[part 3 of 12: package /E40_Platform_System_SystemPackage/Components]
AUTOSAR XML (schema 4-2-1)
package /E40_Platform_System_SystemPackage/Components  (continued)
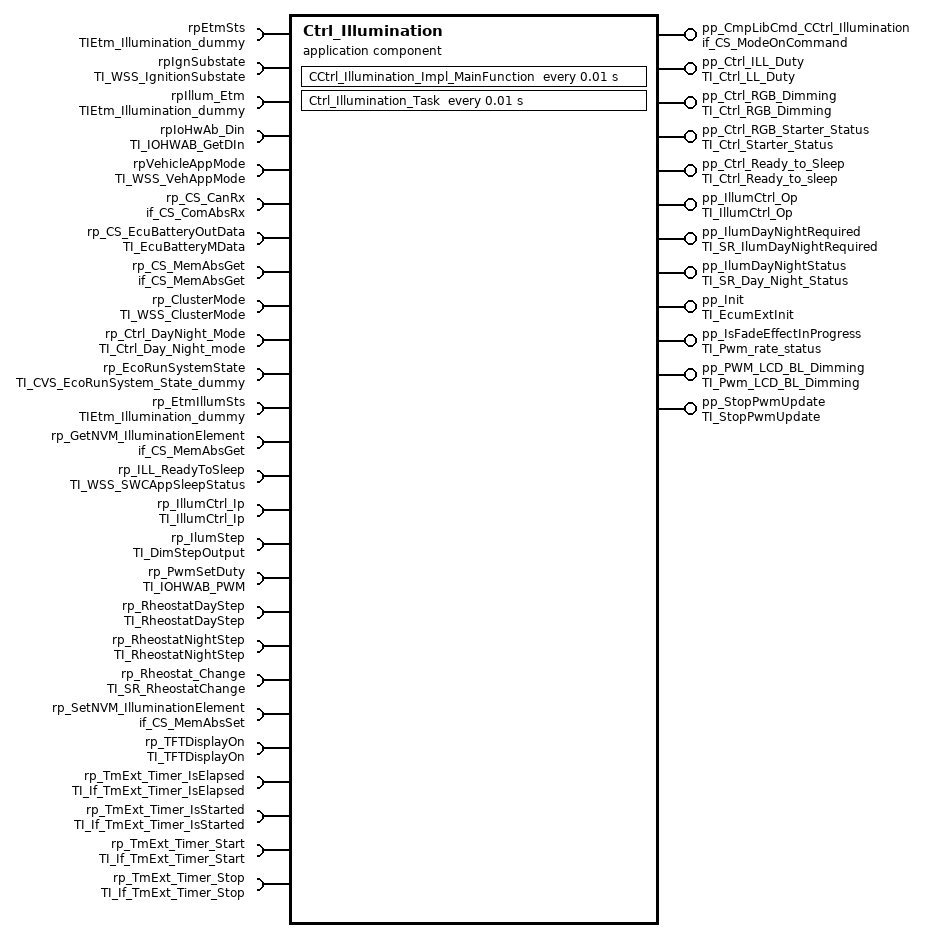
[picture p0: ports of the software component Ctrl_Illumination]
  application sw component type Ctrl_Illumination
    12 x provide port:
      pp_CmpLibCmd_CCtrl_Illumination: server-com-spec{operation=Impl_OnCommand, queue-length=1}, provided-interface=if_CS_ModeOnCommand
      pp_Ctrl_ILL_Duty: nonqueued-sender-com-spec{data-element=ILL_Duty, init-value=constant-reference=Ctrl_IlluminationILL_DutyValue0}, provided-interface=TI_Ctrl_LL_Duty
      pp_Ctrl_RGB_Dimming: nonqueued-sender-com-spec{data-element=RGB_Dimming, init-value=constant-reference=Ctrl_IlluminationRGB_DimmingValue0}, provided-interface=TI_Ctrl_RGB_Dimming
      pp_Ctrl_RGB_Starter_Status: nonqueued-sender-com-spec{data-element=Starter_Status, uses-end-to-end-protection=0, init-value=constant-reference=Ctrl_IlluminationStarter_StatusValue0}, provided-interface=TI_Ctrl_Starter_Status
      pp_Ctrl_Ready_to_Sleep: nonqueued-sender-com-spec{data-element=Ready_to_Sleep, uses-end-to-end-protection=0, init-value=constant-reference=Ctrl_IlluminationReady_to_SleepValue0}, provided-interface=TI_Ctrl_Ready_to_sleep
      pp_IllumCtrl_Op: nonqueued-sender-com-spec{data-element=IllumCtrl_Op_Data, init-value=constant-reference=Ctrl_IlluminationIllumCtrl_Op_DataValue0}, provided-interface=TI_IllumCtrl_Op
      pp_IlumDayNightRequired: nonqueued-sender-com-spec{data-element=IlumDayNightRequired, init-value=constant-reference=Ctrl_IlluminationIlumDayNightRequiredValue0}, provided-interface=TI_SR_IlumDayNightRequired
      pp_IlumDayNightStatus: nonqueued-sender-com-spec{data-element=Day_Night_Status, init-value=constant-reference=Ctrl_IlluminationDay_Night_StatusValue0}, provided-interface=TI_SR_Day_Night_Status
      pp_Init: server-com-spec{operation=TI_EcumExtInit/Init, queue-length=1}, provided-interface=TI_EcumExtInit
      pp_IsFadeEffectInProgress: server-com-spec{operation=PWM_Rate_Status, queue-length=1}, provided-interface=TI_Pwm_rate_status
      pp_PWM_LCD_BL_Dimming: nonqueued-sender-com-spec{data-element=BL_Dimming, init-value=constant-reference=Ctrl_IlluminationBL_DimmingValue0}, provided-interface=TI_Pwm_LCD_BL_Dimming
      pp_StopPwmUpdate: nonqueued-sender-com-spec{data-element=channel_id, init-value=constant-reference=Ctrl_Illuminationchannel_idValue0}, provided-interface=TI_StopPwmUpdate
    26 x require port:
      rpEtmSts: nonqueued-receiver-com-spec{data-element=IllumStatus, init-value=constant-reference=Ctrl_IlluminationIllumStatusValue0}, required-interface=TIEtm_Illumination_dummy
      rpIgnSubstate: nonqueued-receiver-com-spec{data-element=IgnitionSubstate, init-value=constant-reference=Ctrl_IlluminationIgnitionSubstateValue0}, required-interface=TI_WSS_IgnitionSubstate
      rpIllum_Etm: nonqueued-receiver-com-spec{data-element=IllumStatus, init-value=constant-reference=Ctrl_IlluminationIllumStatusValue0}, required-interface=TIEtm_Illumination_dummy
      rpIoHwAb_Din: required-interface=TI_IOHWAB_GetDIn
      rpVehicleAppMode: nonqueued-receiver-com-spec{data-element=WSSCurrentVehicleState, init-value=constant-reference=Ctrl_IlluminationWSSCurrentVehicleStateValue0}, required-interface=TI_WSS_VehAppMode
      rp_CS_CanRx: required-interface=if_CS_ComAbsRx
      rp_CS_EcuBatteryOutData: required-interface=TI_EcuBatteryMData
      rp_CS_MemAbsGet: required-interface=if_CS_MemAbsGet
      rp_ClusterMode: nonqueued-receiver-com-spec{data-element=WSSCurrentClusterMode, init-value=constant-reference=Ctrl_IlluminationWSSCurrentClusterModeValue0}, required-interface=TI_WSS_ClusterMode
      rp_Ctrl_DayNight_Mode: nonqueued-receiver-com-spec{data-element=Day_Night_mode_Ctrl, init-value=constant-reference=Ctrl_IlluminationDay_Night_mode_CtrlValue0}, required-interface=TI_Ctrl_Day_Night_mode
      rp_EcoRunSystemState: nonqueued-receiver-com-spec{data-element=EcoRunSystem_Flag, init-value=constant-reference=Ctrl_IlluminationEcoRunSystem_FlagValue0}, required-interface=TI_CVS_EcoRunSystem_State_dummy
      rp_EtmIllumSts: nonqueued-receiver-com-spec{data-element=IllumStatus, init-value=constant-reference=Ctrl_IlluminationIllumStatusValue0}, required-interface=TIEtm_Illumination_dummy
      rp_GetNVM_IlluminationElement: required-interface=if_CS_MemAbsGet
      rp_ILL_ReadyToSleep: required-interface=TI_WSS_SWCAppSleepStatus
      rp_IllumCtrl_Ip: nonqueued-receiver-com-spec{data-element=IllumCtrl_Ip_Data, init-value=constant-reference=Ctrl_IlluminationIllumCtrl_Ip_DataValue0}, required-interface=TI_IllumCtrl_Ip
      rp_IlumStep: nonqueued-receiver-com-spec{data-element=IllumStepValue, init-value=constant-reference=Ctrl_IlluminationIllumStepValueValue0}, required-interface=TI_DimStepOutput
      rp_PwmSetDuty: required-interface=TI_IOHWAB_PWM
      rp_RheostatDayStep: nonqueued-receiver-com-spec{data-element=RheostatDayStep, init-value=constant-reference=Ctrl_IlluminationRheostatDayStepValue0}, required-interface=TI_RheostatDayStep
      rp_RheostatNightStep: nonqueued-receiver-com-spec{data-element=RheostatNightStep, init-value=constant-reference=Ctrl_IlluminationRheostatNightStepValue0}, required-interface=TI_RheostatNightStep
      rp_Rheostat_Change: nonqueued-receiver-com-spec{data-element=RheoUpdateVal, init-value=constant-reference=Ctrl_IlluminationRheoUpdateValValue0}, required-interface=TI_SR_RheostatChange
      rp_SetNVM_IlluminationElement: required-interface=if_CS_MemAbsSet
      rp_TFTDisplayOn: nonqueued-receiver-com-spec{data-element=TFTDisplayOn, init-value=constant-reference=Ctrl_IlluminationTFTDisplayOnValue0}, required-interface=TI_TFTDisplayOn
      rp_TmExt_Timer_IsElapsed: required-interface=TI_If_TmExt_Timer_IsElapsed
      rp_TmExt_Timer_IsStarted: required-interface=TI_If_TmExt_Timer_IsStarted
      rp_TmExt_Timer_Start: required-interface=TI_If_TmExt_Timer_Start
      rp_TmExt_Timer_Stop: required-interface=TI_If_TmExt_Timer_Stop
    behavior IB_Ctrl_Illumination
      timing event TECCtrl_Illumination_Impl_MainFunction: start-on-event=CCtrl_Illumination_Impl_MainFunction, period=0.01
      operation invoked event OIE_pp_CmpLibCmd_CCtrl_Illumination_CCtrl_Illumination_Impl_OnCommandTrigByImpl_OnCommand: start-on-event=CCtrl_Illumination_Impl_OnCommand, operation=pp_CmpLibCmd_CCtrl_Illumination.Impl_OnCommand
      operation invoked event OIE_pp_Init_Ctrl_Illumination_InitTrigByInit: start-on-event=Ctrl_Illumination_Init, operation=pp_Init.Init
      operation invoked event OIE_pp_IsFadeEffectInProgress_Ctrl_Illumination_PWM_Rate_StatusTrigByPWM_Rate_Status: start-on-event=Ctrl_Illumination_PWM_Rate_Status, operation=pp_IsFadeEffectInProgress.PWM_Rate_Status
      timing event TECtrl_Illumination_Task: start-on-event=Ctrl_Illumination_Task, period=0.01
      port-api-options:
        enable-take-address=false, indirect-api=false, port=pp_CmpLibCmd_CCtrl_Illumination
        enable-take-address=false, indirect-api=false, port=pp_Ctrl_ILL_Duty
        enable-take-address=false, indirect-api=false, port=pp_Ctrl_RGB_Dimming
        enable-take-address=false, indirect-api=false, port=pp_Ctrl_RGB_Starter_Status
        enable-take-address=false, indirect-api=false, port=pp_Ctrl_Ready_to_Sleep
        enable-take-address=false, indirect-api=false, port=pp_IllumCtrl_Op
        enable-take-address=false, indirect-api=false, port=Ctrl_Illumination/pp_IlumDayNightRequired
        enable-take-address=false, indirect-api=false, port=Ctrl_Illumination/pp_IlumDayNightStatus
        enable-take-address=false, indirect-api=false, port=Ctrl_Illumination/pp_Init
        enable-take-address=false, indirect-api=false, port=pp_IsFadeEffectInProgress
        enable-take-address=false, indirect-api=false, port=pp_PWM_LCD_BL_Dimming
        enable-take-address=false, indirect-api=false, port=pp_StopPwmUpdate
        enable-take-address=false, indirect-api=false, port=Ctrl_Illumination/rpEtmSts
        enable-take-address=false, indirect-api=false, port=Ctrl_Illumination/rpIgnSubstate
        enable-take-address=false, indirect-api=false, port=Ctrl_Illumination/rpIllum_Etm
        enable-take-address=false, indirect-api=false, port=Ctrl_Illumination/rpIoHwAb_Din
        enable-take-address=false, indirect-api=false, port=Ctrl_Illumination/rpVehicleAppMode
        enable-take-address=false, indirect-api=false, port=Ctrl_Illumination/rp_CS_CanRx
        enable-take-address=false, indirect-api=false, port=Ctrl_Illumination/rp_CS_EcuBatteryOutData
        enable-take-address=false, indirect-api=false, port=Ctrl_Illumination/rp_CS_MemAbsGet
        enable-take-address=false, indirect-api=false, port=Ctrl_Illumination/rp_ClusterMode
        enable-take-address=false, indirect-api=false, port=rp_Ctrl_DayNight_Mode
        enable-take-address=false, indirect-api=false, port=Ctrl_Illumination/rp_EcoRunSystemState
        enable-take-address=false, indirect-api=false, port=Ctrl_Illumination/rp_EtmIllumSts
        enable-take-address=false, indirect-api=false, port=Ctrl_Illumination/rp_GetNVM_IlluminationElement
        enable-take-address=false, indirect-api=false, port=Ctrl_Illumination/rp_ILL_ReadyToSleep
        enable-take-address=false, indirect-api=false, port=rp_IllumCtrl_Ip
        enable-take-address=false, indirect-api=false, port=rp_IlumStep
        enable-take-address=false, indirect-api=false, port=Ctrl_Illumination/rp_PwmSetDuty
        enable-take-address=false, indirect-api=false, port=Ctrl_Illumination/rp_RheostatDayStep
        enable-take-address=false, indirect-api=false, port=Ctrl_Illumination/rp_RheostatNightStep
        enable-take-address=false, indirect-api=false, port=Ctrl_Illumination/rp_Rheostat_Change
        enable-take-address=false, indirect-api=false, port=Ctrl_Illumination/rp_SetNVM_IlluminationElement
        enable-take-address=false, indirect-api=false, port=Ctrl_Illumination/rp_TFTDisplayOn
        enable-take-address=false, indirect-api=false, port=Ctrl_Illumination/rp_TmExt_Timer_IsElapsed
        enable-take-address=false, indirect-api=false, port=Ctrl_Illumination/rp_TmExt_Timer_IsStarted
        enable-take-address=false, indirect-api=false, port=Ctrl_Illumination/rp_TmExt_Timer_Start
        enable-take-address=false, indirect-api=false, port=Ctrl_Illumination/rp_TmExt_Timer_Stop
      5 x runnable, all with can-be-invoked-concurrently=true:
        CCtrl_Illumination_Impl_MainFunction
          data-receive-point-by-arguments:
            14 x access:
              DRA_rpEtmSts_IllumStatus: accessed-variable=rpEtmSts.IllumStatus
              DRA_rpIgnSubstate_IgnitionSubstate: accessed-variable=rpIgnSubstate.IgnitionSubstate
              DRA_rpIllum_Etm_IllumStatus: accessed-variable=rpIllum_Etm.IllumStatus
              DRA_rpVehicleAppMode_WSSCurrentVehicleState: accessed-variable=rpVehicleAppMode.WSSCurrentVehicleState
              DRA_rp_ClusterMode_WSSCurrentClusterMode: accessed-variable=rp_ClusterMode.WSSCurrentClusterMode
              DRA_rp_Ctrl_DayNight_Mode_Day_Night_mode_Ctrl: accessed-variable=rp_Ctrl_DayNight_Mode.Day_Night_mode_Ctrl
              DRA_rp_EcoRunSystemState_EcoRunSystem_Flag: accessed-variable=rp_EcoRunSystemState.EcoRunSystem_Flag
              DRA_rp_EtmIllumSts_IllumStatus: accessed-variable=rp_EtmIllumSts.IllumStatus
              DRA_rp_IllumCtrl_Ip_IllumCtrl_Ip_Data: accessed-variable=rp_IllumCtrl_Ip.IllumCtrl_Ip_Data
              DRA_rp_IlumStep_IllumStepValue: accessed-variable=rp_IlumStep.IllumStepValue
              DRA_rp_RheostatDayStep_RheostatDayStep: accessed-variable=rp_RheostatDayStep.RheostatDayStep
              DRA_rp_RheostatNightStep_RheostatNightStep: accessed-variable=rp_RheostatNightStep.RheostatNightStep
              DRA_rp_Rheostat_Change_RheoUpdateVal: accessed-variable=rp_Rheostat_Change.RheoUpdateVal
              DRA_rp_TFTDisplayOn_TFTDisplayOn: accessed-variable=rp_TFTDisplayOn.TFTDisplayOn
          data-send-points:
            9 x access:
              DWA_pp_Ctrl_ILL_Duty_ILL_Duty: accessed-variable=pp_Ctrl_ILL_Duty.ILL_Duty
              DWA_pp_Ctrl_RGB_Dimming_RGB_Dimming: accessed-variable=pp_Ctrl_RGB_Dimming.RGB_Dimming
              DWA_pp_Ctrl_RGB_Starter_Status_Starter_Status: accessed-variable=pp_Ctrl_RGB_Starter_Status.Starter_Status
              DWA_pp_Ctrl_Ready_to_Sleep_Ready_to_Sleep: accessed-variable=pp_Ctrl_Ready_to_Sleep.Ready_to_Sleep
              DWA_pp_IllumCtrl_Op_IllumCtrl_Op_Data: accessed-variable=pp_IllumCtrl_Op.IllumCtrl_Op_Data
              DWA_pp_IlumDayNightRequired_IlumDayNightRequired: accessed-variable=pp_IlumDayNightRequired.IlumDayNightRequired
              DWA_pp_IlumDayNightStatus_Day_Night_Status: accessed-variable=pp_IlumDayNightStatus.Day_Night_Status
              DWA_pp_PWM_LCD_BL_Dimming_BL_Dimming: accessed-variable=pp_PWM_LCD_BL_Dimming.BL_Dimming
              DWA_pp_StopPwmUpdate_channel_id: accessed-variable=pp_StopPwmUpdate.channel_id
          305 x sync call, all with timeout=0.0:
            OA_rpIoHwAb_Din_GetAsyncRawInput: operation=rpIoHwAb_Din.GetAsyncRawInput
            OA_rpIoHwAb_Din_GetProcessedInput: operation=rpIoHwAb_Din.GetProcessedInput
            OA_rpIoHwAb_Din_GetSyncRawInput: operation=rpIoHwAb_Din.GetSyncRawInput
            OA_rpIoHwAb_Din_GetInputGroup: operation=rpIoHwAb_Din.GetInputGroup
            OA_rp_CS_CanRx_RxCan_GetSignalValueU8Arr: operation=rp_CS_CanRx.RxCan_GetSignalValueU8Arr
            OA_rp_CS_CanRx_RxCan_SetSignalInitValue: operation=rp_CS_CanRx.RxCan_SetSignalInitValue
            OA_rp_CS_CanRx_RxCan_SetSignalInitValueU8Arr: operation=rp_CS_CanRx.RxCan_SetSignalInitValueU8Arr
            OA_rp_CS_CanRx_RxCan_SignalInvalidProcessingControl: operation=rp_CS_CanRx.RxCan_SignalInvalidProcessingControl
            OA_rp_CS_CanRx_RxCan_SignalMissingProcessingControl: operation=rp_CS_CanRx.RxCan_SignalMissingProcessingControl
            OA_rp_CS_CanRx_RxCan_SignalNRProcessingControl: operation=rp_CS_CanRx.RxCan_SignalNRProcessingControl
            OA_rp_CS_CanRx_RxCan_SignalGetJustRcvdStatus: operation=rp_CS_CanRx.RxCan_SignalGetJustRcvdStatus
            OA_rp_CS_CanRx_RxCan_SignalClearJustRcvdStatus: operation=rp_CS_CanRx.RxCan_SignalClearJustRcvdStatus
            OA_rp_CS_CanRx_RxCan_GetSignalValue: operation=rp_CS_CanRx.RxCan_GetSignalValue
            OA_rp_CS_EcuBatteryOutData_EcuBatteryM_GetChannelStatus: operation=rp_CS_EcuBatteryOutData.EcuBatteryM_GetChannelStatus
            OA_rp_CS_EcuBatteryOutData_EcuBatteryM_GetDIOStatus: operation=rp_CS_EcuBatteryOutData.EcuBatteryM_GetDIOStatus
            OA_rp_CS_MemAbsGet_Get_BsShare_SwUpdReflash_Element: operation=rp_CS_MemAbsGet.Get_BsShare_SwUpdReflash_Element
            OA_rp_CS_MemAbsGet_Get_BsShare_SwUpdFotaMode_Element: operation=rp_CS_MemAbsGet.Get_BsShare_SwUpdFotaMode_Element
            OA_rp_CS_MemAbsGet_Get_BsShare_SwUpdFotaFinPrint_Element: operation=rp_CS_MemAbsGet.Get_BsShare_SwUpdFotaFinPrint_Element
            OA_rp_CS_MemAbsGet_Get_BsShare_SwUpdFotaStatus_Element: operation=rp_CS_MemAbsGet.Get_BsShare_SwUpdFotaStatus_Element
            OA_rp_CS_MemAbsGet_Get_BsShare_SwUpdFotadecrypt_Element: operation=rp_CS_MemAbsGet.Get_BsShare_SwUpdFotadecrypt_Element
            OA_rp_CS_MemAbsGet_Get_BsShare_EcuPartNumber_Element: operation=rp_CS_MemAbsGet.Get_BsShare_EcuPartNumber_Element
            OA_rp_CS_MemAbsGet_Get_BsShare_VisteonPartNumber: operation=rp_CS_MemAbsGet.Get_BsShare_VisteonPartNumber
            OA_rp_CS_MemAbsGet_Get_BsShare_VisteonPCBPartNumber: operation=rp_CS_MemAbsGet.Get_BsShare_VisteonPCBPartNumber
            OA_rp_CS_MemAbsGet_Get_BsShare_ProductSerialNumber: operation=rp_CS_MemAbsGet.Get_BsShare_ProductSerialNumber
            OA_rp_CS_MemAbsGet_Get_BsShare_PCBSerialNumber: operation=rp_CS_MemAbsGet.Get_BsShare_PCBSerialNumber
            OA_rp_CS_MemAbsGet_Get_BsShare_SMTManufacturingDate: operation=rp_CS_MemAbsGet.Get_BsShare_SMTManufacturingDate
            OA_rp_CS_MemAbsGet_Get_BsShare_AssemblyManufacturingDate: operation=rp_CS_MemAbsGet.Get_BsShare_AssemblyManufacturingDate
            OA_rp_CS_MemAbsGet_Get_BsShare_SMTPlantNumber: operation=rp_CS_MemAbsGet.Get_BsShare_SMTPlantNumber
            OA_rp_CS_MemAbsGet_Get_BsShare_AssemblyPlantNumber: operation=rp_CS_MemAbsGet.Get_BsShare_AssemblyPlantNumber
            OA_rp_CS_MemAbsGet_Get_BsShare_HWModification: operation=rp_CS_MemAbsGet.Get_BsShare_HWModification
            OA_rp_CS_MemAbsGet_Get_BsShare_VisMeet_Element: operation=rp_CS_MemAbsGet.Get_BsShare_VisMeet_Element
            OA_rp_CS_MemAbsGet_Get_BsShare_VisMeet_EOLEntry_Element: operation=rp_CS_MemAbsGet.Get_BsShare_VisMeet_EOLEntry_Element
            OA_rp_CS_MemAbsGet_Get_BsShare_VehicleConfig_Element: operation=rp_CS_MemAbsGet.Get_BsShare_VehicleConfig_Element
            OA_rp_CS_MemAbsGet_Get_BsConst_SpeedoGauge_Element: operation=rp_CS_MemAbsGet.Get_BsConst_SpeedoGauge_Element
            OA_rp_CS_MemAbsGet_Get_BsConst_TachoGauge_Element: operation=rp_CS_MemAbsGet.Get_BsConst_TachoGauge_Element
            OA_rp_CS_MemAbsGet_Get_BsConst_FuelGauge_Element: operation=rp_CS_MemAbsGet.Get_BsConst_FuelGauge_Element
            OA_rp_CS_MemAbsGet_Get_BsConst_TempGauge_Element: operation=rp_CS_MemAbsGet.Get_BsConst_TempGauge_Element
            OA_rp_CS_MemAbsGet_Get_BsConst_PowerGauge_Element: operation=rp_CS_MemAbsGet.Get_BsConst_PowerGauge_Element
            OA_rp_CS_MemAbsGet_Get_BsConst_OilGauge_Element: operation=rp_CS_MemAbsGet.Get_BsConst_OilGauge_Element
            OA_rp_CS_MemAbsGet_Get_BsConst_TripComputer_Element: operation=rp_CS_MemAbsGet.Get_BsConst_TripComputer_Element
            OA_rp_CS_MemAbsGet_Get_BsConst_Compensation_Line_Slope_m: operation=rp_CS_MemAbsGet.Get_BsConst_Compensation_Line_Slope_m
            OA_rp_CS_MemAbsGet_Get_BsConst_Compensation_Line_Shift_b: operation=rp_CS_MemAbsGet.Get_BsConst_Compensation_Line_Shift_b
            OA_rp_CS_MemAbsGet_Get_BsConst_Lookup_Curve_HotSpot_Coef_X: operation=rp_CS_MemAbsGet.Get_BsConst_Lookup_Curve_HotSpot_Coef_X
            OA_rp_CS_MemAbsGet_Get_BsConst_Lookup_Curve_HotSpot_Coef_Y: operation=rp_CS_MemAbsGet.Get_BsConst_Lookup_Curve_HotSpot_Coef_Y
            OA_rp_CS_MemAbsGet_Get_BsConst_Temp_Threshold_Hysteresis_Derating: operation=rp_CS_MemAbsGet.Get_BsConst_Temp_Threshold_Hysteresis_Derating
            OA_rp_CS_MemAbsGet_Get_BsConst_Derating_Backlight_Disable: operation=rp_CS_MemAbsGet.Get_BsConst_Derating_Backlight_Disable
            OA_rp_CS_MemAbsGet_Get_BsConst_Temperature_Sensor_Conv: operation=rp_CS_MemAbsGet.Get_BsConst_Temperature_Sensor_Conv
            OA_rp_CS_MemAbsGet_Get_BsConst_PCB_Temperature_Sensor_Conv: operation=rp_CS_MemAbsGet.Get_BsConst_PCB_Temperature_Sensor_Conv
            OA_rp_CS_MemAbsGet_Get_BsConst_Display_Illum_Max_Level: operation=rp_CS_MemAbsGet.Get_BsConst_Display_Illum_Max_Level
            OA_rp_CS_MemAbsGet_Get_BsConst_PWM_boost_bypass_duty: operation=rp_CS_MemAbsGet.Get_BsConst_PWM_boost_bypass_duty
            OA_rp_CS_MemAbsGet_Get_BsConst_BsConst_Illumination_ReservedByte: operation=rp_CS_MemAbsGet.Get_BsConst_BsConst_Illumination_ReservedByte
            OA_rp_CS_MemAbsGet_Get_BsConst_Compensation_Line_Slope_m_SafeCopy1: operation=rp_CS_MemAbsGet.Get_BsConst_Compensation_Line_Slope_m_SafeCopy1
            OA_rp_CS_MemAbsGet_Get_BsConst_Compensation_Line_Shift_b_SafeCopy1: operation=rp_CS_MemAbsGet.Get_BsConst_Compensation_Line_Shift_b_SafeCopy1
            OA_rp_CS_MemAbsGet_Get_BsConst_Lookup_Curve_HotSpot_Coef_X_SafeCopy1: operation=rp_CS_MemAbsGet.Get_BsConst_Lookup_Curve_HotSpot_Coef_X_SafeCopy1
            OA_rp_CS_MemAbsGet_Get_BsConst_Lookup_Curve_HotSpot_Coef_Y_SafeCopy1: operation=rp_CS_MemAbsGet.Get_BsConst_Lookup_Curve_HotSpot_Coef_Y_SafeCopy1
            OA_rp_CS_MemAbsGet_Get_BsConst_Temp_Threshold_Hysteresis_Derating_SafeCopy1: operation=rp_CS_MemAbsGet.Get_BsConst_Temp_Threshold_Hysteresis_Derating_SafeCopy1
            OA_rp_CS_MemAbsGet_Get_BsConst_Derating_Backlight_Disable_SafeCopy1: operation=rp_CS_MemAbsGet.Get_BsConst_Derating_Backlight_Disable_SafeCopy1
            OA_rp_CS_MemAbsGet_Get_BsConst_Temperature_Sensor_Conv_SafeCopy1: operation=rp_CS_MemAbsGet.Get_BsConst_Temperature_Sensor_Conv_SafeCopy1
            OA_rp_CS_MemAbsGet_Get_BsConst_PCB_Temperature_Sensor_Conv_SafeCopy1: operation=rp_CS_MemAbsGet.Get_BsConst_PCB_Temperature_Sensor_Conv_SafeCopy1
            OA_rp_CS_MemAbsGet_Get_BsConst_Display_Illum_Max_Level_SafeCopy1: operation=rp_CS_MemAbsGet.Get_BsConst_Display_Illum_Max_Level_SafeCopy1
            OA_rp_CS_MemAbsGet_Get_BsConst_PWM_boost_bypass_duty_SafeCopy1: operation=rp_CS_MemAbsGet.Get_BsConst_PWM_boost_bypass_duty_SafeCopy1
            OA_rp_CS_MemAbsGet_Get_BsConst_BsConst_Illumination_ReservedByte_SafeCopy1: operation=rp_CS_MemAbsGet.Get_BsConst_BsConst_Illumination_ReservedByte_SafeCopy1
            OA_rp_CS_MemAbsGet_Get_BsConst_Compensation_Line_Slope_m_SafeCopy2: operation=rp_CS_MemAbsGet.Get_BsConst_Compensation_Line_Slope_m_SafeCopy2
            OA_rp_CS_MemAbsGet_Get_BsConst_Compensation_Line_Shift_b_SafeCopy2: operation=rp_CS_MemAbsGet.Get_BsConst_Compensation_Line_Shift_b_SafeCopy2
            OA_rp_CS_MemAbsGet_Get_BsConst_Lookup_Curve_HotSpot_Coef_X_SafeCopy2: operation=rp_CS_MemAbsGet.Get_BsConst_Lookup_Curve_HotSpot_Coef_X_SafeCopy2
            OA_rp_CS_MemAbsGet_Get_BsConst_Lookup_Curve_HotSpot_Coef_Y_SafeCopy2: operation=rp_CS_MemAbsGet.Get_BsConst_Lookup_Curve_HotSpot_Coef_Y_SafeCopy2
            OA_rp_CS_MemAbsGet_Get_BsConst_Temp_Threshold_Hysteresis_Derating_SafeCopy2: operation=rp_CS_MemAbsGet.Get_BsConst_Temp_Threshold_Hysteresis_Derating_SafeCopy2
            OA_rp_CS_MemAbsGet_Get_BsConst_Derating_Backlight_Disable_SafeCopy2: operation=rp_CS_MemAbsGet.Get_BsConst_Derating_Backlight_Disable_SafeCopy2
            OA_rp_CS_MemAbsGet_Get_BsConst_Temperature_Sensor_Conv_SafeCopy2: operation=rp_CS_MemAbsGet.Get_BsConst_Temperature_Sensor_Conv_SafeCopy2
            OA_rp_CS_MemAbsGet_Get_BsConst_PCB_Temperature_Sensor_Conv_SafeCopy2: operation=rp_CS_MemAbsGet.Get_BsConst_PCB_Temperature_Sensor_Conv_SafeCopy2
            OA_rp_CS_MemAbsGet_Get_BsConst_Display_Illum_Max_Level_SafeCopy2: operation=rp_CS_MemAbsGet.Get_BsConst_Display_Illum_Max_Level_SafeCopy2
            OA_rp_CS_MemAbsGet_Get_BsConst_PWM_boost_bypass_duty_SafeCopy2: operation=rp_CS_MemAbsGet.Get_BsConst_PWM_boost_bypass_duty_SafeCopy2
            OA_rp_CS_MemAbsGet_Get_BsConst_BsConst_Illumination_ReservedByte_SafeCopy2: operation=rp_CS_MemAbsGet.Get_BsConst_BsConst_Illumination_ReservedByte_SafeCopy2
            OA_rp_CS_MemAbsGet_Get_BsConst_Audio_Element: operation=rp_CS_MemAbsGet.Get_BsConst_Audio_Element
            OA_rp_CS_MemAbsGet_Get_BsConst_Warning_Element: operation=rp_CS_MemAbsGet.Get_BsConst_Warning_Element
            OA_rp_CS_MemAbsGet_Get_BsConst_RealTimeClock_Element: operation=rp_CS_MemAbsGet.Get_BsConst_RealTimeClock_Element
            OA_rp_CS_MemAbsGet_Get_BsConst_Communication_Element: operation=rp_CS_MemAbsGet.Get_BsConst_Communication_Element
            OA_rp_CS_MemAbsGet_Get_BsConst_Power_Element: operation=rp_CS_MemAbsGet.Get_BsConst_Power_Element
            OA_rp_CS_MemAbsGet_Get_BsConst_ServiceReminder_Element: operation=rp_CS_MemAbsGet.Get_BsConst_ServiceReminder_Element
            OA_rp_CS_MemAbsGet_Get_BsConst_EngOffTimer_Element: operation=rp_CS_MemAbsGet.Get_BsConst_EngOffTimer_Element
            OA_rp_CS_MemAbsGet_Get_BsCys_Certicificate_Element: operation=rp_CS_MemAbsGet.Get_BsCys_Certicificate_Element
            OA_rp_CS_MemAbsGet_Get_RefCys_Certicificate_Element: operation=rp_CS_MemAbsGet.Get_RefCys_Certicificate_Element
            OA_rp_CS_MemAbsGet_Get_RefCys_Certicificate1_Element: operation=rp_CS_MemAbsGet.Get_RefCys_Certicificate1_Element
            OA_rp_CS_MemAbsGet_Get_BsRt_Odometer_Element: operation=rp_CS_MemAbsGet.Get_BsRt_Odometer_Element
            OA_rp_CS_MemAbsGet_Get_BsRt_SpeedoGauge_Element: operation=rp_CS_MemAbsGet.Get_BsRt_SpeedoGauge_Element
            OA_rp_CS_MemAbsGet_Get_BsRt_TachoGauge_Element: operation=rp_CS_MemAbsGet.Get_BsRt_TachoGauge_Element
            OA_rp_CS_MemAbsGet_Get_BsRt_FuelGauge_Element: operation=rp_CS_MemAbsGet.Get_BsRt_FuelGauge_Element
            OA_rp_CS_MemAbsGet_Get_BsRt_TempGauge_Element: operation=rp_CS_MemAbsGet.Get_BsRt_TempGauge_Element
            OA_rp_CS_MemAbsGet_Get_BsRt_PowerGauge_Element: operation=rp_CS_MemAbsGet.Get_BsRt_PowerGauge_Element
            OA_rp_CS_MemAbsGet_Get_BsRt_OilGauge_Element: operation=rp_CS_MemAbsGet.Get_BsRt_OilGauge_Element
            OA_rp_CS_MemAbsGet_Get_BsRt_TripComputer_Element: operation=rp_CS_MemAbsGet.Get_BsRt_TripComputer_Element
            OA_rp_CS_MemAbsGet_Get_BsRt_Warning_Element: operation=rp_CS_MemAbsGet.Get_BsRt_Warning_Element
            OA_rp_CS_MemAbsGet_Get_BsRt_RealTimeClock_Element: operation=rp_CS_MemAbsGet.Get_BsRt_RealTimeClock_Element
            OA_rp_CS_MemAbsGet_Get_BsRt_Personalization_Element: operation=rp_CS_MemAbsGet.Get_BsRt_Personalization_Element
            OA_rp_CS_MemAbsGet_Get_BsRt_Illumination_Element: operation=rp_CS_MemAbsGet.Get_BsRt_Illumination_Element
            OA_rp_CS_MemAbsGet_Get_BsRt_CusDlt_Element: operation=rp_CS_MemAbsGet.Get_BsRt_CusDlt_Element
            OA_rp_CS_MemAbsGet_Get_BsReten_Odometer_Element: operation=rp_CS_MemAbsGet.Get_BsReten_Odometer_Element
            OA_rp_CS_MemAbsGet_Get_BsReten_Gauges_Element: operation=rp_CS_MemAbsGet.Get_BsReten_Gauges_Element
            OA_rp_CS_MemAbsGet_Get_BsReten_Tripcomputer_Element: operation=rp_CS_MemAbsGet.Get_BsReten_Tripcomputer_Element
            OA_rp_CS_MemAbsGet_Get_BsReten_Illumination_Element: operation=rp_CS_MemAbsGet.Get_BsReten_Illumination_Element
            OA_rp_CS_MemAbsGet_Get_BsReten_Audio_Element: operation=rp_CS_MemAbsGet.Get_BsReten_Audio_Element
            OA_rp_CS_MemAbsGet_Get_BsReten_Warning_Element: operation=rp_CS_MemAbsGet.Get_BsReten_Warning_Element
            OA_rp_CS_MemAbsGet_Get_BsReten_RealTimeClock_Element: operation=rp_CS_MemAbsGet.Get_BsReten_RealTimeClock_Element
            OA_rp_CS_MemAbsGet_Get_BsReten_Communication_Element: operation=rp_CS_MemAbsGet.Get_BsReten_Communication_Element
            OA_rp_CS_MemAbsGet_Get_BsReten_Personalization_Element: operation=rp_CS_MemAbsGet.Get_BsReten_Personalization_Element
            OA_rp_CS_MemAbsGet_Get_BsReten_Power_Element: operation=rp_CS_MemAbsGet.Get_BsReten_Power_Element
            OA_rp_CS_MemAbsGet_Get_BsReten_Display_Element: operation=rp_CS_MemAbsGet.Get_BsReten_Display_Element
            OA_rp_CS_MemAbsGet_Get_BsDiag_ErrorRecord_Element: operation=rp_CS_MemAbsGet.Get_BsDiag_ErrorRecord_Element
            OA_rp_CS_MemAbsGet_Get_BsDiag_Dtc_Element: operation=rp_CS_MemAbsGet.Get_BsDiag_Dtc_Element
            OA_rp_GetNVM_IlluminationElement_Get_BsShare_SwUpdReflash_Element: operation=rp_GetNVM_IlluminationElement.Get_BsShare_SwUpdReflash_Element
            OA_rp_GetNVM_IlluminationElement_Get_BsShare_SwUpdFotaMode_Element: operation=rp_GetNVM_IlluminationElement.Get_BsShare_SwUpdFotaMode_Element
            OA_rp_GetNVM_IlluminationElement_Get_BsShare_SwUpdFotaFinPrint_Element: operation=rp_GetNVM_IlluminationElement.Get_BsShare_SwUpdFotaFinPrint_Element
            OA_rp_GetNVM_IlluminationElement_Get_BsShare_SwUpdFotaStatus_Element: operation=rp_GetNVM_IlluminationElement.Get_BsShare_SwUpdFotaStatus_Element
            OA_rp_GetNVM_IlluminationElement_Get_BsShare_SwUpdFotadecrypt_Element: operation=rp_GetNVM_IlluminationElement.Get_BsShare_SwUpdFotadecrypt_Element
            OA_rp_GetNVM_IlluminationElement_Get_BsShare_EcuPartNumber_Element: operation=rp_GetNVM_IlluminationElement.Get_BsShare_EcuPartNumber_Element
            OA_rp_GetNVM_IlluminationElement_Get_BsShare_VisteonPartNumber: operation=rp_GetNVM_IlluminationElement.Get_BsShare_VisteonPartNumber
            OA_rp_GetNVM_IlluminationElement_Get_BsShare_VisteonPCBPartNumber: operation=rp_GetNVM_IlluminationElement.Get_BsShare_VisteonPCBPartNumber
            OA_rp_GetNVM_IlluminationElement_Get_BsShare_ProductSerialNumber: operation=rp_GetNVM_IlluminationElement.Get_BsShare_ProductSerialNumber
            OA_rp_GetNVM_IlluminationElement_Get_BsShare_PCBSerialNumber: operation=rp_GetNVM_IlluminationElement.Get_BsShare_PCBSerialNumber
            OA_rp_GetNVM_IlluminationElement_Get_BsShare_SMTManufacturingDate: operation=rp_GetNVM_IlluminationElement.Get_BsShare_SMTManufacturingDate
            OA_rp_GetNVM_IlluminationElement_Get_BsShare_AssemblyManufacturingDate: operation=rp_GetNVM_IlluminationElement.Get_BsShare_AssemblyManufacturingDate
            OA_rp_GetNVM_IlluminationElement_Get_BsShare_SMTPlantNumber: operation=rp_GetNVM_IlluminationElement.Get_BsShare_SMTPlantNumber
            OA_rp_GetNVM_IlluminationElement_Get_BsShare_AssemblyPlantNumber: operation=rp_GetNVM_IlluminationElement.Get_BsShare_AssemblyPlantNumber
            OA_rp_GetNVM_IlluminationElement_Get_BsShare_HWModification: operation=rp_GetNVM_IlluminationElement.Get_BsShare_HWModification
            OA_rp_GetNVM_IlluminationElement_Get_BsShare_VisMeet_Element: operation=rp_GetNVM_IlluminationElement.Get_BsShare_VisMeet_Element
            OA_rp_GetNVM_IlluminationElement_Get_BsShare_VisMeet_EOLEntry_Element: operation=rp_GetNVM_IlluminationElement.Get_BsShare_VisMeet_EOLEntry_Element
            OA_rp_GetNVM_IlluminationElement_Get_BsShare_VehicleConfig_Element: operation=rp_GetNVM_IlluminationElement.Get_BsShare_VehicleConfig_Element
            OA_rp_GetNVM_IlluminationElement_Get_BsConst_SpeedoGauge_Element: operation=rp_GetNVM_IlluminationElement.Get_BsConst_SpeedoGauge_Element
            OA_rp_GetNVM_IlluminationElement_Get_BsConst_TachoGauge_Element: operation=rp_GetNVM_IlluminationElement.Get_BsConst_TachoGauge_Element
            OA_rp_GetNVM_IlluminationElement_Get_BsConst_FuelGauge_Element: operation=rp_GetNVM_IlluminationElement.Get_BsConst_FuelGauge_Element
            OA_rp_GetNVM_IlluminationElement_Get_BsConst_TempGauge_Element: operation=rp_GetNVM_IlluminationElement.Get_BsConst_TempGauge_Element
            OA_rp_GetNVM_IlluminationElement_Get_BsConst_PowerGauge_Element: operation=rp_GetNVM_IlluminationElement.Get_BsConst_PowerGauge_Element
            OA_rp_GetNVM_IlluminationElement_Get_BsConst_OilGauge_Element: operation=rp_GetNVM_IlluminationElement.Get_BsConst_OilGauge_Element
            OA_rp_GetNVM_IlluminationElement_Get_BsConst_TripComputer_Element: operation=rp_GetNVM_IlluminationElement.Get_BsConst_TripComputer_Element
            OA_rp_GetNVM_IlluminationElement_Get_BsConst_Compensation_Line_Slope_m: operation=rp_GetNVM_IlluminationElement.Get_BsConst_Compensation_Line_Slope_m
            OA_rp_GetNVM_IlluminationElement_Get_BsConst_Compensation_Line_Shift_b: operation=rp_GetNVM_IlluminationElement.Get_BsConst_Compensation_Line_Shift_b
            OA_rp_GetNVM_IlluminationElement_Get_BsConst_Lookup_Curve_HotSpot_Coef_X: operation=rp_GetNVM_IlluminationElement.Get_BsConst_Lookup_Curve_HotSpot_Coef_X
            OA_rp_GetNVM_IlluminationElement_Get_BsConst_Lookup_Curve_HotSpot_Coef_Y: operation=rp_GetNVM_IlluminationElement.Get_BsConst_Lookup_Curve_HotSpot_Coef_Y
            OA_rp_GetNVM_IlluminationElement_Get_BsConst_Temp_Threshold_Hysteresis_Derating: operation=rp_GetNVM_IlluminationElement.Get_BsConst_Temp_Threshold_Hysteresis_Derating
            OA_rp_GetNVM_IlluminationElement_Get_BsConst_Derating_Backlight_Disable: operation=rp_GetNVM_IlluminationElement.Get_BsConst_Derating_Backlight_Disable
            OA_rp_GetNVM_IlluminationElement_Get_BsConst_Temperature_Sensor_Conv: operation=rp_GetNVM_IlluminationElement.Get_BsConst_Temperature_Sensor_Conv
            OA_rp_GetNVM_IlluminationElement_Get_BsConst_PCB_Temperature_Sensor_Conv: operation=rp_GetNVM_IlluminationElement.Get_BsConst_PCB_Temperature_Sensor_Conv
            OA_rp_GetNVM_IlluminationElement_Get_BsConst_Display_Illum_Max_Level: operation=rp_GetNVM_IlluminationElement.Get_BsConst_Display_Illum_Max_Level
            OA_rp_GetNVM_IlluminationElement_Get_BsConst_PWM_boost_bypass_duty: operation=rp_GetNVM_IlluminationElement.Get_BsConst_PWM_boost_bypass_duty
            OA_rp_GetNVM_IlluminationElement_Get_BsConst_BsConst_Illumination_ReservedByte: operation=rp_GetNVM_IlluminationElement.Get_BsConst_BsConst_Illumination_ReservedByte
            OA_rp_GetNVM_IlluminationElement_Get_BsConst_Compensation_Line_Slope_m_SafeCopy1: operation=rp_GetNVM_IlluminationElement.Get_BsConst_Compensation_Line_Slope_m_SafeCopy1
            OA_rp_GetNVM_IlluminationElement_Get_BsConst_Compensation_Line_Shift_b_SafeCopy1: operation=rp_GetNVM_IlluminationElement.Get_BsConst_Compensation_Line_Shift_b_SafeCopy1
            OA_rp_GetNVM_IlluminationElement_Get_BsConst_Lookup_Curve_HotSpot_Coef_X_SafeCopy1: operation=rp_GetNVM_IlluminationElement.Get_BsConst_Lookup_Curve_HotSpot_Coef_X_SafeCopy1
            OA_rp_GetNVM_IlluminationElement_Get_BsConst_Lookup_Curve_HotSpot_Coef_Y_SafeCopy1: operation=rp_GetNVM_IlluminationElement.Get_BsConst_Lookup_Curve_HotSpot_Coef_Y_SafeCopy1
            OA_rp_GetNVM_IlluminationElement_Get_BsConst_Temp_Threshold_Hysteresis_Derating_SafeCopy1: operation=rp_GetNVM_IlluminationElement.Get_BsConst_Temp_Threshold_Hysteresis_Derating_SafeCopy1
            OA_rp_GetNVM_IlluminationElement_Get_BsConst_Derating_Backlight_Disable_SafeCopy1: operation=rp_GetNVM_IlluminationElement.Get_BsConst_Derating_Backlight_Disable_SafeCopy1
            OA_rp_GetNVM_IlluminationElement_Get_BsConst_Temperature_Sensor_Conv_SafeCopy1: operation=rp_GetNVM_IlluminationElement.Get_BsConst_Temperature_Sensor_Conv_SafeCopy1
            OA_rp_GetNVM_IlluminationElement_Get_BsConst_PCB_Temperature_Sensor_Conv_SafeCopy1: operation=rp_GetNVM_IlluminationElement.Get_BsConst_PCB_Temperature_Sensor_Conv_SafeCopy1
            OA_rp_GetNVM_IlluminationElement_Get_BsConst_Display_Illum_Max_Level_SafeCopy1: operation=rp_GetNVM_IlluminationElement.Get_BsConst_Display_Illum_Max_Level_SafeCopy1
            OA_rp_GetNVM_IlluminationElement_Get_BsConst_PWM_boost_bypass_duty_SafeCopy1: operation=rp_GetNVM_IlluminationElement.Get_BsConst_PWM_boost_bypass_duty_SafeCopy1
            OA_rp_GetNVM_IlluminationElement_Get_BsConst_BsConst_Illumination_ReservedByte_SafeCopy1: operation=rp_GetNVM_IlluminationElement.Get_BsConst_BsConst_Illumination_ReservedByte_SafeCopy1
            OA_rp_GetNVM_IlluminationElement_Get_BsConst_Compensation_Line_Slope_m_SafeCopy2: operation=rp_GetNVM_IlluminationElement.Get_BsConst_Compensation_Line_Slope_m_SafeCopy2
            OA_rp_GetNVM_IlluminationElement_Get_BsConst_Compensation_Line_Shift_b_SafeCopy2: operation=rp_GetNVM_IlluminationElement.Get_BsConst_Compensation_Line_Shift_b_SafeCopy2
            OA_rp_GetNVM_IlluminationElement_Get_BsConst_Lookup_Curve_HotSpot_Coef_X_SafeCopy2: operation=rp_GetNVM_IlluminationElement.Get_BsConst_Lookup_Curve_HotSpot_Coef_X_SafeCopy2
            OA_rp_GetNVM_IlluminationElement_Get_BsConst_Lookup_Curve_HotSpot_Coef_Y_SafeCopy2: operation=rp_GetNVM_IlluminationElement.Get_BsConst_Lookup_Curve_HotSpot_Coef_Y_SafeCopy2
            OA_rp_GetNVM_IlluminationElement_Get_BsConst_Temp_Threshold_Hysteresis_Derating_SafeCopy2: operation=rp_GetNVM_IlluminationElement.Get_BsConst_Temp_Threshold_Hysteresis_Derating_SafeCopy2
            OA_rp_GetNVM_IlluminationElement_Get_BsConst_Derating_Backlight_Disable_SafeCopy2: operation=rp_GetNVM_IlluminationElement.Get_BsConst_Derating_Backlight_Disable_SafeCopy2
            OA_rp_GetNVM_IlluminationElement_Get_BsConst_Temperature_Sensor_Conv_SafeCopy2: operation=rp_GetNVM_IlluminationElement.Get_BsConst_Temperature_Sensor_Conv_SafeCopy2
            OA_rp_GetNVM_IlluminationElement_Get_BsConst_PCB_Temperature_Sensor_Conv_SafeCopy2: operation=rp_GetNVM_IlluminationElement.Get_BsConst_PCB_Temperature_Sensor_Conv_SafeCopy2
            OA_rp_GetNVM_IlluminationElement_Get_BsConst_Display_Illum_Max_Level_SafeCopy2: operation=rp_GetNVM_IlluminationElement.Get_BsConst_Display_Illum_Max_Level_SafeCopy2
            OA_rp_GetNVM_IlluminationElement_Get_BsConst_PWM_boost_bypass_duty_SafeCopy2: operation=rp_GetNVM_IlluminationElement.Get_BsConst_PWM_boost_bypass_duty_SafeCopy2
            OA_rp_GetNVM_IlluminationElement_Get_BsConst_BsConst_Illumination_ReservedByte_SafeCopy2: operation=rp_GetNVM_IlluminationElement.Get_BsConst_BsConst_Illumination_ReservedByte_SafeCopy2
            OA_rp_GetNVM_IlluminationElement_Get_BsConst_Audio_Element: operation=rp_GetNVM_IlluminationElement.Get_BsConst_Audio_Element
            OA_rp_GetNVM_IlluminationElement_Get_BsConst_Warning_Element: operation=rp_GetNVM_IlluminationElement.Get_BsConst_Warning_Element
            OA_rp_GetNVM_IlluminationElement_Get_BsConst_RealTimeClock_Element: operation=rp_GetNVM_IlluminationElement.Get_BsConst_RealTimeClock_Element
            OA_rp_GetNVM_IlluminationElement_Get_BsConst_Communication_Element: operation=rp_GetNVM_IlluminationElement.Get_BsConst_Communication_Element
            OA_rp_GetNVM_IlluminationElement_Get_BsConst_Power_Element: operation=rp_GetNVM_IlluminationElement.Get_BsConst_Power_Element
            OA_rp_GetNVM_IlluminationElement_Get_BsConst_ServiceReminder_Element: operation=rp_GetNVM_IlluminationElement.Get_BsConst_ServiceReminder_Element
            OA_rp_GetNVM_IlluminationElement_Get_BsConst_EngOffTimer_Element: operation=rp_GetNVM_IlluminationElement.Get_BsConst_EngOffTimer_Element
            OA_rp_GetNVM_IlluminationElement_Get_BsCys_Certicificate_Element: operation=rp_GetNVM_IlluminationElement.Get_BsCys_Certicificate_Element
            OA_rp_GetNVM_IlluminationElement_Get_RefCys_Certicificate_Element: operation=rp_GetNVM_IlluminationElement.Get_RefCys_Certicificate_Element
            OA_rp_GetNVM_IlluminationElement_Get_RefCys_Certicificate1_Element: operation=rp_GetNVM_IlluminationElement.Get_RefCys_Certicificate1_Element
            OA_rp_GetNVM_IlluminationElement_Get_BsRt_Odometer_Element: operation=rp_GetNVM_IlluminationElement.Get_BsRt_Odometer_Element
            OA_rp_GetNVM_IlluminationElement_Get_BsRt_SpeedoGauge_Element: operation=rp_GetNVM_IlluminationElement.Get_BsRt_SpeedoGauge_Element
            OA_rp_GetNVM_IlluminationElement_Get_BsRt_TachoGauge_Element: operation=rp_GetNVM_IlluminationElement.Get_BsRt_TachoGauge_Element
            OA_rp_GetNVM_IlluminationElement_Get_BsRt_FuelGauge_Element: operation=rp_GetNVM_IlluminationElement.Get_BsRt_FuelGauge_Element
            OA_rp_GetNVM_IlluminationElement_Get_BsRt_TempGauge_Element: operation=rp_GetNVM_IlluminationElement.Get_BsRt_TempGauge_Element
            OA_rp_GetNVM_IlluminationElement_Get_BsRt_PowerGauge_Element: operation=rp_GetNVM_IlluminationElement.Get_BsRt_PowerGauge_Element
            OA_rp_GetNVM_IlluminationElement_Get_BsRt_OilGauge_Element: operation=rp_GetNVM_IlluminationElement.Get_BsRt_OilGauge_Element
            OA_rp_GetNVM_IlluminationElement_Get_BsRt_TripComputer_Element: operation=rp_GetNVM_IlluminationElement.Get_BsRt_TripComputer_Element
            OA_rp_GetNVM_IlluminationElement_Get_BsRt_Warning_Element: operation=rp_GetNVM_IlluminationElement.Get_BsRt_Warning_Element
            OA_rp_GetNVM_IlluminationElement_Get_BsRt_RealTimeClock_Element: operation=rp_GetNVM_IlluminationElement.Get_BsRt_RealTimeClock_Element
            OA_rp_GetNVM_IlluminationElement_Get_BsRt_Personalization_Element: operation=rp_GetNVM_IlluminationElement.Get_BsRt_Personalization_Element
            OA_rp_GetNVM_IlluminationElement_Get_BsRt_Illumination_Element: operation=rp_GetNVM_IlluminationElement.Get_BsRt_Illumination_Element
            OA_rp_GetNVM_IlluminationElement_Get_BsRt_CusDlt_Element: operation=rp_GetNVM_IlluminationElement.Get_BsRt_CusDlt_Element
            OA_rp_GetNVM_IlluminationElement_Get_BsReten_Odometer_Element: operation=rp_GetNVM_IlluminationElement.Get_BsReten_Odometer_Element
            OA_rp_GetNVM_IlluminationElement_Get_BsReten_Gauges_Element: operation=rp_GetNVM_IlluminationElement.Get_BsReten_Gauges_Element
            OA_rp_GetNVM_IlluminationElement_Get_BsReten_Tripcomputer_Element: operation=rp_GetNVM_IlluminationElement.Get_BsReten_Tripcomputer_Element
            OA_rp_GetNVM_IlluminationElement_Get_BsReten_Illumination_Element: operation=rp_GetNVM_IlluminationElement.Get_BsReten_Illumination_Element
            OA_rp_GetNVM_IlluminationElement_Get_BsReten_Audio_Element: operation=rp_GetNVM_IlluminationElement.Get_BsReten_Audio_Element
            OA_rp_GetNVM_IlluminationElement_Get_BsReten_Warning_Element: operation=rp_GetNVM_IlluminationElement.Get_BsReten_Warning_Element
            OA_rp_GetNVM_IlluminationElement_Get_BsReten_RealTimeClock_Element: operation=rp_GetNVM_IlluminationElement.Get_BsReten_RealTimeClock_Element
            OA_rp_GetNVM_IlluminationElement_Get_BsReten_Communication_Element: operation=rp_GetNVM_IlluminationElement.Get_BsReten_Communication_Element
            OA_rp_GetNVM_IlluminationElement_Get_BsReten_Personalization_Element: operation=rp_GetNVM_IlluminationElement.Get_BsReten_Personalization_Element
            OA_rp_GetNVM_IlluminationElement_Get_BsReten_Power_Element: operation=rp_GetNVM_IlluminationElement.Get_BsReten_Power_Element
            OA_rp_GetNVM_IlluminationElement_Get_BsReten_Display_Element: operation=rp_GetNVM_IlluminationElement.Get_BsReten_Display_Element
            OA_rp_GetNVM_IlluminationElement_Get_BsDiag_ErrorRecord_Element: operation=rp_GetNVM_IlluminationElement.Get_BsDiag_ErrorRecord_Element
            OA_rp_GetNVM_IlluminationElement_Get_BsDiag_Dtc_Element: operation=rp_GetNVM_IlluminationElement.Get_BsDiag_Dtc_Element
            OA_rp_ILL_ReadyToSleep_SWCSleepStatus: operation=rp_ILL_ReadyToSleep.SWCSleepStatus
            OA_rp_PwmSetDuty_PwmSetDuty: operation=rp_PwmSetDuty.PwmSetDuty
            OA_rp_PwmSetDuty_PwmSetDutyAndPeriod: operation=rp_PwmSetDuty.PwmSetDutyAndPeriod
            OA_rp_PwmSetDuty_PwmSetIdeal: operation=rp_PwmSetDuty.PwmSetIdeal
            OA_rp_SetNVM_IlluminationElement_Set_BsShare_SwUpdReflash_Element: operation=rp_SetNVM_IlluminationElement.Set_BsShare_SwUpdReflash_Element
            OA_rp_SetNVM_IlluminationElement_Set_BsShare_SwUpdFotaMode_Element: operation=rp_SetNVM_IlluminationElement.Set_BsShare_SwUpdFotaMode_Element
            OA_rp_SetNVM_IlluminationElement_Set_BsShare_SwUpdFotaFinPrint_Element: operation=rp_SetNVM_IlluminationElement.Set_BsShare_SwUpdFotaFinPrint_Element
            OA_rp_SetNVM_IlluminationElement_Set_BsShare_SwUpdFotaStatus_Element: operation=rp_SetNVM_IlluminationElement.Set_BsShare_SwUpdFotaStatus_Element
            OA_rp_SetNVM_IlluminationElement_Set_BsShare_SwUpdFotadecrypt_Element: operation=rp_SetNVM_IlluminationElement.Set_BsShare_SwUpdFotadecrypt_Element
            OA_rp_SetNVM_IlluminationElement_Set_BsShare_EcuPartNumber_Element: operation=rp_SetNVM_IlluminationElement.Set_BsShare_EcuPartNumber_Element
            OA_rp_SetNVM_IlluminationElement_Set_BsShare_VisteonPartNumber: operation=rp_SetNVM_IlluminationElement.Set_BsShare_VisteonPartNumber
            OA_rp_SetNVM_IlluminationElement_Set_BsShare_VisteonPCBPartNumber: operation=rp_SetNVM_IlluminationElement.Set_BsShare_VisteonPCBPartNumber
            OA_rp_SetNVM_IlluminationElement_Set_BsShare_ProductSerialNumber: operation=rp_SetNVM_IlluminationElement.Set_BsShare_ProductSerialNumber
            OA_rp_SetNVM_IlluminationElement_Set_BsShare_PCBSerialNumber: operation=rp_SetNVM_IlluminationElement.Set_BsShare_PCBSerialNumber
            OA_rp_SetNVM_IlluminationElement_Set_BsShare_SMTManufacturingDate: operation=rp_SetNVM_IlluminationElement.Set_BsShare_SMTManufacturingDate
            OA_rp_SetNVM_IlluminationElement_Set_BsShare_AssemblyManufacturingDate: operation=rp_SetNVM_IlluminationElement.Set_BsShare_AssemblyManufacturingDate
            OA_rp_SetNVM_IlluminationElement_Set_BsShare_SMTPlantNumber: operation=rp_SetNVM_IlluminationElement.Set_BsShare_SMTPlantNumber
            OA_rp_SetNVM_IlluminationElement_Set_BsShare_AssemblyPlantNumber: operation=rp_SetNVM_IlluminationElement.Set_BsShare_AssemblyPlantNumber
            OA_rp_SetNVM_IlluminationElement_Set_BsShare_HWModification: operation=rp_SetNVM_IlluminationElement.Set_BsShare_HWModification
            OA_rp_SetNVM_IlluminationElement_Set_BsShare_VisMeet_Element: operation=rp_SetNVM_IlluminationElement.Set_BsShare_VisMeet_Element
            OA_rp_SetNVM_IlluminationElement_Set_BsShare_VisMeet_EOLEntry_Element: operation=rp_SetNVM_IlluminationElement.Set_BsShare_VisMeet_EOLEntry_Element
            OA_rp_SetNVM_IlluminationElement_Set_BsShare_VehicleConfig_Element: operation=rp_SetNVM_IlluminationElement.Set_BsShare_VehicleConfig_Element
            OA_rp_SetNVM_IlluminationElement_Set_BsConst_SpeedoGauge_Element: operation=rp_SetNVM_IlluminationElement.Set_BsConst_SpeedoGauge_Element
            OA_rp_SetNVM_IlluminationElement_Set_BsConst_TachoGauge_Element: operation=rp_SetNVM_IlluminationElement.Set_BsConst_TachoGauge_Element
            OA_rp_SetNVM_IlluminationElement_Set_BsConst_FuelGauge_Element: operation=rp_SetNVM_IlluminationElement.Set_BsConst_FuelGauge_Element
            OA_rp_SetNVM_IlluminationElement_Set_BsConst_TempGauge_Element: operation=rp_SetNVM_IlluminationElement.Set_BsConst_TempGauge_Element
            OA_rp_SetNVM_IlluminationElement_Set_BsConst_PowerGauge_Element: operation=rp_SetNVM_IlluminationElement.Set_BsConst_PowerGauge_Element
            OA_rp_SetNVM_IlluminationElement_Set_BsConst_OilGauge_Element: operation=rp_SetNVM_IlluminationElement.Set_BsConst_OilGauge_Element
            OA_rp_SetNVM_IlluminationElement_Set_BsConst_TripComputer_Element: operation=rp_SetNVM_IlluminationElement.Set_BsConst_TripComputer_Element
            OA_rp_SetNVM_IlluminationElement_Set_BsConst_Compensation_Line_Slope_m: operation=rp_SetNVM_IlluminationElement.Set_BsConst_Compensation_Line_Slope_m
            OA_rp_SetNVM_IlluminationElement_Set_BsConst_Compensation_Line_Shift_b: operation=rp_SetNVM_IlluminationElement.Set_BsConst_Compensation_Line_Shift_b
            OA_rp_SetNVM_IlluminationElement_Set_BsConst_Lookup_Curve_HotSpot_Coef_X: operation=rp_SetNVM_IlluminationElement.Set_BsConst_Lookup_Curve_HotSpot_Coef_X
            OA_rp_SetNVM_IlluminationElement_Set_BsConst_Lookup_Curve_HotSpot_Coef_Y: operation=rp_SetNVM_IlluminationElement.Set_BsConst_Lookup_Curve_HotSpot_Coef_Y
            OA_rp_SetNVM_IlluminationElement_Set_BsConst_Temp_Threshold_Hysteresis_Derating: operation=rp_SetNVM_IlluminationElement.Set_BsConst_Temp_Threshold_Hysteresis_Derating
            OA_rp_SetNVM_IlluminationElement_Set_BsConst_Derating_Backlight_Disable: operation=rp_SetNVM_IlluminationElement.Set_BsConst_Derating_Backlight_Disable
            OA_rp_SetNVM_IlluminationElement_Set_BsConst_Temperature_Sensor_Conv: operation=rp_SetNVM_IlluminationElement.Set_BsConst_Temperature_Sensor_Conv
            OA_rp_SetNVM_IlluminationElement_Set_BsConst_PCB_Temperature_Sensor_Conv: operation=rp_SetNVM_IlluminationElement.Set_BsConst_PCB_Temperature_Sensor_Conv
            OA_rp_SetNVM_IlluminationElement_Set_BsConst_Display_Illum_Max_Level: operation=rp_SetNVM_IlluminationElement.Set_BsConst_Display_Illum_Max_Level
            OA_rp_SetNVM_IlluminationElement_Set_BsConst_PWM_boost_bypass_duty: operation=rp_SetNVM_IlluminationElement.Set_BsConst_PWM_boost_bypass_duty
            OA_rp_SetNVM_IlluminationElement_Set_BsConst_BsConst_Illumination_ReservedByte: operation=rp_SetNVM_IlluminationElement.Set_BsConst_BsConst_Illumination_ReservedByte
            OA_rp_SetNVM_IlluminationElement_Set_BsConst_Compensation_Line_Slope_m_SafeCopy1: operation=rp_SetNVM_IlluminationElement.Set_BsConst_Compensation_Line_Slope_m_SafeCopy1
            OA_rp_SetNVM_IlluminationElement_Set_BsConst_Compensation_Line_Shift_b_SafeCopy1: operation=rp_SetNVM_IlluminationElement.Set_BsConst_Compensation_Line_Shift_b_SafeCopy1
            OA_rp_SetNVM_IlluminationElement_Set_BsConst_Lookup_Curve_HotSpot_Coef_X_SafeCopy1: operation=rp_SetNVM_IlluminationElement.Set_BsConst_Lookup_Curve_HotSpot_Coef_X_SafeCopy1
            OA_rp_SetNVM_IlluminationElement_Set_BsConst_Lookup_Curve_HotSpot_Coef_Y_SafeCopy1: operation=rp_SetNVM_IlluminationElement.Set_BsConst_Lookup_Curve_HotSpot_Coef_Y_SafeCopy1
            OA_rp_SetNVM_IlluminationElement_Set_BsConst_Temp_Threshold_Hysteresis_Derating_SafeCopy1: operation=rp_SetNVM_IlluminationElement.Set_BsConst_Temp_Threshold_Hysteresis_Derating_SafeCopy1
            OA_rp_SetNVM_IlluminationElement_Set_BsConst_Derating_Backlight_Disable_SafeCopy1: operation=rp_SetNVM_IlluminationElement.Set_BsConst_Derating_Backlight_Disable_SafeCopy1
            OA_rp_SetNVM_IlluminationElement_Set_BsConst_Temperature_Sensor_Conv_SafeCopy1: operation=rp_SetNVM_IlluminationElement.Set_BsConst_Temperature_Sensor_Conv_SafeCopy1
            OA_rp_SetNVM_IlluminationElement_Set_BsConst_PCB_Temperature_Sensor_Conv_SafeCopy1: operation=rp_SetNVM_IlluminationElement.Set_BsConst_PCB_Temperature_Sensor_Conv_SafeCopy1
            OA_rp_SetNVM_IlluminationElement_Set_BsConst_Display_Illum_Max_Level_SafeCopy1: operation=rp_SetNVM_IlluminationElement.Set_BsConst_Display_Illum_Max_Level_SafeCopy1
            OA_rp_SetNVM_IlluminationElement_Set_BsConst_PWM_boost_bypass_duty_SafeCopy1: operation=rp_SetNVM_IlluminationElement.Set_BsConst_PWM_boost_bypass_duty_SafeCopy1
            OA_rp_SetNVM_IlluminationElement_Set_BsConst_BsConst_Illumination_ReservedByte_SafeCopy1: operation=rp_SetNVM_IlluminationElement.Set_BsConst_BsConst_Illumination_ReservedByte_SafeCopy1
            OA_rp_SetNVM_IlluminationElement_Set_BsConst_Compensation_Line_Slope_m_SafeCopy2: operation=rp_SetNVM_IlluminationElement.Set_BsConst_Compensation_Line_Slope_m_SafeCopy2
            OA_rp_SetNVM_IlluminationElement_Set_BsConst_Compensation_Line_Shift_b_SafeCopy2: operation=rp_SetNVM_IlluminationElement.Set_BsConst_Compensation_Line_Shift_b_SafeCopy2
            OA_rp_SetNVM_IlluminationElement_Set_BsConst_Lookup_Curve_HotSpot_Coef_X_SafeCopy2: operation=rp_SetNVM_IlluminationElement.Set_BsConst_Lookup_Curve_HotSpot_Coef_X_SafeCopy2
            OA_rp_SetNVM_IlluminationElement_Set_BsConst_Lookup_Curve_HotSpot_Coef_Y_SafeCopy2: operation=rp_SetNVM_IlluminationElement.Set_BsConst_Lookup_Curve_HotSpot_Coef_Y_SafeCopy2
            OA_rp_SetNVM_IlluminationElement_Set_BsConst_Temp_Threshold_Hysteresis_Derating_SafeCopy2: operation=rp_SetNVM_IlluminationElement.Set_BsConst_Temp_Threshold_Hysteresis_Derating_SafeCopy2
            OA_rp_SetNVM_IlluminationElement_Set_BsConst_Derating_Backlight_Disable_SafeCopy2: operation=rp_SetNVM_IlluminationElement.Set_BsConst_Derating_Backlight_Disable_SafeCopy2
            OA_rp_SetNVM_IlluminationElement_Set_BsConst_Temperature_Sensor_Conv_SafeCopy2: operation=rp_SetNVM_IlluminationElement.Set_BsConst_Temperature_Sensor_Conv_SafeCopy2
            OA_rp_SetNVM_IlluminationElement_Set_BsConst_PCB_Temperature_Sensor_Conv_SafeCopy2: operation=rp_SetNVM_IlluminationElement.Set_BsConst_PCB_Temperature_Sensor_Conv_SafeCopy2
            OA_rp_SetNVM_IlluminationElement_Set_BsConst_Display_Illum_Max_Level_SafeCopy2: operation=rp_SetNVM_IlluminationElement.Set_BsConst_Display_Illum_Max_Level_SafeCopy2
            OA_rp_SetNVM_IlluminationElement_Set_BsConst_PWM_boost_bypass_duty_SafeCopy2: operation=rp_SetNVM_IlluminationElement.Set_BsConst_PWM_boost_bypass_duty_SafeCopy2
            OA_rp_SetNVM_IlluminationElement_Set_BsConst_BsConst_Illumination_ReservedByte_SafeCopy2: operation=rp_SetNVM_IlluminationElement.Set_BsConst_BsConst_Illumination_ReservedByte_SafeCopy2
            OA_rp_SetNVM_IlluminationElement_Set_BsConst_Audio_Element: operation=rp_SetNVM_IlluminationElement.Set_BsConst_Audio_Element
            OA_rp_SetNVM_IlluminationElement_Set_BsConst_Warning_Element: operation=rp_SetNVM_IlluminationElement.Set_BsConst_Warning_Element
            OA_rp_SetNVM_IlluminationElement_Set_BsConst_RealTimeClock_Element: operation=rp_SetNVM_IlluminationElement.Set_BsConst_RealTimeClock_Element
            OA_rp_SetNVM_IlluminationElement_Set_BsConst_Communication_Element: operation=rp_SetNVM_IlluminationElement.Set_BsConst_Communication_Element
            OA_rp_SetNVM_IlluminationElement_Set_BsConst_Power_Element: operation=rp_SetNVM_IlluminationElement.Set_BsConst_Power_Element
            OA_rp_SetNVM_IlluminationElement_Set_BsConst_ServiceReminder_Element: operation=rp_SetNVM_IlluminationElement.Set_BsConst_ServiceReminder_Element
            OA_rp_SetNVM_IlluminationElement_Set_BsConst_EngOffTimer_Element: operation=rp_SetNVM_IlluminationElement.Set_BsConst_EngOffTimer_Element
            OA_rp_SetNVM_IlluminationElement_Set_BsCys_Certicificate_Element: operation=rp_SetNVM_IlluminationElement.Set_BsCys_Certicificate_Element
            OA_rp_SetNVM_IlluminationElement_Set_RefCys_Certicificate_Element: operation=rp_SetNVM_IlluminationElement.Set_RefCys_Certicificate_Element
            OA_rp_SetNVM_IlluminationElement_Set_RefCys_Certicificate1_Element: operation=rp_SetNVM_IlluminationElement.Set_RefCys_Certicificate1_Element
            OA_rp_SetNVM_IlluminationElement_Set_BsRt_Odometer_Element: operation=rp_SetNVM_IlluminationElement.Set_BsRt_Odometer_Element
            OA_rp_SetNVM_IlluminationElement_Set_BsRt_SpeedoGauge_Element: operation=rp_SetNVM_IlluminationElement.Set_BsRt_SpeedoGauge_Element
            OA_rp_SetNVM_IlluminationElement_Set_BsRt_TachoGauge_Element: operation=rp_SetNVM_IlluminationElement.Set_BsRt_TachoGauge_Element
            OA_rp_SetNVM_IlluminationElement_Set_BsRt_FuelGauge_Element: operation=rp_SetNVM_IlluminationElement.Set_BsRt_FuelGauge_Element
            OA_rp_SetNVM_IlluminationElement_Set_BsRt_TempGauge_Element: operation=rp_SetNVM_IlluminationElement.Set_BsRt_TempGauge_Element
            OA_rp_SetNVM_IlluminationElement_Set_BsRt_PowerGauge_Element: operation=rp_SetNVM_IlluminationElement.Set_BsRt_PowerGauge_Element
            OA_rp_SetNVM_IlluminationElement_Set_BsRt_OilGauge_Element: operation=rp_SetNVM_IlluminationElement.Set_BsRt_OilGauge_Element
            OA_rp_SetNVM_IlluminationElement_Set_BsRt_TripComputer_Element: operation=rp_SetNVM_IlluminationElement.Set_BsRt_TripComputer_Element
            OA_rp_SetNVM_IlluminationElement_Set_BsRt_Warning_Element: operation=rp_SetNVM_IlluminationElement.Set_BsRt_Warning_Element
            OA_rp_SetNVM_IlluminationElement_Set_BsRt_RealTimeClock_Element: operation=rp_SetNVM_IlluminationElement.Set_BsRt_RealTimeClock_Element
            OA_rp_SetNVM_IlluminationElement_Set_BsRt_Personalization_Element: operation=rp_SetNVM_IlluminationElement.Set_BsRt_Personalization_Element
            OA_rp_SetNVM_IlluminationElement_Set_BsRt_Illumination_Element: operation=rp_SetNVM_IlluminationElement.Set_BsRt_Illumination_Element
            OA_rp_SetNVM_IlluminationElement_Set_BsRt_CusDlt_Element: operation=rp_SetNVM_IlluminationElement.Set_BsRt_CusDlt_Element
            OA_rp_SetNVM_IlluminationElement_Set_BsReten_Odometer_Element: operation=rp_SetNVM_IlluminationElement.Set_BsReten_Odometer_Element
            OA_rp_SetNVM_IlluminationElement_Set_BsReten_Gauges_Element: operation=rp_SetNVM_IlluminationElement.Set_BsReten_Gauges_Element
            OA_rp_SetNVM_IlluminationElement_Set_BsReten_Tripcomputer_Element: operation=rp_SetNVM_IlluminationElement.Set_BsReten_Tripcomputer_Element
            OA_rp_SetNVM_IlluminationElement_Set_BsReten_Illumination_Element: operation=rp_SetNVM_IlluminationElement.Set_BsReten_Illumination_Element
            OA_rp_SetNVM_IlluminationElement_Set_BsReten_Audio_Element: operation=rp_SetNVM_IlluminationElement.Set_BsReten_Audio_Element
            OA_rp_SetNVM_IlluminationElement_Set_BsReten_Warning_Element: operation=rp_SetNVM_IlluminationElement.Set_BsReten_Warning_Element
            OA_rp_SetNVM_IlluminationElement_Set_BsReten_RealTimeClock_Element: operation=rp_SetNVM_IlluminationElement.Set_BsReten_RealTimeClock_Element
            OA_rp_SetNVM_IlluminationElement_Set_BsReten_Communication_Element: operation=rp_SetNVM_IlluminationElement.Set_BsReten_Communication_Element
            OA_rp_SetNVM_IlluminationElement_Set_BsReten_Personalization_Element: operation=rp_SetNVM_IlluminationElement.Set_BsReten_Personalization_Element
            OA_rp_SetNVM_IlluminationElement_Set_BsReten_Power_Element: operation=rp_SetNVM_IlluminationElement.Set_BsReten_Power_Element
            OA_rp_SetNVM_IlluminationElement_Set_BsReten_Display_Element: operation=rp_SetNVM_IlluminationElement.Set_BsReten_Display_Element
            OA_rp_SetNVM_IlluminationElement_Set_BsDiag_ErrorRecord_Element: operation=rp_SetNVM_IlluminationElement.Set_BsDiag_ErrorRecord_Element
            OA_rp_SetNVM_IlluminationElement_Set_BsDiag_Dtc_Element: operation=rp_SetNVM_IlluminationElement.Set_BsDiag_Dtc_Element
            OA_rp_TmExt_Timer_IsElapsed_Timer_IsElapsed: operation=rp_TmExt_Timer_IsElapsed.Timer_IsElapsed
            OA_rp_TmExt_Timer_IsStarted_Timer_IsStarted: operation=rp_TmExt_Timer_IsStarted.Timer_IsStarted
            OA_rp_TmExt_Timer_Start_Timer_Start: operation=rp_TmExt_Timer_Start.Timer_Start
            OA_rp_TmExt_Timer_Stop_Timer_Stop: operation=rp_TmExt_Timer_Stop.Timer_Stop
        CCtrl_Illumination_Impl_OnCommand
        Ctrl_Illumination_Init
        Ctrl_Illumination_PWM_Rate_Status
        Ctrl_Illumination_Task
          data-receive-point-by-arguments:
            14 x access:
              DRA_rpEtmSts_IllumStatus: accessed-variable=rpEtmSts.IllumStatus
              DRA_rpIgnSubstate_IgnitionSubstate: accessed-variable=rpIgnSubstate.IgnitionSubstate
              DRA_rpIllum_Etm_IllumStatus: accessed-variable=rpIllum_Etm.IllumStatus
              DRA_rpVehicleAppMode_WSSCurrentVehicleState: accessed-variable=rpVehicleAppMode.WSSCurrentVehicleState
              DRA_rp_ClusterMode_WSSCurrentClusterMode: accessed-variable=rp_ClusterMode.WSSCurrentClusterMode
              DRA_rp_Ctrl_DayNight_Mode_Day_Night_mode_Ctrl: accessed-variable=rp_Ctrl_DayNight_Mode.Day_Night_mode_Ctrl
              DRA_rp_EcoRunSystemState_EcoRunSystem_Flag: accessed-variable=rp_EcoRunSystemState.EcoRunSystem_Flag
              DRA_rp_EtmIllumSts_IllumStatus: accessed-variable=rp_EtmIllumSts.IllumStatus
              DRA_rp_IllumCtrl_Ip_IllumCtrl_Ip_Data: accessed-variable=rp_IllumCtrl_Ip.IllumCtrl_Ip_Data
              DRA_rp_IlumStep_IllumStepValue: accessed-variable=rp_IlumStep.IllumStepValue
              DRA_rp_RheostatDayStep_RheostatDayStep: accessed-variable=rp_RheostatDayStep.RheostatDayStep
              DRA_rp_RheostatNightStep_RheostatNightStep: accessed-variable=rp_RheostatNightStep.RheostatNightStep
              DRA_rp_Rheostat_Change_RheoUpdateVal: accessed-variable=rp_Rheostat_Change.RheoUpdateVal
              DRA_rp_TFTDisplayOn_TFTDisplayOn: accessed-variable=rp_TFTDisplayOn.TFTDisplayOn
          data-send-points:
            9 x access:
              DWA_pp_Ctrl_ILL_Duty_ILL_Duty: accessed-variable=pp_Ctrl_ILL_Duty.ILL_Duty
              DWA_pp_Ctrl_RGB_Dimming_RGB_Dimming: accessed-variable=pp_Ctrl_RGB_Dimming.RGB_Dimming
              DWA_pp_Ctrl_RGB_Starter_Status_Starter_Status: accessed-variable=pp_Ctrl_RGB_Starter_Status.Starter_Status
              DWA_pp_Ctrl_Ready_to_Sleep_Ready_to_Sleep: accessed-variable=pp_Ctrl_Ready_to_Sleep.Ready_to_Sleep
              DWA_pp_IllumCtrl_Op_IllumCtrl_Op_Data: accessed-variable=pp_IllumCtrl_Op.IllumCtrl_Op_Data
              DWA_pp_IlumDayNightRequired_IlumDayNightRequired: accessed-variable=pp_IlumDayNightRequired.IlumDayNightRequired
              DWA_pp_IlumDayNightStatus_Day_Night_Status: accessed-variable=pp_IlumDayNightStatus.Day_Night_Status
              DWA_pp_PWM_LCD_BL_Dimming_BL_Dimming: accessed-variable=pp_PWM_LCD_BL_Dimming.BL_Dimming
              DWA_pp_StopPwmUpdate_channel_id: accessed-variable=pp_StopPwmUpdate.channel_id
          305 x sync call, all with timeout=0.0:
            OA_rpIoHwAb_Din_GetAsyncRawInput: operation=rpIoHwAb_Din.GetAsyncRawInput
            OA_rpIoHwAb_Din_GetProcessedInput: operation=rpIoHwAb_Din.GetProcessedInput
            OA_rpIoHwAb_Din_GetSyncRawInput: operation=rpIoHwAb_Din.GetSyncRawInput
            OA_rpIoHwAb_Din_GetInputGroup: operation=rpIoHwAb_Din.GetInputGroup
            OA_rp_CS_CanRx_RxCan_GetSignalValueU8Arr: operation=rp_CS_CanRx.RxCan_GetSignalValueU8Arr
            OA_rp_CS_CanRx_RxCan_SetSignalInitValue: operation=rp_CS_CanRx.RxCan_SetSignalInitValue
            OA_rp_CS_CanRx_RxCan_SetSignalInitValueU8Arr: operation=rp_CS_CanRx.RxCan_SetSignalInitValueU8Arr
            OA_rp_CS_CanRx_RxCan_SignalInvalidProcessingControl: operation=rp_CS_CanRx.RxCan_SignalInvalidProcessingControl
            OA_rp_CS_CanRx_RxCan_SignalMissingProcessingControl: operation=rp_CS_CanRx.RxCan_SignalMissingProcessingControl
            OA_rp_CS_CanRx_RxCan_SignalNRProcessingControl: operation=rp_CS_CanRx.RxCan_SignalNRProcessingControl
            OA_rp_CS_CanRx_RxCan_SignalGetJustRcvdStatus: operation=rp_CS_CanRx.RxCan_SignalGetJustRcvdStatus
            OA_rp_CS_CanRx_RxCan_SignalClearJustRcvdStatus: operation=rp_CS_CanRx.RxCan_SignalClearJustRcvdStatus
            OA_rp_CS_CanRx_RxCan_GetSignalValue: operation=rp_CS_CanRx.RxCan_GetSignalValue
            OA_rp_CS_EcuBatteryOutData_EcuBatteryM_GetChannelStatus: operation=rp_CS_EcuBatteryOutData.EcuBatteryM_GetChannelStatus
            OA_rp_CS_EcuBatteryOutData_EcuBatteryM_GetDIOStatus: operation=rp_CS_EcuBatteryOutData.EcuBatteryM_GetDIOStatus
            OA_rp_CS_MemAbsGet_Get_BsShare_SwUpdReflash_Element: operation=rp_CS_MemAbsGet.Get_BsShare_SwUpdReflash_Element
            OA_rp_CS_MemAbsGet_Get_BsShare_SwUpdFotaMode_Element: operation=rp_CS_MemAbsGet.Get_BsShare_SwUpdFotaMode_Element
            OA_rp_CS_MemAbsGet_Get_BsShare_SwUpdFotaFinPrint_Element: operation=rp_CS_MemAbsGet.Get_BsShare_SwUpdFotaFinPrint_Element
            OA_rp_CS_MemAbsGet_Get_BsShare_SwUpdFotaStatus_Element: operation=rp_CS_MemAbsGet.Get_BsShare_SwUpdFotaStatus_Element
            OA_rp_CS_MemAbsGet_Get_BsShare_SwUpdFotadecrypt_Element: operation=rp_CS_MemAbsGet.Get_BsShare_SwUpdFotadecrypt_Element
            OA_rp_CS_MemAbsGet_Get_BsShare_EcuPartNumber_Element: operation=rp_CS_MemAbsGet.Get_BsShare_EcuPartNumber_Element
            OA_rp_CS_MemAbsGet_Get_BsShare_VisteonPartNumber: operation=rp_CS_MemAbsGet.Get_BsShare_VisteonPartNumber
            OA_rp_CS_MemAbsGet_Get_BsShare_VisteonPCBPartNumber: operation=rp_CS_MemAbsGet.Get_BsShare_VisteonPCBPartNumber
            OA_rp_CS_MemAbsGet_Get_BsShare_ProductSerialNumber: operation=rp_CS_MemAbsGet.Get_BsShare_ProductSerialNumber
            OA_rp_CS_MemAbsGet_Get_BsShare_PCBSerialNumber: operation=rp_CS_MemAbsGet.Get_BsShare_PCBSerialNumber
            OA_rp_CS_MemAbsGet_Get_BsShare_SMTManufacturingDate: operation=rp_CS_MemAbsGet.Get_BsShare_SMTManufacturingDate
            OA_rp_CS_MemAbsGet_Get_BsShare_AssemblyManufacturingDate: operation=rp_CS_MemAbsGet.Get_BsShare_AssemblyManufacturingDate
            OA_rp_CS_MemAbsGet_Get_BsShare_SMTPlantNumber: operation=rp_CS_MemAbsGet.Get_BsShare_SMTPlantNumber
            OA_rp_CS_MemAbsGet_Get_BsShare_AssemblyPlantNumber: operation=rp_CS_MemAbsGet.Get_BsShare_AssemblyPlantNumber
            OA_rp_CS_MemAbsGet_Get_BsShare_HWModification: operation=rp_CS_MemAbsGet.Get_BsShare_HWModification
            OA_rp_CS_MemAbsGet_Get_BsShare_VisMeet_Element: operation=rp_CS_MemAbsGet.Get_BsShare_VisMeet_Element
            OA_rp_CS_MemAbsGet_Get_BsShare_VisMeet_EOLEntry_Element: operation=rp_CS_MemAbsGet.Get_BsShare_VisMeet_EOLEntry_Element
            OA_rp_CS_MemAbsGet_Get_BsShare_VehicleConfig_Element: operation=rp_CS_MemAbsGet.Get_BsShare_VehicleConfig_Element
            OA_rp_CS_MemAbsGet_Get_BsConst_SpeedoGauge_Element: operation=rp_CS_MemAbsGet.Get_BsConst_SpeedoGauge_Element
            OA_rp_CS_MemAbsGet_Get_BsConst_TachoGauge_Element: operation=rp_CS_MemAbsGet.Get_BsConst_TachoGauge_Element
            OA_rp_CS_MemAbsGet_Get_BsConst_FuelGauge_Element: operation=rp_CS_MemAbsGet.Get_BsConst_FuelGauge_Element
            OA_rp_CS_MemAbsGet_Get_BsConst_TempGauge_Element: operation=rp_CS_MemAbsGet.Get_BsConst_TempGauge_Element
            OA_rp_CS_MemAbsGet_Get_BsConst_PowerGauge_Element: operation=rp_CS_MemAbsGet.Get_BsConst_PowerGauge_Element
            OA_rp_CS_MemAbsGet_Get_BsConst_OilGauge_Element: operation=rp_CS_MemAbsGet.Get_BsConst_OilGauge_Element
            OA_rp_CS_MemAbsGet_Get_BsConst_TripComputer_Element: operation=rp_CS_MemAbsGet.Get_BsConst_TripComputer_Element
            OA_rp_CS_MemAbsGet_Get_BsConst_Compensation_Line_Slope_m: operation=rp_CS_MemAbsGet.Get_BsConst_Compensation_Line_Slope_m
            OA_rp_CS_MemAbsGet_Get_BsConst_Compensation_Line_Shift_b: operation=rp_CS_MemAbsGet.Get_BsConst_Compensation_Line_Shift_b
            OA_rp_CS_MemAbsGet_Get_BsConst_Lookup_Curve_HotSpot_Coef_X: operation=rp_CS_MemAbsGet.Get_BsConst_Lookup_Curve_HotSpot_Coef_X
            OA_rp_CS_MemAbsGet_Get_BsConst_Lookup_Curve_HotSpot_Coef_Y: operation=rp_CS_MemAbsGet.Get_BsConst_Lookup_Curve_HotSpot_Coef_Y
            OA_rp_CS_MemAbsGet_Get_BsConst_Temp_Threshold_Hysteresis_Derating: operation=rp_CS_MemAbsGet.Get_BsConst_Temp_Threshold_Hysteresis_Derating
            OA_rp_CS_MemAbsGet_Get_BsConst_Derating_Backlight_Disable: operation=rp_CS_MemAbsGet.Get_BsConst_Derating_Backlight_Disable
            OA_rp_CS_MemAbsGet_Get_BsConst_Temperature_Sensor_Conv: operation=rp_CS_MemAbsGet.Get_BsConst_Temperature_Sensor_Conv
            OA_rp_CS_MemAbsGet_Get_BsConst_PCB_Temperature_Sensor_Conv: operation=rp_CS_MemAbsGet.Get_BsConst_PCB_Temperature_Sensor_Conv
            OA_rp_CS_MemAbsGet_Get_BsConst_Display_Illum_Max_Level: operation=rp_CS_MemAbsGet.Get_BsConst_Display_Illum_Max_Level
            OA_rp_CS_MemAbsGet_Get_BsConst_PWM_boost_bypass_duty: operation=rp_CS_MemAbsGet.Get_BsConst_PWM_boost_bypass_duty
            OA_rp_CS_MemAbsGet_Get_BsConst_BsConst_Illumination_ReservedByte: operation=rp_CS_MemAbsGet.Get_BsConst_BsConst_Illumination_ReservedByte
            OA_rp_CS_MemAbsGet_Get_BsConst_Compensation_Line_Slope_m_SafeCopy1: operation=rp_CS_MemAbsGet.Get_BsConst_Compensation_Line_Slope_m_SafeCopy1
            OA_rp_CS_MemAbsGet_Get_BsConst_Compensation_Line_Shift_b_SafeCopy1: operation=rp_CS_MemAbsGet.Get_BsConst_Compensation_Line_Shift_b_SafeCopy1
            OA_rp_CS_MemAbsGet_Get_BsConst_Lookup_Curve_HotSpot_Coef_X_SafeCopy1: operation=rp_CS_MemAbsGet.Get_BsConst_Lookup_Curve_HotSpot_Coef_X_SafeCopy1
            OA_rp_CS_MemAbsGet_Get_BsConst_Lookup_Curve_HotSpot_Coef_Y_SafeCopy1: operation=rp_CS_MemAbsGet.Get_BsConst_Lookup_Curve_HotSpot_Coef_Y_SafeCopy1
            OA_rp_CS_MemAbsGet_Get_BsConst_Temp_Threshold_Hysteresis_Derating_SafeCopy1: operation=rp_CS_MemAbsGet.Get_BsConst_Temp_Threshold_Hysteresis_Derating_SafeCopy1
            OA_rp_CS_MemAbsGet_Get_BsConst_Derating_Backlight_Disable_SafeCopy1: operation=rp_CS_MemAbsGet.Get_BsConst_Derating_Backlight_Disable_SafeCopy1
            OA_rp_CS_MemAbsGet_Get_BsConst_Temperature_Sensor_Conv_SafeCopy1: operation=rp_CS_MemAbsGet.Get_BsConst_Temperature_Sensor_Conv_SafeCopy1
            OA_rp_CS_MemAbsGet_Get_BsConst_PCB_Temperature_Sensor_Conv_SafeCopy1: operation=rp_CS_MemAbsGet.Get_BsConst_PCB_Temperature_Sensor_Conv_SafeCopy1
            OA_rp_CS_MemAbsGet_Get_BsConst_Display_Illum_Max_Level_SafeCopy1: operation=rp_CS_MemAbsGet.Get_BsConst_Display_Illum_Max_Level_SafeCopy1
            OA_rp_CS_MemAbsGet_Get_BsConst_PWM_boost_bypass_duty_SafeCopy1: operation=rp_CS_MemAbsGet.Get_BsConst_PWM_boost_bypass_duty_SafeCopy1
            OA_rp_CS_MemAbsGet_Get_BsConst_BsConst_Illumination_ReservedByte_SafeCopy1: operation=rp_CS_MemAbsGet.Get_BsConst_BsConst_Illumination_ReservedByte_SafeCopy1
            OA_rp_CS_MemAbsGet_Get_BsConst_Compensation_Line_Slope_m_SafeCopy2: operation=rp_CS_MemAbsGet.Get_BsConst_Compensation_Line_Slope_m_SafeCopy2
            OA_rp_CS_MemAbsGet_Get_BsConst_Compensation_Line_Shift_b_SafeCopy2: operation=rp_CS_MemAbsGet.Get_BsConst_Compensation_Line_Shift_b_SafeCopy2
            OA_rp_CS_MemAbsGet_Get_BsConst_Lookup_Curve_HotSpot_Coef_X_SafeCopy2: operation=rp_CS_MemAbsGet.Get_BsConst_Lookup_Curve_HotSpot_Coef_X_SafeCopy2
            OA_rp_CS_MemAbsGet_Get_BsConst_Lookup_Curve_HotSpot_Coef_Y_SafeCopy2: operation=rp_CS_MemAbsGet.Get_BsConst_Lookup_Curve_HotSpot_Coef_Y_SafeCopy2
            OA_rp_CS_MemAbsGet_Get_BsConst_Temp_Threshold_Hysteresis_Derating_SafeCopy2: operation=rp_CS_MemAbsGet.Get_BsConst_Temp_Threshold_Hysteresis_Derating_SafeCopy2
            OA_rp_CS_MemAbsGet_Get_BsConst_Derating_Backlight_Disable_SafeCopy2: operation=rp_CS_MemAbsGet.Get_BsConst_Derating_Backlight_Disable_SafeCopy2
            OA_rp_CS_MemAbsGet_Get_BsConst_Temperature_Sensor_Conv_SafeCopy2: operation=rp_CS_MemAbsGet.Get_BsConst_Temperature_Sensor_Conv_SafeCopy2
            OA_rp_CS_MemAbsGet_Get_BsConst_PCB_Temperature_Sensor_Conv_SafeCopy2: operation=rp_CS_MemAbsGet.Get_BsConst_PCB_Temperature_Sensor_Conv_SafeCopy2
            OA_rp_CS_MemAbsGet_Get_BsConst_Display_Illum_Max_Level_SafeCopy2: operation=rp_CS_MemAbsGet.Get_BsConst_Display_Illum_Max_Level_SafeCopy2
            OA_rp_CS_MemAbsGet_Get_BsConst_PWM_boost_bypass_duty_SafeCopy2: operation=rp_CS_MemAbsGet.Get_BsConst_PWM_boost_bypass_duty_SafeCopy2
            OA_rp_CS_MemAbsGet_Get_BsConst_BsConst_Illumination_ReservedByte_SafeCopy2: operation=rp_CS_MemAbsGet.Get_BsConst_BsConst_Illumination_ReservedByte_SafeCopy2
            OA_rp_CS_MemAbsGet_Get_BsConst_Audio_Element: operation=rp_CS_MemAbsGet.Get_BsConst_Audio_Element
            OA_rp_CS_MemAbsGet_Get_BsConst_Warning_Element: operation=rp_CS_MemAbsGet.Get_BsConst_Warning_Element
            OA_rp_CS_MemAbsGet_Get_BsConst_RealTimeClock_Element: operation=rp_CS_MemAbsGet.Get_BsConst_RealTimeClock_Element
            OA_rp_CS_MemAbsGet_Get_BsConst_Communication_Element: operation=rp_CS_MemAbsGet.Get_BsConst_Communication_Element
            OA_rp_CS_MemAbsGet_Get_BsConst_Power_Element: operation=rp_CS_MemAbsGet.Get_BsConst_Power_Element
            OA_rp_CS_MemAbsGet_Get_BsConst_ServiceReminder_Element: operation=rp_CS_MemAbsGet.Get_BsConst_ServiceReminder_Element
            OA_rp_CS_MemAbsGet_Get_BsConst_EngOffTimer_Element: operation=rp_CS_MemAbsGet.Get_BsConst_EngOffTimer_Element
            OA_rp_CS_MemAbsGet_Get_BsCys_Certicificate_Element: operation=rp_CS_MemAbsGet.Get_BsCys_Certicificate_Element
            OA_rp_CS_MemAbsGet_Get_RefCys_Certicificate_Element: operation=rp_CS_MemAbsGet.Get_RefCys_Certicificate_Element
            OA_rp_CS_MemAbsGet_Get_RefCys_Certicificate1_Element: operation=rp_CS_MemAbsGet.Get_RefCys_Certicificate1_Element
            OA_rp_CS_MemAbsGet_Get_BsRt_Odometer_Element: operation=rp_CS_MemAbsGet.Get_BsRt_Odometer_Element
            OA_rp_CS_MemAbsGet_Get_BsRt_SpeedoGauge_Element: operation=rp_CS_MemAbsGet.Get_BsRt_SpeedoGauge_Element
            OA_rp_CS_MemAbsGet_Get_BsRt_TachoGauge_Element: operation=rp_CS_MemAbsGet.Get_BsRt_TachoGauge_Element
            OA_rp_CS_MemAbsGet_Get_BsRt_FuelGauge_Element: operation=rp_CS_MemAbsGet.Get_BsRt_FuelGauge_Element
            OA_rp_CS_MemAbsGet_Get_BsRt_TempGauge_Element: operation=rp_CS_MemAbsGet.Get_BsRt_TempGauge_Element
            OA_rp_CS_MemAbsGet_Get_BsRt_PowerGauge_Element: operation=rp_CS_MemAbsGet.Get_BsRt_PowerGauge_Element
            OA_rp_CS_MemAbsGet_Get_BsRt_OilGauge_Element: operation=rp_CS_MemAbsGet.Get_BsRt_OilGauge_Element
            OA_rp_CS_MemAbsGet_Get_BsRt_TripComputer_Element: operation=rp_CS_MemAbsGet.Get_BsRt_TripComputer_Element
            OA_rp_CS_MemAbsGet_Get_BsRt_Warning_Element: operation=rp_CS_MemAbsGet.Get_BsRt_Warning_Element
            OA_rp_CS_MemAbsGet_Get_BsRt_RealTimeClock_Element: operation=rp_CS_MemAbsGet.Get_BsRt_RealTimeClock_Element
            OA_rp_CS_MemAbsGet_Get_BsRt_Personalization_Element: operation=rp_CS_MemAbsGet.Get_BsRt_Personalization_Element
            OA_rp_CS_MemAbsGet_Get_BsRt_Illumination_Element: operation=rp_CS_MemAbsGet.Get_BsRt_Illumination_Element
            OA_rp_CS_MemAbsGet_Get_BsRt_CusDlt_Element: operation=rp_CS_MemAbsGet.Get_BsRt_CusDlt_Element
            OA_rp_CS_MemAbsGet_Get_BsReten_Odometer_Element: operation=rp_CS_MemAbsGet.Get_BsReten_Odometer_Element
            OA_rp_CS_MemAbsGet_Get_BsReten_Gauges_Element: operation=rp_CS_MemAbsGet.Get_BsReten_Gauges_Element
            OA_rp_CS_MemAbsGet_Get_BsReten_Tripcomputer_Element: operation=rp_CS_MemAbsGet.Get_BsReten_Tripcomputer_Element
            OA_rp_CS_MemAbsGet_Get_BsReten_Illumination_Element: operation=rp_CS_MemAbsGet.Get_BsReten_Illumination_Element
            OA_rp_CS_MemAbsGet_Get_BsReten_Audio_Element: operation=rp_CS_MemAbsGet.Get_BsReten_Audio_Element
            OA_rp_CS_MemAbsGet_Get_BsReten_Warning_Element: operation=rp_CS_MemAbsGet.Get_BsReten_Warning_Element
            OA_rp_CS_MemAbsGet_Get_BsReten_RealTimeClock_Element: operation=rp_CS_MemAbsGet.Get_BsReten_RealTimeClock_Element
            OA_rp_CS_MemAbsGet_Get_BsReten_Communication_Element: operation=rp_CS_MemAbsGet.Get_BsReten_Communication_Element
            OA_rp_CS_MemAbsGet_Get_BsReten_Personalization_Element: operation=rp_CS_MemAbsGet.Get_BsReten_Personalization_Element
            OA_rp_CS_MemAbsGet_Get_BsReten_Power_Element: operation=rp_CS_MemAbsGet.Get_BsReten_Power_Element
            OA_rp_CS_MemAbsGet_Get_BsReten_Display_Element: operation=rp_CS_MemAbsGet.Get_BsReten_Display_Element
            OA_rp_CS_MemAbsGet_Get_BsDiag_ErrorRecord_Element: operation=rp_CS_MemAbsGet.Get_BsDiag_ErrorRecord_Element
            OA_rp_CS_MemAbsGet_Get_BsDiag_Dtc_Element: operation=rp_CS_MemAbsGet.Get_BsDiag_Dtc_Element
            OA_rp_GetNVM_IlluminationElement_Get_BsShare_SwUpdReflash_Element: operation=rp_GetNVM_IlluminationElement.Get_BsShare_SwUpdReflash_Element
            OA_rp_GetNVM_IlluminationElement_Get_BsShare_SwUpdFotaMode_Element: operation=rp_GetNVM_IlluminationElement.Get_BsShare_SwUpdFotaMode_Element
            OA_rp_GetNVM_IlluminationElement_Get_BsShare_SwUpdFotaFinPrint_Element: operation=rp_GetNVM_IlluminationElement.Get_BsShare_SwUpdFotaFinPrint_Element
            OA_rp_GetNVM_IlluminationElement_Get_BsShare_SwUpdFotaStatus_Element: operation=rp_GetNVM_IlluminationElement.Get_BsShare_SwUpdFotaStatus_Element
            OA_rp_GetNVM_IlluminationElement_Get_BsShare_SwUpdFotadecrypt_Element: operation=rp_GetNVM_IlluminationElement.Get_BsShare_SwUpdFotadecrypt_Element
            OA_rp_GetNVM_IlluminationElement_Get_BsShare_EcuPartNumber_Element: operation=rp_GetNVM_IlluminationElement.Get_BsShare_EcuPartNumber_Element
            OA_rp_GetNVM_IlluminationElement_Get_BsShare_VisteonPartNumber: operation=rp_GetNVM_IlluminationElement.Get_BsShare_VisteonPartNumber
            OA_rp_GetNVM_IlluminationElement_Get_BsShare_VisteonPCBPartNumber: operation=rp_GetNVM_IlluminationElement.Get_BsShare_VisteonPCBPartNumber
            OA_rp_GetNVM_IlluminationElement_Get_BsShare_ProductSerialNumber: operation=rp_GetNVM_IlluminationElement.Get_BsShare_ProductSerialNumber
            OA_rp_GetNVM_IlluminationElement_Get_BsShare_PCBSerialNumber: operation=rp_GetNVM_IlluminationElement.Get_BsShare_PCBSerialNumber
            OA_rp_GetNVM_IlluminationElement_Get_BsShare_SMTManufacturingDate: operation=rp_GetNVM_IlluminationElement.Get_BsShare_SMTManufacturingDate
            OA_rp_GetNVM_IlluminationElement_Get_BsShare_AssemblyManufacturingDate: operation=rp_GetNVM_IlluminationElement.Get_BsShare_AssemblyManufacturingDate
            OA_rp_GetNVM_IlluminationElement_Get_BsShare_SMTPlantNumber: operation=rp_GetNVM_IlluminationElement.Get_BsShare_SMTPlantNumber
            OA_rp_GetNVM_IlluminationElement_Get_BsShare_AssemblyPlantNumber: operation=rp_GetNVM_IlluminationElement.Get_BsShare_AssemblyPlantNumber
            OA_rp_GetNVM_IlluminationElement_Get_BsShare_HWModification: operation=rp_GetNVM_IlluminationElement.Get_BsShare_HWModification
            OA_rp_GetNVM_IlluminationElement_Get_BsShare_VisMeet_Element: operation=rp_GetNVM_IlluminationElement.Get_BsShare_VisMeet_Element
            OA_rp_GetNVM_IlluminationElement_Get_BsShare_VisMeet_EOLEntry_Element: operation=rp_GetNVM_IlluminationElement.Get_BsShare_VisMeet_EOLEntry_Element
            OA_rp_GetNVM_IlluminationElement_Get_BsShare_VehicleConfig_Element: operation=rp_GetNVM_IlluminationElement.Get_BsShare_VehicleConfig_Element
            OA_rp_GetNVM_IlluminationElement_Get_BsConst_SpeedoGauge_Element: operation=rp_GetNVM_IlluminationElement.Get_BsConst_SpeedoGauge_Element
            OA_rp_GetNVM_IlluminationElement_Get_BsConst_TachoGauge_Element: operation=rp_GetNVM_IlluminationElement.Get_BsConst_TachoGauge_Element
            OA_rp_GetNVM_IlluminationElement_Get_BsConst_FuelGauge_Element: operation=rp_GetNVM_IlluminationElement.Get_BsConst_FuelGauge_Element
            OA_rp_GetNVM_IlluminationElement_Get_BsConst_TempGauge_Element: operation=rp_GetNVM_IlluminationElement.Get_BsConst_TempGauge_Element
            OA_rp_GetNVM_IlluminationElement_Get_BsConst_PowerGauge_Element: operation=rp_GetNVM_IlluminationElement.Get_BsConst_PowerGauge_Element
            OA_rp_GetNVM_IlluminationElement_Get_BsConst_OilGauge_Element: operation=rp_GetNVM_IlluminationElement.Get_BsConst_OilGauge_Element
            OA_rp_GetNVM_IlluminationElement_Get_BsConst_TripComputer_Element: operation=rp_GetNVM_IlluminationElement.Get_BsConst_TripComputer_Element
            OA_rp_GetNVM_IlluminationElement_Get_BsConst_Compensation_Line_Slope_m: operation=rp_GetNVM_IlluminationElement.Get_BsConst_Compensation_Line_Slope_m
            OA_rp_GetNVM_IlluminationElement_Get_BsConst_Compensation_Line_Shift_b: operation=rp_GetNVM_IlluminationElement.Get_BsConst_Compensation_Line_Shift_b
            OA_rp_GetNVM_IlluminationElement_Get_BsConst_Lookup_Curve_HotSpot_Coef_X: operation=rp_GetNVM_IlluminationElement.Get_BsConst_Lookup_Curve_HotSpot_Coef_X
            OA_rp_GetNVM_IlluminationElement_Get_BsConst_Lookup_Curve_HotSpot_Coef_Y: operation=rp_GetNVM_IlluminationElement.Get_BsConst_Lookup_Curve_HotSpot_Coef_Y
            OA_rp_GetNVM_IlluminationElement_Get_BsConst_Temp_Threshold_Hysteresis_Derating: operation=rp_GetNVM_IlluminationElement.Get_BsConst_Temp_Threshold_Hysteresis_Derating
            OA_rp_GetNVM_IlluminationElement_Get_BsConst_Derating_Backlight_Disable: operation=rp_GetNVM_IlluminationElement.Get_BsConst_Derating_Backlight_Disable
            OA_rp_GetNVM_IlluminationElement_Get_BsConst_Temperature_Sensor_Conv: operation=rp_GetNVM_IlluminationElement.Get_BsConst_Temperature_Sensor_Conv
            OA_rp_GetNVM_IlluminationElement_Get_BsConst_PCB_Temperature_Sensor_Conv: operation=rp_GetNVM_IlluminationElement.Get_BsConst_PCB_Temperature_Sensor_Conv
            OA_rp_GetNVM_IlluminationElement_Get_BsConst_Display_Illum_Max_Level: operation=rp_GetNVM_IlluminationElement.Get_BsConst_Display_Illum_Max_Level
            OA_rp_GetNVM_IlluminationElement_Get_BsConst_PWM_boost_bypass_duty: operation=rp_GetNVM_IlluminationElement.Get_BsConst_PWM_boost_bypass_duty
            OA_rp_GetNVM_IlluminationElement_Get_BsConst_BsConst_Illumination_ReservedByte: operation=rp_GetNVM_IlluminationElement.Get_BsConst_BsConst_Illumination_ReservedByte
            OA_rp_GetNVM_IlluminationElement_Get_BsConst_Compensation_Line_Slope_m_SafeCopy1: operation=rp_GetNVM_IlluminationElement.Get_BsConst_Compensation_Line_Slope_m_SafeCopy1
            OA_rp_GetNVM_IlluminationElement_Get_BsConst_Compensation_Line_Shift_b_SafeCopy1: operation=rp_GetNVM_IlluminationElement.Get_BsConst_Compensation_Line_Shift_b_SafeCopy1
            OA_rp_GetNVM_IlluminationElement_Get_BsConst_Lookup_Curve_HotSpot_Coef_X_SafeCopy1: operation=rp_GetNVM_IlluminationElement.Get_BsConst_Lookup_Curve_HotSpot_Coef_X_SafeCopy1
            OA_rp_GetNVM_IlluminationElement_Get_BsConst_Lookup_Curve_HotSpot_Coef_Y_SafeCopy1: operation=rp_GetNVM_IlluminationElement.Get_BsConst_Lookup_Curve_HotSpot_Coef_Y_SafeCopy1
            OA_rp_GetNVM_IlluminationElement_Get_BsConst_Temp_Threshold_Hysteresis_Derating_SafeCopy1: operation=rp_GetNVM_IlluminationElement.Get_BsConst_Temp_Threshold_Hysteresis_Derating_SafeCopy1
            OA_rp_GetNVM_IlluminationElement_Get_BsConst_Derating_Backlight_Disable_SafeCopy1: operation=rp_GetNVM_IlluminationElement.Get_BsConst_Derating_Backlight_Disable_SafeCopy1
            OA_rp_GetNVM_IlluminationElement_Get_BsConst_Temperature_Sensor_Conv_SafeCopy1: operation=rp_GetNVM_IlluminationElement.Get_BsConst_Temperature_Sensor_Conv_SafeCopy1
            OA_rp_GetNVM_IlluminationElement_Get_BsConst_PCB_Temperature_Sensor_Conv_SafeCopy1: operation=rp_GetNVM_IlluminationElement.Get_BsConst_PCB_Temperature_Sensor_Conv_SafeCopy1
            OA_rp_GetNVM_IlluminationElement_Get_BsConst_Display_Illum_Max_Level_SafeCopy1: operation=rp_GetNVM_IlluminationElement.Get_BsConst_Display_Illum_Max_Level_SafeCopy1
            OA_rp_GetNVM_IlluminationElement_Get_BsConst_PWM_boost_bypass_duty_SafeCopy1: operation=rp_GetNVM_IlluminationElement.Get_BsConst_PWM_boost_bypass_duty_SafeCopy1
            OA_rp_GetNVM_IlluminationElement_Get_BsConst_BsConst_Illumination_ReservedByte_SafeCopy1: operation=rp_GetNVM_IlluminationElement.Get_BsConst_BsConst_Illumination_ReservedByte_SafeCopy1
            OA_rp_GetNVM_IlluminationElement_Get_BsConst_Compensation_Line_Slope_m_SafeCopy2: operation=rp_GetNVM_IlluminationElement.Get_BsConst_Compensation_Line_Slope_m_SafeCopy2
            OA_rp_GetNVM_IlluminationElement_Get_BsConst_Compensation_Line_Shift_b_SafeCopy2: operation=rp_GetNVM_IlluminationElement.Get_BsConst_Compensation_Line_Shift_b_SafeCopy2
            OA_rp_GetNVM_IlluminationElement_Get_BsConst_Lookup_Curve_HotSpot_Coef_X_SafeCopy2: operation=rp_GetNVM_IlluminationElement.Get_BsConst_Lookup_Curve_HotSpot_Coef_X_SafeCopy2
            OA_rp_GetNVM_IlluminationElement_Get_BsConst_Lookup_Curve_HotSpot_Coef_Y_SafeCopy2: operation=rp_GetNVM_IlluminationElement.Get_BsConst_Lookup_Curve_HotSpot_Coef_Y_SafeCopy2
            OA_rp_GetNVM_IlluminationElement_Get_BsConst_Temp_Threshold_Hysteresis_Derating_SafeCopy2: operation=rp_GetNVM_IlluminationElement.Get_BsConst_Temp_Threshold_Hysteresis_Derating_SafeCopy2
            OA_rp_GetNVM_IlluminationElement_Get_BsConst_Derating_Backlight_Disable_SafeCopy2: operation=rp_GetNVM_IlluminationElement.Get_BsConst_Derating_Backlight_Disable_SafeCopy2
            OA_rp_GetNVM_IlluminationElement_Get_BsConst_Temperature_Sensor_Conv_SafeCopy2: operation=rp_GetNVM_IlluminationElement.Get_BsConst_Temperature_Sensor_Conv_SafeCopy2
            OA_rp_GetNVM_IlluminationElement_Get_BsConst_PCB_Temperature_Sensor_Conv_SafeCopy2: operation=rp_GetNVM_IlluminationElement.Get_BsConst_PCB_Temperature_Sensor_Conv_SafeCopy2
            OA_rp_GetNVM_IlluminationElement_Get_BsConst_Display_Illum_Max_Level_SafeCopy2: operation=rp_GetNVM_IlluminationElement.Get_BsConst_Display_Illum_Max_Level_SafeCopy2
            OA_rp_GetNVM_IlluminationElement_Get_BsConst_PWM_boost_bypass_duty_SafeCopy2: operation=rp_GetNVM_IlluminationElement.Get_BsConst_PWM_boost_bypass_duty_SafeCopy2
            OA_rp_GetNVM_IlluminationElement_Get_BsConst_BsConst_Illumination_ReservedByte_SafeCopy2: operation=rp_GetNVM_IlluminationElement.Get_BsConst_BsConst_Illumination_ReservedByte_SafeCopy2
            OA_rp_GetNVM_IlluminationElement_Get_BsConst_Audio_Element: operation=rp_GetNVM_IlluminationElement.Get_BsConst_Audio_Element
            OA_rp_GetNVM_IlluminationElement_Get_BsConst_Warning_Element: operation=rp_GetNVM_IlluminationElement.Get_BsConst_Warning_Element
            OA_rp_GetNVM_IlluminationElement_Get_BsConst_RealTimeClock_Element: operation=rp_GetNVM_IlluminationElement.Get_BsConst_RealTimeClock_Element
            OA_rp_GetNVM_IlluminationElement_Get_BsConst_Communication_Element: operation=rp_GetNVM_IlluminationElement.Get_BsConst_Communication_Element
            OA_rp_GetNVM_IlluminationElement_Get_BsConst_Power_Element: operation=rp_GetNVM_IlluminationElement.Get_BsConst_Power_Element
            OA_rp_GetNVM_IlluminationElement_Get_BsConst_ServiceReminder_Element: operation=rp_GetNVM_IlluminationElement.Get_BsConst_ServiceReminder_Element
            OA_rp_GetNVM_IlluminationElement_Get_BsConst_EngOffTimer_Element: operation=rp_GetNVM_IlluminationElement.Get_BsConst_EngOffTimer_Element
            OA_rp_GetNVM_IlluminationElement_Get_BsCys_Certicificate_Element: operation=rp_GetNVM_IlluminationElement.Get_BsCys_Certicificate_Element
            OA_rp_GetNVM_IlluminationElement_Get_RefCys_Certicificate_Element: operation=rp_GetNVM_IlluminationElement.Get_RefCys_Certicificate_Element
            OA_rp_GetNVM_IlluminationElement_Get_RefCys_Certicificate1_Element: operation=rp_GetNVM_IlluminationElement.Get_RefCys_Certicificate1_Element
            OA_rp_GetNVM_IlluminationElement_Get_BsRt_Odometer_Element: operation=rp_GetNVM_IlluminationElement.Get_BsRt_Odometer_Element
            OA_rp_GetNVM_IlluminationElement_Get_BsRt_SpeedoGauge_Element: operation=rp_GetNVM_IlluminationElement.Get_BsRt_SpeedoGauge_Element
            OA_rp_GetNVM_IlluminationElement_Get_BsRt_TachoGauge_Element: operation=rp_GetNVM_IlluminationElement.Get_BsRt_TachoGauge_Element
            OA_rp_GetNVM_IlluminationElement_Get_BsRt_FuelGauge_Element: operation=rp_GetNVM_IlluminationElement.Get_BsRt_FuelGauge_Element
            OA_rp_GetNVM_IlluminationElement_Get_BsRt_TempGauge_Element: operation=rp_GetNVM_IlluminationElement.Get_BsRt_TempGauge_Element
            OA_rp_GetNVM_IlluminationElement_Get_BsRt_PowerGauge_Element: operation=rp_GetNVM_IlluminationElement.Get_BsRt_PowerGauge_Element
            OA_rp_GetNVM_IlluminationElement_Get_BsRt_OilGauge_Element: operation=rp_GetNVM_IlluminationElement.Get_BsRt_OilGauge_Element
            OA_rp_GetNVM_IlluminationElement_Get_BsRt_TripComputer_Element: operation=rp_GetNVM_IlluminationElement.Get_BsRt_TripComputer_Element
            OA_rp_GetNVM_IlluminationElement_Get_BsRt_Warning_Element: operation=rp_GetNVM_IlluminationElement.Get_BsRt_Warning_Element
            OA_rp_GetNVM_IlluminationElement_Get_BsRt_RealTimeClock_Element: operation=rp_GetNVM_IlluminationElement.Get_BsRt_RealTimeClock_Element
            OA_rp_GetNVM_IlluminationElement_Get_BsRt_Personalization_Element: operation=rp_GetNVM_IlluminationElement.Get_BsRt_Personalization_Element
            OA_rp_GetNVM_IlluminationElement_Get_BsRt_Illumination_Element: operation=rp_GetNVM_IlluminationElement.Get_BsRt_Illumination_Element
            OA_rp_GetNVM_IlluminationElement_Get_BsRt_CusDlt_Element: operation=rp_GetNVM_IlluminationElement.Get_BsRt_CusDlt_Element
            OA_rp_GetNVM_IlluminationElement_Get_BsReten_Odometer_Element: operation=rp_GetNVM_IlluminationElement.Get_BsReten_Odometer_Element
            OA_rp_GetNVM_IlluminationElement_Get_BsReten_Gauges_Element: operation=rp_GetNVM_IlluminationElement.Get_BsReten_Gauges_Element
            OA_rp_GetNVM_IlluminationElement_Get_BsReten_Tripcomputer_Element: operation=rp_GetNVM_IlluminationElement.Get_BsReten_Tripcomputer_Element
            OA_rp_GetNVM_IlluminationElement_Get_BsReten_Illumination_Element: operation=rp_GetNVM_IlluminationElement.Get_BsReten_Illumination_Element
            OA_rp_GetNVM_IlluminationElement_Get_BsReten_Audio_Element: operation=rp_GetNVM_IlluminationElement.Get_BsReten_Audio_Element
            OA_rp_GetNVM_IlluminationElement_Get_BsReten_Warning_Element: operation=rp_GetNVM_IlluminationElement.Get_BsReten_Warning_Element
            OA_rp_GetNVM_IlluminationElement_Get_BsReten_RealTimeClock_Element: operation=rp_GetNVM_IlluminationElement.Get_BsReten_RealTimeClock_Element
            OA_rp_GetNVM_IlluminationElement_Get_BsReten_Communication_Element: operation=rp_GetNVM_IlluminationElement.Get_BsReten_Communication_Element
            OA_rp_GetNVM_IlluminationElement_Get_BsReten_Personalization_Element: operation=rp_GetNVM_IlluminationElement.Get_BsReten_Personalization_Element
            OA_rp_GetNVM_IlluminationElement_Get_BsReten_Power_Element: operation=rp_GetNVM_IlluminationElement.Get_BsReten_Power_Element
            OA_rp_GetNVM_IlluminationElement_Get_BsReten_Display_Element: operation=rp_GetNVM_IlluminationElement.Get_BsReten_Display_Element
            OA_rp_GetNVM_IlluminationElement_Get_BsDiag_ErrorRecord_Element: operation=rp_GetNVM_IlluminationElement.Get_BsDiag_ErrorRecord_Element
            OA_rp_GetNVM_IlluminationElement_Get_BsDiag_Dtc_Element: operation=rp_GetNVM_IlluminationElement.Get_BsDiag_Dtc_Element
            OA_rp_ILL_ReadyToSleep_SWCSleepStatus: operation=rp_ILL_ReadyToSleep.SWCSleepStatus
            OA_rp_PwmSetDuty_PwmSetDuty: operation=rp_PwmSetDuty.PwmSetDuty
            OA_rp_PwmSetDuty_PwmSetDutyAndPeriod: operation=rp_PwmSetDuty.PwmSetDutyAndPeriod
            OA_rp_PwmSetDuty_PwmSetIdeal: operation=rp_PwmSetDuty.PwmSetIdeal
            OA_rp_SetNVM_IlluminationElement_Set_BsShare_SwUpdReflash_Element: operation=rp_SetNVM_IlluminationElement.Set_BsShare_SwUpdReflash_Element
            OA_rp_SetNVM_IlluminationElement_Set_BsShare_SwUpdFotaMode_Element: operation=rp_SetNVM_IlluminationElement.Set_BsShare_SwUpdFotaMode_Element
            OA_rp_SetNVM_IlluminationElement_Set_BsShare_SwUpdFotaFinPrint_Element: operation=rp_SetNVM_IlluminationElement.Set_BsShare_SwUpdFotaFinPrint_Element
            OA_rp_SetNVM_IlluminationElement_Set_BsShare_SwUpdFotaStatus_Element: operation=rp_SetNVM_IlluminationElement.Set_BsShare_SwUpdFotaStatus_Element
            OA_rp_SetNVM_IlluminationElement_Set_BsShare_SwUpdFotadecrypt_Element: operation=rp_SetNVM_IlluminationElement.Set_BsShare_SwUpdFotadecrypt_Element
            OA_rp_SetNVM_IlluminationElement_Set_BsShare_EcuPartNumber_Element: operation=rp_SetNVM_IlluminationElement.Set_BsShare_EcuPartNumber_Element
            OA_rp_SetNVM_IlluminationElement_Set_BsShare_VisteonPartNumber: operation=rp_SetNVM_IlluminationElement.Set_BsShare_VisteonPartNumber
            OA_rp_SetNVM_IlluminationElement_Set_BsShare_VisteonPCBPartNumber: operation=rp_SetNVM_IlluminationElement.Set_BsShare_VisteonPCBPartNumber
            OA_rp_SetNVM_IlluminationElement_Set_BsShare_ProductSerialNumber: operation=rp_SetNVM_IlluminationElement.Set_BsShare_ProductSerialNumber
            OA_rp_SetNVM_IlluminationElement_Set_BsShare_PCBSerialNumber: operation=rp_SetNVM_IlluminationElement.Set_BsShare_PCBSerialNumber
            OA_rp_SetNVM_IlluminationElement_Set_BsShare_SMTManufacturingDate: operation=rp_SetNVM_IlluminationElement.Set_BsShare_SMTManufacturingDate
            OA_rp_SetNVM_IlluminationElement_Set_BsShare_AssemblyManufacturingDate: operation=rp_SetNVM_IlluminationElement.Set_BsShare_AssemblyManufacturingDate
            OA_rp_SetNVM_IlluminationElement_Set_BsShare_SMTPlantNumber: operation=rp_SetNVM_IlluminationElement.Set_BsShare_SMTPlantNumber
            OA_rp_SetNVM_IlluminationElement_Set_BsShare_AssemblyPlantNumber: operation=rp_SetNVM_IlluminationElement.Set_BsShare_AssemblyPlantNumber
            OA_rp_SetNVM_IlluminationElement_Set_BsShare_HWModification: operation=rp_SetNVM_IlluminationElement.Set_BsShare_HWModification
            OA_rp_SetNVM_IlluminationElement_Set_BsShare_VisMeet_Element: operation=rp_SetNVM_IlluminationElement.Set_BsShare_VisMeet_Element
            OA_rp_SetNVM_IlluminationElement_Set_BsShare_VisMeet_EOLEntry_Element: operation=rp_SetNVM_IlluminationElement.Set_BsShare_VisMeet_EOLEntry_Element
            OA_rp_SetNVM_IlluminationElement_Set_BsShare_VehicleConfig_Element: operation=rp_SetNVM_IlluminationElement.Set_BsShare_VehicleConfig_Element
            OA_rp_SetNVM_IlluminationElement_Set_BsConst_SpeedoGauge_Element: operation=rp_SetNVM_IlluminationElement.Set_BsConst_SpeedoGauge_Element
            OA_rp_SetNVM_IlluminationElement_Set_BsConst_TachoGauge_Element: operation=rp_SetNVM_IlluminationElement.Set_BsConst_TachoGauge_Element
            OA_rp_SetNVM_IlluminationElement_Set_BsConst_FuelGauge_Element: operation=rp_SetNVM_IlluminationElement.Set_BsConst_FuelGauge_Element
            OA_rp_SetNVM_IlluminationElement_Set_BsConst_TempGauge_Element: operation=rp_SetNVM_IlluminationElement.Set_BsConst_TempGauge_Element
            OA_rp_SetNVM_IlluminationElement_Set_BsConst_PowerGauge_Element: operation=rp_SetNVM_IlluminationElement.Set_BsConst_PowerGauge_Element
            OA_rp_SetNVM_IlluminationElement_Set_BsConst_OilGauge_Element: operation=rp_SetNVM_IlluminationElement.Set_BsConst_OilGauge_Element
            OA_rp_SetNVM_IlluminationElement_Set_BsConst_TripComputer_Element: operation=rp_SetNVM_IlluminationElement.Set_BsConst_TripComputer_Element
            OA_rp_SetNVM_IlluminationElement_Set_BsConst_Compensation_Line_Slope_m: operation=rp_SetNVM_IlluminationElement.Set_BsConst_Compensation_Line_Slope_m
            OA_rp_SetNVM_IlluminationElement_Set_BsConst_Compensation_Line_Shift_b: operation=rp_SetNVM_IlluminationElement.Set_BsConst_Compensation_Line_Shift_b
            OA_rp_SetNVM_IlluminationElement_Set_BsConst_Lookup_Curve_HotSpot_Coef_X: operation=rp_SetNVM_IlluminationElement.Set_BsConst_Lookup_Curve_HotSpot_Coef_X
            OA_rp_SetNVM_IlluminationElement_Set_BsConst_Lookup_Curve_HotSpot_Coef_Y: operation=rp_SetNVM_IlluminationElement.Set_BsConst_Lookup_Curve_HotSpot_Coef_Y
            OA_rp_SetNVM_IlluminationElement_Set_BsConst_Temp_Threshold_Hysteresis_Derating: operation=rp_SetNVM_IlluminationElement.Set_BsConst_Temp_Threshold_Hysteresis_Derating
            OA_rp_SetNVM_IlluminationElement_Set_BsConst_Derating_Backlight_Disable: operation=rp_SetNVM_IlluminationElement.Set_BsConst_Derating_Backlight_Disable
            OA_rp_SetNVM_IlluminationElement_Set_BsConst_Temperature_Sensor_Conv: operation=rp_SetNVM_IlluminationElement.Set_BsConst_Temperature_Sensor_Conv
            OA_rp_SetNVM_IlluminationElement_Set_BsConst_PCB_Temperature_Sensor_Conv: operation=rp_SetNVM_IlluminationElement.Set_BsConst_PCB_Temperature_Sensor_Conv
            OA_rp_SetNVM_IlluminationElement_Set_BsConst_Display_Illum_Max_Level: operation=rp_SetNVM_IlluminationElement.Set_BsConst_Display_Illum_Max_Level
            OA_rp_SetNVM_IlluminationElement_Set_BsConst_PWM_boost_bypass_duty: operation=rp_SetNVM_IlluminationElement.Set_BsConst_PWM_boost_bypass_duty
            OA_rp_SetNVM_IlluminationElement_Set_BsConst_BsConst_Illumination_ReservedByte: operation=rp_SetNVM_IlluminationElement.Set_BsConst_BsConst_Illumination_ReservedByte
            OA_rp_SetNVM_IlluminationElement_Set_BsConst_Compensation_Line_Slope_m_SafeCopy1: operation=rp_SetNVM_IlluminationElement.Set_BsConst_Compensation_Line_Slope_m_SafeCopy1
            OA_rp_SetNVM_IlluminationElement_Set_BsConst_Compensation_Line_Shift_b_SafeCopy1: operation=rp_SetNVM_IlluminationElement.Set_BsConst_Compensation_Line_Shift_b_SafeCopy1
            OA_rp_SetNVM_IlluminationElement_Set_BsConst_Lookup_Curve_HotSpot_Coef_X_SafeCopy1: operation=rp_SetNVM_IlluminationElement.Set_BsConst_Lookup_Curve_HotSpot_Coef_X_SafeCopy1
            OA_rp_SetNVM_IlluminationElement_Set_BsConst_Lookup_Curve_HotSpot_Coef_Y_SafeCopy1: operation=rp_SetNVM_IlluminationElement.Set_BsConst_Lookup_Curve_HotSpot_Coef_Y_SafeCopy1
            OA_rp_SetNVM_IlluminationElement_Set_BsConst_Temp_Threshold_Hysteresis_Derating_SafeCopy1: operation=rp_SetNVM_IlluminationElement.Set_BsConst_Temp_Threshold_Hysteresis_Derating_SafeCopy1
            OA_rp_SetNVM_IlluminationElement_Set_BsConst_Derating_Backlight_Disable_SafeCopy1: operation=rp_SetNVM_IlluminationElement.Set_BsConst_Derating_Backlight_Disable_SafeCopy1
            OA_rp_SetNVM_IlluminationElement_Set_BsConst_Temperature_Sensor_Conv_SafeCopy1: operation=rp_SetNVM_IlluminationElement.Set_BsConst_Temperature_Sensor_Conv_SafeCopy1
            OA_rp_SetNVM_IlluminationElement_Set_BsConst_PCB_Temperature_Sensor_Conv_SafeCopy1: operation=rp_SetNVM_IlluminationElement.Set_BsConst_PCB_Temperature_Sensor_Conv_SafeCopy1
            OA_rp_SetNVM_IlluminationElement_Set_BsConst_Display_Illum_Max_Level_SafeCopy1: operation=rp_SetNVM_IlluminationElement.Set_BsConst_Display_Illum_Max_Level_SafeCopy1
            OA_rp_SetNVM_IlluminationElement_Set_BsConst_PWM_boost_bypass_duty_SafeCopy1: operation=rp_SetNVM_IlluminationElement.Set_BsConst_PWM_boost_bypass_duty_SafeCopy1
            OA_rp_SetNVM_IlluminationElement_Set_BsConst_BsConst_Illumination_ReservedByte_SafeCopy1: operation=rp_SetNVM_IlluminationElement.Set_BsConst_BsConst_Illumination_ReservedByte_SafeCopy1
            OA_rp_SetNVM_IlluminationElement_Set_BsConst_Compensation_Line_Slope_m_SafeCopy2: operation=rp_SetNVM_IlluminationElement.Set_BsConst_Compensation_Line_Slope_m_SafeCopy2
            OA_rp_SetNVM_IlluminationElement_Set_BsConst_Compensation_Line_Shift_b_SafeCopy2: operation=rp_SetNVM_IlluminationElement.Set_BsConst_Compensation_Line_Shift_b_SafeCopy2
            OA_rp_SetNVM_IlluminationElement_Set_BsConst_Lookup_Curve_HotSpot_Coef_X_SafeCopy2: operation=rp_SetNVM_IlluminationElement.Set_BsConst_Lookup_Curve_HotSpot_Coef_X_SafeCopy2
            OA_rp_SetNVM_IlluminationElement_Set_BsConst_Lookup_Curve_HotSpot_Coef_Y_SafeCopy2: operation=rp_SetNVM_IlluminationElement.Set_BsConst_Lookup_Curve_HotSpot_Coef_Y_SafeCopy2
            OA_rp_SetNVM_IlluminationElement_Set_BsConst_Temp_Threshold_Hysteresis_Derating_SafeCopy2: operation=rp_SetNVM_IlluminationElement.Set_BsConst_Temp_Threshold_Hysteresis_Derating_SafeCopy2
            OA_rp_SetNVM_IlluminationElement_Set_BsConst_Derating_Backlight_Disable_SafeCopy2: operation=rp_SetNVM_IlluminationElement.Set_BsConst_Derating_Backlight_Disable_SafeCopy2
            OA_rp_SetNVM_IlluminationElement_Set_BsConst_Temperature_Sensor_Conv_SafeCopy2: operation=rp_SetNVM_IlluminationElement.Set_BsConst_Temperature_Sensor_Conv_SafeCopy2
            OA_rp_SetNVM_IlluminationElement_Set_BsConst_PCB_Temperature_Sensor_Conv_SafeCopy2: operation=rp_SetNVM_IlluminationElement.Set_BsConst_PCB_Temperature_Sensor_Conv_SafeCopy2
            OA_rp_SetNVM_IlluminationElement_Set_BsConst_Display_Illum_Max_Level_SafeCopy2: operation=rp_SetNVM_IlluminationElement.Set_BsConst_Display_Illum_Max_Level_SafeCopy2
            OA_rp_SetNVM_IlluminationElement_Set_BsConst_PWM_boost_bypass_duty_SafeCopy2: operation=rp_SetNVM_IlluminationElement.Set_BsConst_PWM_boost_bypass_duty_SafeCopy2
            OA_rp_SetNVM_IlluminationElement_Set_BsConst_BsConst_Illumination_ReservedByte_SafeCopy2: operation=rp_SetNVM_IlluminationElement.Set_BsConst_BsConst_Illumination_ReservedByte_SafeCopy2
            OA_rp_SetNVM_IlluminationElement_Set_BsConst_Audio_Element: operation=rp_SetNVM_IlluminationElement.Set_BsConst_Audio_Element
            OA_rp_SetNVM_IlluminationElement_Set_BsConst_Warning_Element: operation=rp_SetNVM_IlluminationElement.Set_BsConst_Warning_Element
            OA_rp_SetNVM_IlluminationElement_Set_BsConst_RealTimeClock_Element: operation=rp_SetNVM_IlluminationElement.Set_BsConst_RealTimeClock_Element
            OA_rp_SetNVM_IlluminationElement_Set_BsConst_Communication_Element: operation=rp_SetNVM_IlluminationElement.Set_BsConst_Communication_Element
            OA_rp_SetNVM_IlluminationElement_Set_BsConst_Power_Element: operation=rp_SetNVM_IlluminationElement.Set_BsConst_Power_Element
            OA_rp_SetNVM_IlluminationElement_Set_BsConst_ServiceReminder_Element: operation=rp_SetNVM_IlluminationElement.Set_BsConst_ServiceReminder_Element
            OA_rp_SetNVM_IlluminationElement_Set_BsConst_EngOffTimer_Element: operation=rp_SetNVM_IlluminationElement.Set_BsConst_EngOffTimer_Element
            OA_rp_SetNVM_IlluminationElement_Set_BsCys_Certicificate_Element: operation=rp_SetNVM_IlluminationElement.Set_BsCys_Certicificate_Element
            OA_rp_SetNVM_IlluminationElement_Set_RefCys_Certicificate_Element: operation=rp_SetNVM_IlluminationElement.Set_RefCys_Certicificate_Element
            OA_rp_SetNVM_IlluminationElement_Set_RefCys_Certicificate1_Element: operation=rp_SetNVM_IlluminationElement.Set_RefCys_Certicificate1_Element
            OA_rp_SetNVM_IlluminationElement_Set_BsRt_Odometer_Element: operation=rp_SetNVM_IlluminationElement.Set_BsRt_Odometer_Element
            OA_rp_SetNVM_IlluminationElement_Set_BsRt_SpeedoGauge_Element: operation=rp_SetNVM_IlluminationElement.Set_BsRt_SpeedoGauge_Element
            OA_rp_SetNVM_IlluminationElement_Set_BsRt_TachoGauge_Element: operation=rp_SetNVM_IlluminationElement.Set_BsRt_TachoGauge_Element
            OA_rp_SetNVM_IlluminationElement_Set_BsRt_FuelGauge_Element: operation=rp_SetNVM_IlluminationElement.Set_BsRt_FuelGauge_Element
            OA_rp_SetNVM_IlluminationElement_Set_BsRt_TempGauge_Element: operation=rp_SetNVM_IlluminationElement.Set_BsRt_TempGauge_Element
            OA_rp_SetNVM_IlluminationElement_Set_BsRt_PowerGauge_Element: operation=rp_SetNVM_IlluminationElement.Set_BsRt_PowerGauge_Element
            OA_rp_SetNVM_IlluminationElement_Set_BsRt_OilGauge_Element: operation=rp_SetNVM_IlluminationElement.Set_BsRt_OilGauge_Element
            OA_rp_SetNVM_IlluminationElement_Set_BsRt_TripComputer_Element: operation=rp_SetNVM_IlluminationElement.Set_BsRt_TripComputer_Element
            OA_rp_SetNVM_IlluminationElement_Set_BsRt_Warning_Element: operation=rp_SetNVM_IlluminationElement.Set_BsRt_Warning_Element
            OA_rp_SetNVM_IlluminationElement_Set_BsRt_RealTimeClock_Element: operation=rp_SetNVM_IlluminationElement.Set_BsRt_RealTimeClock_Element
            OA_rp_SetNVM_IlluminationElement_Set_BsRt_Personalization_Element: operation=rp_SetNVM_IlluminationElement.Set_BsRt_Personalization_Element
            OA_rp_SetNVM_IlluminationElement_Set_BsRt_Illumination_Element: operation=rp_SetNVM_IlluminationElement.Set_BsRt_Illumination_Element
            OA_rp_SetNVM_IlluminationElement_Set_BsRt_CusDlt_Element: operation=rp_SetNVM_IlluminationElement.Set_BsRt_CusDlt_Element
            OA_rp_SetNVM_IlluminationElement_Set_BsReten_Odometer_Element: operation=rp_SetNVM_IlluminationElement.Set_BsReten_Odometer_Element
            OA_rp_SetNVM_IlluminationElement_Set_BsReten_Gauges_Element: operation=rp_SetNVM_IlluminationElement.Set_BsReten_Gauges_Element
            OA_rp_SetNVM_IlluminationElement_Set_BsReten_Tripcomputer_Element: operation=rp_SetNVM_IlluminationElement.Set_BsReten_Tripcomputer_Element
            OA_rp_SetNVM_IlluminationElement_Set_BsReten_Illumination_Element: operation=rp_SetNVM_IlluminationElement.Set_BsReten_Illumination_Element
            OA_rp_SetNVM_IlluminationElement_Set_BsReten_Audio_Element: operation=rp_SetNVM_IlluminationElement.Set_BsReten_Audio_Element
            OA_rp_SetNVM_IlluminationElement_Set_BsReten_Warning_Element: operation=rp_SetNVM_IlluminationElement.Set_BsReten_Warning_Element
            OA_rp_SetNVM_IlluminationElement_Set_BsReten_RealTimeClock_Element: operation=rp_SetNVM_IlluminationElement.Set_BsReten_RealTimeClock_Element
            OA_rp_SetNVM_IlluminationElement_Set_BsReten_Communication_Element: operation=rp_SetNVM_IlluminationElement.Set_BsReten_Communication_Element
            OA_rp_SetNVM_IlluminationElement_Set_BsReten_Personalization_Element: operation=rp_SetNVM_IlluminationElement.Set_BsReten_Personalization_Element
            OA_rp_SetNVM_IlluminationElement_Set_BsReten_Power_Element: operation=rp_SetNVM_IlluminationElement.Set_BsReten_Power_Element
            OA_rp_SetNVM_IlluminationElement_Set_BsReten_Display_Element: operation=rp_SetNVM_IlluminationElement.Set_BsReten_Display_Element
            OA_rp_SetNVM_IlluminationElement_Set_BsDiag_ErrorRecord_Element: operation=rp_SetNVM_IlluminationElement.Set_BsDiag_ErrorRecord_Element
            OA_rp_SetNVM_IlluminationElement_Set_BsDiag_Dtc_Element: operation=rp_SetNVM_IlluminationElement.Set_BsDiag_Dtc_Element
            OA_rp_TmExt_Timer_IsElapsed_Timer_IsElapsed: operation=rp_TmExt_Timer_IsElapsed.Timer_IsElapsed
            OA_rp_TmExt_Timer_IsStarted_Timer_IsStarted: operation=rp_TmExt_Timer_IsStarted.Timer_IsStarted
            OA_rp_TmExt_Timer_Start_Timer_Start: operation=rp_TmExt_Timer_Start.Timer_Start
            OA_rp_TmExt_Timer_Stop_Timer_Stop: operation=rp_TmExt_Timer_Stop.Timer_Stop
  21 x constant specification:
    Ctrl_IlluminationILL_DutyValue0: value-spec=Ctrl_IlluminationILL_DutyValue0:0
    Ctrl_IlluminationRGB_DimmingValue0: value-spec=Ctrl_IlluminationRGB_DimmingValue0:0
    Ctrl_IlluminationStarter_StatusValue0: value-spec=Ctrl_IlluminationStarter_StatusValue0:false
    Ctrl_IlluminationReady_to_SleepValue0: value-spec=Ctrl_IlluminationReady_to_SleepValue0:false
    Ctrl_IlluminationIllumCtrl_Op_DataValue0: value-spec={short-label=Ctrl_IlluminationIllumCtrl_Op_DataValue0, fields=[Ctrl_IlluminationIllumCtrl_Op_DataValue_0:0, Ctrl_IlluminationIllumCtrl_Op_DataValue_1:0, Ctrl_IlluminationIllumCtrl_Op_DataValue_2:0, Ctrl_IlluminationIllumCtrl_Op_DataValue_3:0, Ctrl_IlluminationIllumCtrl_Op_DataValue_4:0, Ctrl_IlluminationIllumCtrl_Op_DataValue_5:0, Ctrl_IlluminationIllumCtrl_Op_DataValue_6:0, Ctrl_IlluminationIllumCtrl_Op_DataValue_7:0]}
    Ctrl_IlluminationIlumDayNightRequiredValue0: value-spec=Ctrl_IlluminationIlumDayNightRequiredValue0:0
    Ctrl_IlluminationDay_Night_StatusValue0: value-spec=Ctrl_IlluminationDay_Night_StatusValue0:0
    Ctrl_IlluminationBL_DimmingValue0: value-spec=Ctrl_IlluminationBL_DimmingValue0:0
    Ctrl_Illuminationchannel_idValue0: value-spec=Ctrl_Illuminationchannel_idValue0:0
    Ctrl_IlluminationIllumStatusValue0: value-spec=Ctrl_IlluminationIllumStatusValue0:0
    Ctrl_IlluminationIgnitionSubstateValue0: value-spec=Ctrl_IlluminationIgnitionSubstateValue0:0
    Ctrl_IlluminationWSSCurrentVehicleStateValue0: value-spec=Ctrl_IlluminationWSSCurrentVehicleStateValue0:0
    Ctrl_IlluminationWSSCurrentClusterModeValue0: value-spec=Ctrl_IlluminationWSSCurrentClusterModeValue0:0
    Ctrl_IlluminationDay_Night_mode_CtrlValue0: value-spec=Ctrl_IlluminationDay_Night_mode_CtrlValue0:0
    Ctrl_IlluminationEcoRunSystem_FlagValue0: value-spec=Ctrl_IlluminationEcoRunSystem_FlagValue0:0
    Ctrl_IlluminationIllumCtrl_Ip_DataValue0: value-spec={short-label=Ctrl_IlluminationIllumCtrl_Ip_DataValue0, fields=[Ctrl_IlluminationIllumCtrl_Ip_DataValue_0:0, Ctrl_IlluminationIllumCtrl_Ip_DataValue_1:0, Ctrl_IlluminationIllumCtrl_Ip_DataValue_2:0, Ctrl_IlluminationIllumCtrl_Ip_DataValue_3:0, Ctrl_IlluminationIllumCtrl_Ip_DataValue_4:0, Ctrl_IlluminationIllumCtrl_Ip_DataValue_5:0, Ctrl_IlluminationIllumCtrl_Ip_DataValue_6:0, Ctrl_IlluminationIllumCtrl_Ip_DataValue_7:0]}
    Ctrl_IlluminationIllumStepValueValue0: value-spec=Ctrl_IlluminationIllumStepValueValue0:0
    Ctrl_IlluminationRheostatDayStepValue0: value-spec=Ctrl_IlluminationRheostatDayStepValue0:0
    Ctrl_IlluminationRheostatNightStepValue0: value-spec=Ctrl_IlluminationRheostatNightStepValue0:0
    Ctrl_IlluminationRheoUpdateValValue0: value-spec=Ctrl_IlluminationRheoUpdateValValue0:0
    Ctrl_IlluminationTFTDisplayOnValue0: value-spec=Ctrl_IlluminationTFTDisplayOnValue0:0
  swc implementation IMPL_Ctrl_Illumination: programming-language=C, behavior=IB_Ctrl_Illumination
    code-descriptors:
      code CodeDescriptor
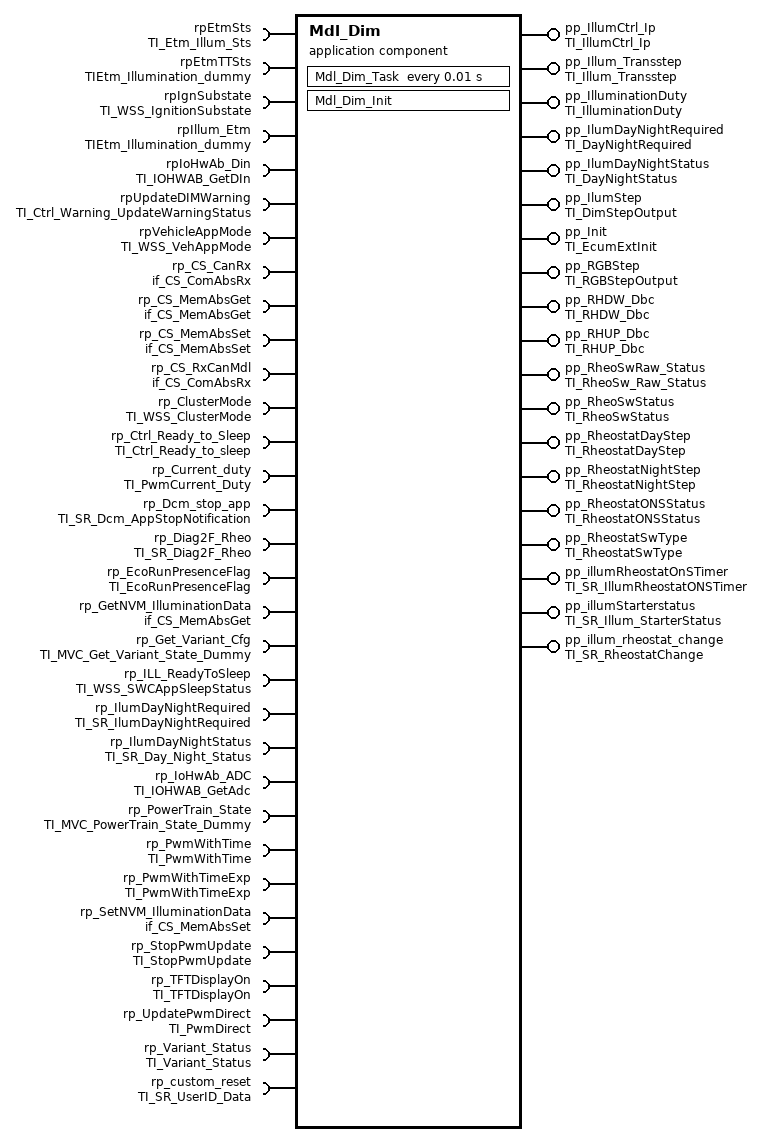
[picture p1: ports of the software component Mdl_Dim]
  application sw component type Mdl_Dim
    19 x provide port:
      pp_IllumCtrl_Ip: nonqueued-sender-com-spec{data-element=IllumCtrl_Ip_Data, init-value=constant-reference=Mdl_DimIllumCtrl_Ip_DataValue0}, provided-interface=TI_IllumCtrl_Ip
      pp_Illum_Transstep: nonqueued-sender-com-spec{data-element=Trans_Stepvlaue, init-value=constant-reference=Mdl_DimTrans_StepvlaueValue0}, provided-interface=TI_Illum_Transstep
      pp_IlluminationDuty: nonqueued-sender-com-spec{data-element=DutyValue, init-value=constant-reference=Mdl_DimDutyValueValue0}, provided-interface=TI_IlluminationDuty
      pp_IlumDayNightRequired: nonqueued-sender-com-spec{data-element=ilumDNRequired, init-value=constant-reference=Mdl_DimilumDNRequiredValue0}, provided-interface=TI_DayNightRequired
      pp_IlumDayNightStatus: nonqueued-sender-com-spec{data-element=illumDNStatus, init-value=constant-reference=Mdl_DimillumDNStatusValue0}, provided-interface=TI_DayNightStatus
      pp_IlumStep: nonqueued-sender-com-spec{data-element=IllumStepValue, init-value=constant-reference=Mdl_DimIllumStepValueValue0}, provided-interface=TI_DimStepOutput
      pp_Init: server-com-spec{operation=TI_EcumExtInit/Init, queue-length=1}, provided-interface=TI_EcumExtInit
      pp_RGBStep: nonqueued-sender-com-spec{data-element=RGBStepValue, init-value=constant-reference=Mdl_DimRGBStepValueValue0}, provided-interface=TI_RGBStepOutput
      pp_RHDW_Dbc: nonqueued-sender-com-spec{data-element=RHDW_Dbc, init-value=constant-reference=Mdl_DimRHDW_DbcValue0}, provided-interface=TI_RHDW_Dbc
      pp_RHUP_Dbc: nonqueued-sender-com-spec{data-element=RHUP_Dbc, init-value=constant-reference=Mdl_DimRHUP_DbcValue0}, provided-interface=TI_RHUP_Dbc
      pp_RheoSwRaw_Status: nonqueued-sender-com-spec{data-element=RawdataStatus, init-value=constant-reference=Mdl_DimRawdataStatusValue0}, provided-interface=TI_RheoSw_Raw_Status
      pp_RheoSwStatus: nonqueued-sender-com-spec{data-element=SwitchStatus, init-value=constant-reference=Mdl_DimSwitchStatusValue0}, provided-interface=TI_RheoSwStatus
      pp_RheostatDayStep: nonqueued-sender-com-spec{data-element=RheostatDayStep, init-value=constant-reference=Mdl_DimRheostatDayStepValue0}, provided-interface=TI_RheostatDayStep
      pp_RheostatNightStep: nonqueued-sender-com-spec{data-element=RheostatNightStep, init-value=constant-reference=Mdl_DimRheostatNightStepValue0}, provided-interface=TI_RheostatNightStep
      pp_RheostatONSStatus: nonqueued-sender-com-spec{data-element=RheostatONSStatus, init-value=constant-reference=Mdl_DimRheostatONSStatusValue0}, provided-interface=TI_RheostatONSStatus
      pp_RheostatSwType: nonqueued-sender-com-spec{data-element=RheostatSwType, init-value=constant-reference=Mdl_DimRheostatSwTypeValue0}, provided-interface=TI_RheostatSwType
      pp_illumRheostatOnSTimer: nonqueued-sender-com-spec{data-element=Rheostat_OnSTime, init-value=constant-reference=Mdl_DimRheostat_OnSTimeValue0}, provided-interface=TI_SR_IllumRheostatONSTimer
      pp_illumStarterstatus: nonqueued-sender-com-spec{data-element=StarterStatus_Out, init-value=constant-reference=Mdl_DimStarterStatus_OutValue0}, provided-interface=TI_SR_Illum_StarterStatus
      pp_illum_rheostat_change: nonqueued-sender-com-spec{data-element=RheoUpdateVal, init-value=constant-reference=Mdl_DimRheoUpdateValValue0}, provided-interface=TI_SR_RheostatChange
    32 x require port:
      rpEtmSts: nonqueued-receiver-com-spec{data-element=Illum_Status, init-value=constant-reference=Mdl_DimIllum_StatusValue0}, required-interface=TI_Etm_Illum_Sts
      rpEtmTTSts: nonqueued-receiver-com-spec{data-element=IllumStatus, init-value=constant-reference=Mdl_DimIllumStatusValue0}, required-interface=TIEtm_Illumination_dummy
      rpIgnSubstate: nonqueued-receiver-com-spec{data-element=IgnitionSubstate, init-value=constant-reference=Mdl_DimIgnitionSubstateValue0}, required-interface=TI_WSS_IgnitionSubstate
      rpIllum_Etm: nonqueued-receiver-com-spec{data-element=IllumStatus, init-value=constant-reference=Mdl_DimIllumStatusValue0}, required-interface=TIEtm_Illumination_dummy
      rpIoHwAb_Din: required-interface=TI_IOHWAB_GetDIn
      rpUpdateDIMWarning: required-interface=TI_Ctrl_Warning_UpdateWarningStatus
      rpVehicleAppMode: nonqueued-receiver-com-spec{data-element=WSSCurrentVehicleState, init-value=constant-reference=Mdl_DimWSSCurrentVehicleStateValue0}, required-interface=TI_WSS_VehAppMode
      rp_CS_CanRx: required-interface=if_CS_ComAbsRx
      rp_CS_MemAbsGet: required-interface=if_CS_MemAbsGet
      rp_CS_MemAbsSet: required-interface=if_CS_MemAbsSet
      rp_CS_RxCanMdl: required-interface=if_CS_ComAbsRx
      rp_ClusterMode: nonqueued-receiver-com-spec{data-element=WSSCurrentClusterMode, init-value=constant-reference=Mdl_DimWSSCurrentClusterModeValue0}, required-interface=TI_WSS_ClusterMode
      rp_Ctrl_Ready_to_Sleep: nonqueued-receiver-com-spec{data-element=Ready_to_Sleep, init-value=constant-reference=Mdl_DimReady_to_SleepValue0}, required-interface=TI_Ctrl_Ready_to_sleep
      rp_Current_duty: required-interface=TI_PwmCurrent_Duty
      rp_Dcm_stop_app: nonqueued-receiver-com-spec{data-element=AppId, init-value=constant-reference=Mdl_DimAppIdValue0}, required-interface=TI_SR_Dcm_AppStopNotification
      rp_Diag2F_Rheo: nonqueued-receiver-com-spec{data-element=Diag_RheoStat, init-value=constant-reference=Mdl_DimDiag_RheoStatValue0}, required-interface=TI_SR_Diag2F_Rheo
      rp_EcoRunPresenceFlag: nonqueued-receiver-com-spec{data-element=EcoRunPresenceFlag, init-value=constant-reference=Mdl_DimEcoRunPresenceFlagValue0}, required-interface=TI_EcoRunPresenceFlag
      rp_GetNVM_IlluminationData: required-interface=if_CS_MemAbsGet
      rp_Get_Variant_Cfg: required-interface=TI_MVC_Get_Variant_State_Dummy
      rp_ILL_ReadyToSleep: required-interface=TI_WSS_SWCAppSleepStatus
      rp_IlumDayNightRequired: nonqueued-receiver-com-spec{data-element=IlumDayNightRequired, init-value=constant-reference=Mdl_DimIlumDayNightRequiredValue0}, required-interface=TI_SR_IlumDayNightRequired
      rp_IlumDayNightStatus: nonqueued-receiver-com-spec{data-element=Day_Night_Status, init-value=constant-reference=Mdl_DimDay_Night_StatusValue0}, required-interface=TI_SR_Day_Night_Status
      rp_IoHwAb_ADC: required-interface=TI_IOHWAB_GetAdc
      rp_PowerTrain_State: nonqueued-receiver-com-spec{data-element=PowerTrain_Flag, init-value=constant-reference=Mdl_DimPowerTrain_FlagValue0}, required-interface=TI_MVC_PowerTrain_State_Dummy
      rp_PwmWithTime: required-interface=TI_PwmWithTime
      rp_PwmWithTimeExp: required-interface=TI_PwmWithTimeExp
      rp_SetNVM_IlluminationData: required-interface=if_CS_MemAbsSet
      rp_StopPwmUpdate: nonqueued-receiver-com-spec{data-element=channel_id, init-value=constant-reference=Mdl_Dimchannel_idValue0}, required-interface=TI_StopPwmUpdate
      rp_TFTDisplayOn: nonqueued-receiver-com-spec{data-element=TFTDisplayOn, init-value=constant-reference=Mdl_DimTFTDisplayOnValue0}, required-interface=TI_TFTDisplayOn
      rp_UpdatePwmDirect: required-interface=TI_PwmDirect
      rp_Variant_Status: required-interface=TI_Variant_Status
      rp_custom_reset: required-interface=TI_SR_UserID_Data
        required-com-specs:
          data-element=CurrentUserID, init-value=constant-reference=Mdl_DimCurrentUserIDValue0
          data-element=CustomizeReset, init-value=constant-reference=Mdl_DimCustomizeResetValue0
          data-element=SettingResetResult, init-value=constant-reference=Mdl_DimSettingResetResultValue0
    behavior IB_Mdl_Dim
      operation invoked event OIE_pp_Init_Mdl_Dim_InitTrigByInit: start-on-event=Mdl_Dim_Init, operation=pp_Init.Init
      timing event TEMdl_Dim_Task: start-on-event=Mdl_Dim_Task, period=0.01
      port-api-options:
        enable-take-address=false, indirect-api=false, port=pp_IllumCtrl_Ip
        enable-take-address=false, indirect-api=false, port=pp_Illum_Transstep
        enable-take-address=false, indirect-api=false, port=pp_IlluminationDuty
        enable-take-address=false, indirect-api=false, port=Mdl_Dim/pp_IlumDayNightRequired
        enable-take-address=false, indirect-api=false, port=Mdl_Dim/pp_IlumDayNightStatus
        enable-take-address=false, indirect-api=false, port=pp_IlumStep
        enable-take-address=false, indirect-api=false, port=Mdl_Dim/pp_Init
        enable-take-address=false, indirect-api=false, port=pp_RGBStep
        enable-take-address=false, indirect-api=false, port=pp_RHDW_Dbc
        enable-take-address=false, indirect-api=false, port=pp_RHUP_Dbc
        enable-take-address=false, indirect-api=false, port=pp_RheoSwRaw_Status
        enable-take-address=false, indirect-api=false, port=pp_RheoSwStatus
        enable-take-address=false, indirect-api=false, port=pp_RheostatDayStep
        enable-take-address=false, indirect-api=false, port=pp_RheostatNightStep
        enable-take-address=false, indirect-api=false, port=pp_RheostatONSStatus
        enable-take-address=false, indirect-api=false, port=pp_RheostatSwType
        enable-take-address=false, indirect-api=false, port=pp_illumRheostatOnSTimer
        enable-take-address=false, indirect-api=false, port=pp_illumStarterstatus
        enable-take-address=false, indirect-api=false, port=pp_illum_rheostat_change
        enable-take-address=false, indirect-api=false, port=Mdl_Dim/rpEtmSts
        enable-take-address=false, indirect-api=false, port=rpEtmTTSts
        enable-take-address=false, indirect-api=false, port=Mdl_Dim/rpIgnSubstate
        enable-take-address=false, indirect-api=false, port=Mdl_Dim/rpIllum_Etm
        enable-take-address=false, indirect-api=false, port=Mdl_Dim/rpIoHwAb_Din
        enable-take-address=false, indirect-api=false, port=rpUpdateDIMWarning
        enable-take-address=false, indirect-api=false, port=Mdl_Dim/rpVehicleAppMode
        enable-take-address=false, indirect-api=false, port=Mdl_Dim/rp_CS_CanRx
        enable-take-address=false, indirect-api=false, port=Mdl_Dim/rp_CS_MemAbsGet
        enable-take-address=false, indirect-api=false, port=Mdl_Dim/rp_CS_MemAbsSet
        enable-take-address=false, indirect-api=false, port=Mdl_Dim/rp_CS_RxCanMdl
        enable-take-address=false, indirect-api=false, port=Mdl_Dim/rp_ClusterMode
        enable-take-address=false, indirect-api=false, port=rp_Ctrl_Ready_to_Sleep
        enable-take-address=false, indirect-api=false, port=rp_Current_duty
        enable-take-address=false, indirect-api=false, port=rp_Dcm_stop_app
        enable-take-address=false, indirect-api=false, port=rp_Diag2F_Rheo
        enable-take-address=false, indirect-api=false, port=rp_EcoRunPresenceFlag
        enable-take-address=false, indirect-api=false, port=rp_GetNVM_IlluminationData
        enable-take-address=false, indirect-api=false, port=Mdl_Dim/rp_Get_Variant_Cfg
        enable-take-address=false, indirect-api=false, port=Mdl_Dim/rp_ILL_ReadyToSleep
        enable-take-address=false, indirect-api=false, port=rp_IlumDayNightRequired
        enable-take-address=false, indirect-api=false, port=Mdl_Dim/rp_IlumDayNightStatus
        enable-take-address=false, indirect-api=false, port=Mdl_Dim/rp_IoHwAb_ADC
        enable-take-address=false, indirect-api=false, port=Mdl_Dim/rp_PowerTrain_State
        enable-take-address=false, indirect-api=false, port=rp_PwmWithTime
        enable-take-address=false, indirect-api=false, port=rp_PwmWithTimeExp
        enable-take-address=false, indirect-api=false, port=rp_SetNVM_IlluminationData
        enable-take-address=false, indirect-api=false, port=rp_StopPwmUpdate
        enable-take-address=false, indirect-api=false, port=Mdl_Dim/rp_TFTDisplayOn
        enable-take-address=false, indirect-api=false, port=rp_UpdatePwmDirect
        enable-take-address=false, indirect-api=false, port=Mdl_Dim/rp_Variant_Status
        enable-take-address=false, indirect-api=false, port=rp_custom_reset
      runnable Mdl_Dim_Init: can-be-invoked-concurrently=true
      runnable Mdl_Dim_Task: can-be-invoked-concurrently=true
        data-receive-point-by-arguments:
          18 x access:
            DRA_rpEtmSts_Illum_Status: accessed-variable=rpEtmSts.Illum_Status
            DRA_rpEtmTTSts_IllumStatus: accessed-variable=rpEtmTTSts.IllumStatus
            DRA_rpIgnSubstate_IgnitionSubstate: accessed-variable=rpIgnSubstate.IgnitionSubstate
            DRA_rpIllum_Etm_IllumStatus: accessed-variable=rpIllum_Etm.IllumStatus
            DRA_rpVehicleAppMode_WSSCurrentVehicleState: accessed-variable=rpVehicleAppMode.WSSCurrentVehicleState
            DRA_rp_ClusterMode_WSSCurrentClusterMode: accessed-variable=rp_ClusterMode.WSSCurrentClusterMode
            DRA_rp_Ctrl_Ready_to_Sleep_Ready_to_Sleep: accessed-variable=rp_Ctrl_Ready_to_Sleep.Ready_to_Sleep
            DRA_rp_Dcm_stop_app_AppId: accessed-variable=rp_Dcm_stop_app.AppId
            DRA_rp_Diag2F_Rheo_Diag_RheoStat: accessed-variable=rp_Diag2F_Rheo.Diag_RheoStat
            DRA_rp_EcoRunPresenceFlag_EcoRunPresenceFlag: accessed-variable=rp_EcoRunPresenceFlag.EcoRunPresenceFlag
            DRA_rp_IlumDayNightRequired_IlumDayNightRequired: accessed-variable=rp_IlumDayNightRequired.IlumDayNightRequired
            DRA_rp_IlumDayNightStatus_Day_Night_Status: accessed-variable=rp_IlumDayNightStatus.Day_Night_Status
            DRA_rp_PowerTrain_State_PowerTrain_Flag: accessed-variable=rp_PowerTrain_State.PowerTrain_Flag
            DRA_rp_StopPwmUpdate_channel_id: accessed-variable=rp_StopPwmUpdate.channel_id
            DRA_rp_TFTDisplayOn_TFTDisplayOn: accessed-variable=rp_TFTDisplayOn.TFTDisplayOn
            DRA_rp_custom_reset_CurrentUserID: accessed-variable=rp_custom_reset.CurrentUserID
            DRA_rp_custom_reset_CustomizeReset: accessed-variable=rp_custom_reset.CustomizeReset
            DRA_rp_custom_reset_SettingResetResult: accessed-variable=rp_custom_reset.SettingResetResult
        data-send-points:
          18 x access:
            DWA_pp_IllumCtrl_Ip_IllumCtrl_Ip_Data: accessed-variable=pp_IllumCtrl_Ip.IllumCtrl_Ip_Data
            DWA_pp_Illum_Transstep_Trans_Stepvlaue: accessed-variable=pp_Illum_Transstep.Trans_Stepvlaue
            DWA_pp_IlluminationDuty_DutyValue: accessed-variable=pp_IlluminationDuty.DutyValue
            DWA_pp_IlumDayNightRequired_ilumDNRequired: accessed-variable=pp_IlumDayNightRequired.ilumDNRequired
            DWA_pp_IlumDayNightStatus_illumDNStatus: accessed-variable=pp_IlumDayNightStatus.illumDNStatus
            DWA_pp_IlumStep_IllumStepValue: accessed-variable=pp_IlumStep.IllumStepValue
            DWA_pp_RGBStep_RGBStepValue: accessed-variable=pp_RGBStep.RGBStepValue
            DWA_pp_RHDW_Dbc_RHDW_Dbc: accessed-variable=pp_RHDW_Dbc.RHDW_Dbc
            DWA_pp_RHUP_Dbc_RHUP_Dbc: accessed-variable=pp_RHUP_Dbc.RHUP_Dbc
            DWA_pp_RheoSwRaw_Status_RawdataStatus: accessed-variable=pp_RheoSwRaw_Status.RawdataStatus
            DWA_pp_RheoSwStatus_SwitchStatus: accessed-variable=pp_RheoSwStatus.SwitchStatus
            DWA_pp_RheostatDayStep_RheostatDayStep: accessed-variable=pp_RheostatDayStep.RheostatDayStep
            DWA_pp_RheostatNightStep_RheostatNightStep: accessed-variable=pp_RheostatNightStep.RheostatNightStep
            DWA_pp_RheostatONSStatus_RheostatONSStatus: accessed-variable=pp_RheostatONSStatus.RheostatONSStatus
            DWA_pp_RheostatSwType_RheostatSwType: accessed-variable=pp_RheostatSwType.RheostatSwType
            DWA_pp_illumRheostatOnSTimer_Rheostat_OnSTime: accessed-variable=pp_illumRheostatOnSTimer.Rheostat_OnSTime
            DWA_pp_illumStarterstatus_StarterStatus_Out: accessed-variable=pp_illumStarterstatus.StarterStatus_Out
            DWA_pp_illum_rheostat_change_RheoUpdateVal: accessed-variable=pp_illum_rheostat_change.RheoUpdateVal
        409 x sync call, all with timeout=0.0:
          OA_rpIoHwAb_Din_GetAsyncRawInput: operation=rpIoHwAb_Din.GetAsyncRawInput
          OA_rpIoHwAb_Din_GetProcessedInput: operation=rpIoHwAb_Din.GetProcessedInput
          OA_rpIoHwAb_Din_GetSyncRawInput: operation=rpIoHwAb_Din.GetSyncRawInput
          OA_rpIoHwAb_Din_GetInputGroup: operation=rpIoHwAb_Din.GetInputGroup
          OA_rpUpdateDIMWarning_UpdateWarningStatus: operation=rpUpdateDIMWarning.UpdateWarningStatus
          OA_rp_CS_CanRx_RxCan_GetSignalValueU8Arr: operation=rp_CS_CanRx.RxCan_GetSignalValueU8Arr
          OA_rp_CS_CanRx_RxCan_SetSignalInitValue: operation=rp_CS_CanRx.RxCan_SetSignalInitValue
          OA_rp_CS_CanRx_RxCan_SetSignalInitValueU8Arr: operation=rp_CS_CanRx.RxCan_SetSignalInitValueU8Arr
          OA_rp_CS_CanRx_RxCan_SignalInvalidProcessingControl: operation=rp_CS_CanRx.RxCan_SignalInvalidProcessingControl
          OA_rp_CS_CanRx_RxCan_SignalMissingProcessingControl: operation=rp_CS_CanRx.RxCan_SignalMissingProcessingControl
          OA_rp_CS_CanRx_RxCan_SignalNRProcessingControl: operation=rp_CS_CanRx.RxCan_SignalNRProcessingControl
          OA_rp_CS_CanRx_RxCan_SignalGetJustRcvdStatus: operation=rp_CS_CanRx.RxCan_SignalGetJustRcvdStatus
          OA_rp_CS_CanRx_RxCan_SignalClearJustRcvdStatus: operation=rp_CS_CanRx.RxCan_SignalClearJustRcvdStatus
          OA_rp_CS_CanRx_RxCan_GetSignalValue: operation=rp_CS_CanRx.RxCan_GetSignalValue
          OA_rp_CS_MemAbsGet_Get_BsShare_SwUpdReflash_Element: operation=rp_CS_MemAbsGet.Get_BsShare_SwUpdReflash_Element
          OA_rp_CS_MemAbsGet_Get_BsShare_SwUpdFotaMode_Element: operation=rp_CS_MemAbsGet.Get_BsShare_SwUpdFotaMode_Element
          OA_rp_CS_MemAbsGet_Get_BsShare_SwUpdFotaFinPrint_Element: operation=rp_CS_MemAbsGet.Get_BsShare_SwUpdFotaFinPrint_Element
          OA_rp_CS_MemAbsGet_Get_BsShare_SwUpdFotaStatus_Element: operation=rp_CS_MemAbsGet.Get_BsShare_SwUpdFotaStatus_Element
          OA_rp_CS_MemAbsGet_Get_BsShare_SwUpdFotadecrypt_Element: operation=rp_CS_MemAbsGet.Get_BsShare_SwUpdFotadecrypt_Element
          OA_rp_CS_MemAbsGet_Get_BsShare_EcuPartNumber_Element: operation=rp_CS_MemAbsGet.Get_BsShare_EcuPartNumber_Element
          OA_rp_CS_MemAbsGet_Get_BsShare_VisteonPartNumber: operation=rp_CS_MemAbsGet.Get_BsShare_VisteonPartNumber
          OA_rp_CS_MemAbsGet_Get_BsShare_VisteonPCBPartNumber: operation=rp_CS_MemAbsGet.Get_BsShare_VisteonPCBPartNumber
          OA_rp_CS_MemAbsGet_Get_BsShare_ProductSerialNumber: operation=rp_CS_MemAbsGet.Get_BsShare_ProductSerialNumber
          OA_rp_CS_MemAbsGet_Get_BsShare_PCBSerialNumber: operation=rp_CS_MemAbsGet.Get_BsShare_PCBSerialNumber
          OA_rp_CS_MemAbsGet_Get_BsShare_SMTManufacturingDate: operation=rp_CS_MemAbsGet.Get_BsShare_SMTManufacturingDate
          OA_rp_CS_MemAbsGet_Get_BsShare_AssemblyManufacturingDate: operation=rp_CS_MemAbsGet.Get_BsShare_AssemblyManufacturingDate
          OA_rp_CS_MemAbsGet_Get_BsShare_SMTPlantNumber: operation=rp_CS_MemAbsGet.Get_BsShare_SMTPlantNumber
          OA_rp_CS_MemAbsGet_Get_BsShare_AssemblyPlantNumber: operation=rp_CS_MemAbsGet.Get_BsShare_AssemblyPlantNumber
          OA_rp_CS_MemAbsGet_Get_BsShare_HWModification: operation=rp_CS_MemAbsGet.Get_BsShare_HWModification
          OA_rp_CS_MemAbsGet_Get_BsShare_VisMeet_Element: operation=rp_CS_MemAbsGet.Get_BsShare_VisMeet_Element
          OA_rp_CS_MemAbsGet_Get_BsShare_VisMeet_EOLEntry_Element: operation=rp_CS_MemAbsGet.Get_BsShare_VisMeet_EOLEntry_Element
          OA_rp_CS_MemAbsGet_Get_BsShare_VehicleConfig_Element: operation=rp_CS_MemAbsGet.Get_BsShare_VehicleConfig_Element
          OA_rp_CS_MemAbsGet_Get_BsConst_SpeedoGauge_Element: operation=rp_CS_MemAbsGet.Get_BsConst_SpeedoGauge_Element
          OA_rp_CS_MemAbsGet_Get_BsConst_TachoGauge_Element: operation=rp_CS_MemAbsGet.Get_BsConst_TachoGauge_Element
          OA_rp_CS_MemAbsGet_Get_BsConst_FuelGauge_Element: operation=rp_CS_MemAbsGet.Get_BsConst_FuelGauge_Element
          OA_rp_CS_MemAbsGet_Get_BsConst_TempGauge_Element: operation=rp_CS_MemAbsGet.Get_BsConst_TempGauge_Element
          OA_rp_CS_MemAbsGet_Get_BsConst_PowerGauge_Element: operation=rp_CS_MemAbsGet.Get_BsConst_PowerGauge_Element
          OA_rp_CS_MemAbsGet_Get_BsConst_OilGauge_Element: operation=rp_CS_MemAbsGet.Get_BsConst_OilGauge_Element
          OA_rp_CS_MemAbsGet_Get_BsConst_TripComputer_Element: operation=rp_CS_MemAbsGet.Get_BsConst_TripComputer_Element
          OA_rp_CS_MemAbsGet_Get_BsConst_Compensation_Line_Slope_m: operation=rp_CS_MemAbsGet.Get_BsConst_Compensation_Line_Slope_m
          OA_rp_CS_MemAbsGet_Get_BsConst_Compensation_Line_Shift_b: operation=rp_CS_MemAbsGet.Get_BsConst_Compensation_Line_Shift_b
          OA_rp_CS_MemAbsGet_Get_BsConst_Lookup_Curve_HotSpot_Coef_X: operation=rp_CS_MemAbsGet.Get_BsConst_Lookup_Curve_HotSpot_Coef_X
          OA_rp_CS_MemAbsGet_Get_BsConst_Lookup_Curve_HotSpot_Coef_Y: operation=rp_CS_MemAbsGet.Get_BsConst_Lookup_Curve_HotSpot_Coef_Y
          OA_rp_CS_MemAbsGet_Get_BsConst_Temp_Threshold_Hysteresis_Derating: operation=rp_CS_MemAbsGet.Get_BsConst_Temp_Threshold_Hysteresis_Derating
          OA_rp_CS_MemAbsGet_Get_BsConst_Derating_Backlight_Disable: operation=rp_CS_MemAbsGet.Get_BsConst_Derating_Backlight_Disable
          OA_rp_CS_MemAbsGet_Get_BsConst_Temperature_Sensor_Conv: operation=rp_CS_MemAbsGet.Get_BsConst_Temperature_Sensor_Conv
          OA_rp_CS_MemAbsGet_Get_BsConst_PCB_Temperature_Sensor_Conv: operation=rp_CS_MemAbsGet.Get_BsConst_PCB_Temperature_Sensor_Conv
          OA_rp_CS_MemAbsGet_Get_BsConst_Display_Illum_Max_Level: operation=rp_CS_MemAbsGet.Get_BsConst_Display_Illum_Max_Level
          OA_rp_CS_MemAbsGet_Get_BsConst_PWM_boost_bypass_duty: operation=rp_CS_MemAbsGet.Get_BsConst_PWM_boost_bypass_duty
          OA_rp_CS_MemAbsGet_Get_BsConst_BsConst_Illumination_ReservedByte: operation=rp_CS_MemAbsGet.Get_BsConst_BsConst_Illumination_ReservedByte
          OA_rp_CS_MemAbsGet_Get_BsConst_Compensation_Line_Slope_m_SafeCopy1: operation=rp_CS_MemAbsGet.Get_BsConst_Compensation_Line_Slope_m_SafeCopy1
          OA_rp_CS_MemAbsGet_Get_BsConst_Compensation_Line_Shift_b_SafeCopy1: operation=rp_CS_MemAbsGet.Get_BsConst_Compensation_Line_Shift_b_SafeCopy1
          OA_rp_CS_MemAbsGet_Get_BsConst_Lookup_Curve_HotSpot_Coef_X_SafeCopy1: operation=rp_CS_MemAbsGet.Get_BsConst_Lookup_Curve_HotSpot_Coef_X_SafeCopy1
          OA_rp_CS_MemAbsGet_Get_BsConst_Lookup_Curve_HotSpot_Coef_Y_SafeCopy1: operation=rp_CS_MemAbsGet.Get_BsConst_Lookup_Curve_HotSpot_Coef_Y_SafeCopy1
          OA_rp_CS_MemAbsGet_Get_BsConst_Temp_Threshold_Hysteresis_Derating_SafeCopy1: operation=rp_CS_MemAbsGet.Get_BsConst_Temp_Threshold_Hysteresis_Derating_SafeCopy1
          OA_rp_CS_MemAbsGet_Get_BsConst_Derating_Backlight_Disable_SafeCopy1: operation=rp_CS_MemAbsGet.Get_BsConst_Derating_Backlight_Disable_SafeCopy1
          OA_rp_CS_MemAbsGet_Get_BsConst_Temperature_Sensor_Conv_SafeCopy1: operation=rp_CS_MemAbsGet.Get_BsConst_Temperature_Sensor_Conv_SafeCopy1
          OA_rp_CS_MemAbsGet_Get_BsConst_PCB_Temperature_Sensor_Conv_SafeCopy1: operation=rp_CS_MemAbsGet.Get_BsConst_PCB_Temperature_Sensor_Conv_SafeCopy1
          OA_rp_CS_MemAbsGet_Get_BsConst_Display_Illum_Max_Level_SafeCopy1: operation=rp_CS_MemAbsGet.Get_BsConst_Display_Illum_Max_Level_SafeCopy1
          OA_rp_CS_MemAbsGet_Get_BsConst_PWM_boost_bypass_duty_SafeCopy1: operation=rp_CS_MemAbsGet.Get_BsConst_PWM_boost_bypass_duty_SafeCopy1
          OA_rp_CS_MemAbsGet_Get_BsConst_BsConst_Illumination_ReservedByte_SafeCopy1: operation=rp_CS_MemAbsGet.Get_BsConst_BsConst_Illumination_ReservedByte_SafeCopy1
          OA_rp_CS_MemAbsGet_Get_BsConst_Compensation_Line_Slope_m_SafeCopy2: operation=rp_CS_MemAbsGet.Get_BsConst_Compensation_Line_Slope_m_SafeCopy2
          OA_rp_CS_MemAbsGet_Get_BsConst_Compensation_Line_Shift_b_SafeCopy2: operation=rp_CS_MemAbsGet.Get_BsConst_Compensation_Line_Shift_b_SafeCopy2
          OA_rp_CS_MemAbsGet_Get_BsConst_Lookup_Curve_HotSpot_Coef_X_SafeCopy2: operation=rp_CS_MemAbsGet.Get_BsConst_Lookup_Curve_HotSpot_Coef_X_SafeCopy2
          OA_rp_CS_MemAbsGet_Get_BsConst_Lookup_Curve_HotSpot_Coef_Y_SafeCopy2: operation=rp_CS_MemAbsGet.Get_BsConst_Lookup_Curve_HotSpot_Coef_Y_SafeCopy2
          OA_rp_CS_MemAbsGet_Get_BsConst_Temp_Threshold_Hysteresis_Derating_SafeCopy2: operation=rp_CS_MemAbsGet.Get_BsConst_Temp_Threshold_Hysteresis_Derating_SafeCopy2
          OA_rp_CS_MemAbsGet_Get_BsConst_Derating_Backlight_Disable_SafeCopy2: operation=rp_CS_MemAbsGet.Get_BsConst_Derating_Backlight_Disable_SafeCopy2
          OA_rp_CS_MemAbsGet_Get_BsConst_Temperature_Sensor_Conv_SafeCopy2: operation=rp_CS_MemAbsGet.Get_BsConst_Temperature_Sensor_Conv_SafeCopy2
          OA_rp_CS_MemAbsGet_Get_BsConst_PCB_Temperature_Sensor_Conv_SafeCopy2: operation=rp_CS_MemAbsGet.Get_BsConst_PCB_Temperature_Sensor_Conv_SafeCopy2
          OA_rp_CS_MemAbsGet_Get_BsConst_Display_Illum_Max_Level_SafeCopy2: operation=rp_CS_MemAbsGet.Get_BsConst_Display_Illum_Max_Level_SafeCopy2
          OA_rp_CS_MemAbsGet_Get_BsConst_PWM_boost_bypass_duty_SafeCopy2: operation=rp_CS_MemAbsGet.Get_BsConst_PWM_boost_bypass_duty_SafeCopy2
          OA_rp_CS_MemAbsGet_Get_BsConst_BsConst_Illumination_ReservedByte_SafeCopy2: operation=rp_CS_MemAbsGet.Get_BsConst_BsConst_Illumination_ReservedByte_SafeCopy2
          OA_rp_CS_MemAbsGet_Get_BsConst_Audio_Element: operation=rp_CS_MemAbsGet.Get_BsConst_Audio_Element
          OA_rp_CS_MemAbsGet_Get_BsConst_Warning_Element: operation=rp_CS_MemAbsGet.Get_BsConst_Warning_Element
          OA_rp_CS_MemAbsGet_Get_BsConst_RealTimeClock_Element: operation=rp_CS_MemAbsGet.Get_BsConst_RealTimeClock_Element
          OA_rp_CS_MemAbsGet_Get_BsConst_Communication_Element: operation=rp_CS_MemAbsGet.Get_BsConst_Communication_Element
          OA_rp_CS_MemAbsGet_Get_BsConst_Power_Element: operation=rp_CS_MemAbsGet.Get_BsConst_Power_Element
          OA_rp_CS_MemAbsGet_Get_BsConst_ServiceReminder_Element: operation=rp_CS_MemAbsGet.Get_BsConst_ServiceReminder_Element
          OA_rp_CS_MemAbsGet_Get_BsConst_EngOffTimer_Element: operation=rp_CS_MemAbsGet.Get_BsConst_EngOffTimer_Element
          OA_rp_CS_MemAbsGet_Get_BsCys_Certicificate_Element: operation=rp_CS_MemAbsGet.Get_BsCys_Certicificate_Element
          OA_rp_CS_MemAbsGet_Get_RefCys_Certicificate_Element: operation=rp_CS_MemAbsGet.Get_RefCys_Certicificate_Element
          OA_rp_CS_MemAbsGet_Get_RefCys_Certicificate1_Element: operation=rp_CS_MemAbsGet.Get_RefCys_Certicificate1_Element
          OA_rp_CS_MemAbsGet_Get_BsRt_Odometer_Element: operation=rp_CS_MemAbsGet.Get_BsRt_Odometer_Element
          OA_rp_CS_MemAbsGet_Get_BsRt_SpeedoGauge_Element: operation=rp_CS_MemAbsGet.Get_BsRt_SpeedoGauge_Element
          OA_rp_CS_MemAbsGet_Get_BsRt_TachoGauge_Element: operation=rp_CS_MemAbsGet.Get_BsRt_TachoGauge_Element
          OA_rp_CS_MemAbsGet_Get_BsRt_FuelGauge_Element: operation=rp_CS_MemAbsGet.Get_BsRt_FuelGauge_Element
          OA_rp_CS_MemAbsGet_Get_BsRt_TempGauge_Element: operation=rp_CS_MemAbsGet.Get_BsRt_TempGauge_Element
          OA_rp_CS_MemAbsGet_Get_BsRt_PowerGauge_Element: operation=rp_CS_MemAbsGet.Get_BsRt_PowerGauge_Element
          OA_rp_CS_MemAbsGet_Get_BsRt_OilGauge_Element: operation=rp_CS_MemAbsGet.Get_BsRt_OilGauge_Element
          OA_rp_CS_MemAbsGet_Get_BsRt_TripComputer_Element: operation=rp_CS_MemAbsGet.Get_BsRt_TripComputer_Element
          OA_rp_CS_MemAbsGet_Get_BsRt_Warning_Element: operation=rp_CS_MemAbsGet.Get_BsRt_Warning_Element
          OA_rp_CS_MemAbsGet_Get_BsRt_RealTimeClock_Element: operation=rp_CS_MemAbsGet.Get_BsRt_RealTimeClock_Element
          OA_rp_CS_MemAbsGet_Get_BsRt_Personalization_Element: operation=rp_CS_MemAbsGet.Get_BsRt_Personalization_Element
          OA_rp_CS_MemAbsGet_Get_BsRt_Illumination_Element: operation=rp_CS_MemAbsGet.Get_BsRt_Illumination_Element
          OA_rp_CS_MemAbsGet_Get_BsRt_CusDlt_Element: operation=rp_CS_MemAbsGet.Get_BsRt_CusDlt_Element
          OA_rp_CS_MemAbsGet_Get_BsReten_Odometer_Element: operation=rp_CS_MemAbsGet.Get_BsReten_Odometer_Element
          OA_rp_CS_MemAbsGet_Get_BsReten_Gauges_Element: operation=rp_CS_MemAbsGet.Get_BsReten_Gauges_Element
          OA_rp_CS_MemAbsGet_Get_BsReten_Tripcomputer_Element: operation=rp_CS_MemAbsGet.Get_BsReten_Tripcomputer_Element
          OA_rp_CS_MemAbsGet_Get_BsReten_Illumination_Element: operation=rp_CS_MemAbsGet.Get_BsReten_Illumination_Element
          OA_rp_CS_MemAbsGet_Get_BsReten_Audio_Element: operation=rp_CS_MemAbsGet.Get_BsReten_Audio_Element
          OA_rp_CS_MemAbsGet_Get_BsReten_Warning_Element: operation=rp_CS_MemAbsGet.Get_BsReten_Warning_Element
          OA_rp_CS_MemAbsGet_Get_BsReten_RealTimeClock_Element: operation=rp_CS_MemAbsGet.Get_BsReten_RealTimeClock_Element
          OA_rp_CS_MemAbsGet_Get_BsReten_Communication_Element: operation=rp_CS_MemAbsGet.Get_BsReten_Communication_Element
          OA_rp_CS_MemAbsGet_Get_BsReten_Personalization_Element: operation=rp_CS_MemAbsGet.Get_BsReten_Personalization_Element
          OA_rp_CS_MemAbsGet_Get_BsReten_Power_Element: operation=rp_CS_MemAbsGet.Get_BsReten_Power_Element
          OA_rp_CS_MemAbsGet_Get_BsReten_Display_Element: operation=rp_CS_MemAbsGet.Get_BsReten_Display_Element
          OA_rp_CS_MemAbsGet_Get_BsDiag_ErrorRecord_Element: operation=rp_CS_MemAbsGet.Get_BsDiag_ErrorRecord_Element
          OA_rp_CS_MemAbsGet_Get_BsDiag_Dtc_Element: operation=rp_CS_MemAbsGet.Get_BsDiag_Dtc_Element
          OA_rp_CS_MemAbsSet_Set_BsShare_SwUpdReflash_Element: operation=rp_CS_MemAbsSet.Set_BsShare_SwUpdReflash_Element
          OA_rp_CS_MemAbsSet_Set_BsShare_SwUpdFotaMode_Element: operation=rp_CS_MemAbsSet.Set_BsShare_SwUpdFotaMode_Element
          OA_rp_CS_MemAbsSet_Set_BsShare_SwUpdFotaFinPrint_Element: operation=rp_CS_MemAbsSet.Set_BsShare_SwUpdFotaFinPrint_Element
          OA_rp_CS_MemAbsSet_Set_BsShare_SwUpdFotaStatus_Element: operation=rp_CS_MemAbsSet.Set_BsShare_SwUpdFotaStatus_Element
          OA_rp_CS_MemAbsSet_Set_BsShare_SwUpdFotadecrypt_Element: operation=rp_CS_MemAbsSet.Set_BsShare_SwUpdFotadecrypt_Element
          OA_rp_CS_MemAbsSet_Set_BsShare_EcuPartNumber_Element: operation=rp_CS_MemAbsSet.Set_BsShare_EcuPartNumber_Element
          OA_rp_CS_MemAbsSet_Set_BsShare_VisteonPartNumber: operation=rp_CS_MemAbsSet.Set_BsShare_VisteonPartNumber
          OA_rp_CS_MemAbsSet_Set_BsShare_VisteonPCBPartNumber: operation=rp_CS_MemAbsSet.Set_BsShare_VisteonPCBPartNumber
          OA_rp_CS_MemAbsSet_Set_BsShare_ProductSerialNumber: operation=rp_CS_MemAbsSet.Set_BsShare_ProductSerialNumber
          OA_rp_CS_MemAbsSet_Set_BsShare_PCBSerialNumber: operation=rp_CS_MemAbsSet.Set_BsShare_PCBSerialNumber
          OA_rp_CS_MemAbsSet_Set_BsShare_SMTManufacturingDate: operation=rp_CS_MemAbsSet.Set_BsShare_SMTManufacturingDate
          OA_rp_CS_MemAbsSet_Set_BsShare_AssemblyManufacturingDate: operation=rp_CS_MemAbsSet.Set_BsShare_AssemblyManufacturingDate
          OA_rp_CS_MemAbsSet_Set_BsShare_SMTPlantNumber: operation=rp_CS_MemAbsSet.Set_BsShare_SMTPlantNumber
          OA_rp_CS_MemAbsSet_Set_BsShare_AssemblyPlantNumber: operation=rp_CS_MemAbsSet.Set_BsShare_AssemblyPlantNumber
          OA_rp_CS_MemAbsSet_Set_BsShare_HWModification: operation=rp_CS_MemAbsSet.Set_BsShare_HWModification
          OA_rp_CS_MemAbsSet_Set_BsShare_VisMeet_Element: operation=rp_CS_MemAbsSet.Set_BsShare_VisMeet_Element
          OA_rp_CS_MemAbsSet_Set_BsShare_VisMeet_EOLEntry_Element: operation=rp_CS_MemAbsSet.Set_BsShare_VisMeet_EOLEntry_Element
          OA_rp_CS_MemAbsSet_Set_BsShare_VehicleConfig_Element: operation=rp_CS_MemAbsSet.Set_BsShare_VehicleConfig_Element
          OA_rp_CS_MemAbsSet_Set_BsConst_SpeedoGauge_Element: operation=rp_CS_MemAbsSet.Set_BsConst_SpeedoGauge_Element
          OA_rp_CS_MemAbsSet_Set_BsConst_TachoGauge_Element: operation=rp_CS_MemAbsSet.Set_BsConst_TachoGauge_Element
          OA_rp_CS_MemAbsSet_Set_BsConst_FuelGauge_Element: operation=rp_CS_MemAbsSet.Set_BsConst_FuelGauge_Element
          OA_rp_CS_MemAbsSet_Set_BsConst_TempGauge_Element: operation=rp_CS_MemAbsSet.Set_BsConst_TempGauge_Element
          OA_rp_CS_MemAbsSet_Set_BsConst_PowerGauge_Element: operation=rp_CS_MemAbsSet.Set_BsConst_PowerGauge_Element
          OA_rp_CS_MemAbsSet_Set_BsConst_OilGauge_Element: operation=rp_CS_MemAbsSet.Set_BsConst_OilGauge_Element
          OA_rp_CS_MemAbsSet_Set_BsConst_TripComputer_Element: operation=rp_CS_MemAbsSet.Set_BsConst_TripComputer_Element
          OA_rp_CS_MemAbsSet_Set_BsConst_Compensation_Line_Slope_m: operation=rp_CS_MemAbsSet.Set_BsConst_Compensation_Line_Slope_m
          OA_rp_CS_MemAbsSet_Set_BsConst_Compensation_Line_Shift_b: operation=rp_CS_MemAbsSet.Set_BsConst_Compensation_Line_Shift_b
          OA_rp_CS_MemAbsSet_Set_BsConst_Lookup_Curve_HotSpot_Coef_X: operation=rp_CS_MemAbsSet.Set_BsConst_Lookup_Curve_HotSpot_Coef_X
          OA_rp_CS_MemAbsSet_Set_BsConst_Lookup_Curve_HotSpot_Coef_Y: operation=rp_CS_MemAbsSet.Set_BsConst_Lookup_Curve_HotSpot_Coef_Y
          OA_rp_CS_MemAbsSet_Set_BsConst_Temp_Threshold_Hysteresis_Derating: operation=rp_CS_MemAbsSet.Set_BsConst_Temp_Threshold_Hysteresis_Derating
          OA_rp_CS_MemAbsSet_Set_BsConst_Derating_Backlight_Disable: operation=rp_CS_MemAbsSet.Set_BsConst_Derating_Backlight_Disable
          OA_rp_CS_MemAbsSet_Set_BsConst_Temperature_Sensor_Conv: operation=rp_CS_MemAbsSet.Set_BsConst_Temperature_Sensor_Conv
          OA_rp_CS_MemAbsSet_Set_BsConst_PCB_Temperature_Sensor_Conv: operation=rp_CS_MemAbsSet.Set_BsConst_PCB_Temperature_Sensor_Conv
          OA_rp_CS_MemAbsSet_Set_BsConst_Display_Illum_Max_Level: operation=rp_CS_MemAbsSet.Set_BsConst_Display_Illum_Max_Level
          OA_rp_CS_MemAbsSet_Set_BsConst_PWM_boost_bypass_duty: operation=rp_CS_MemAbsSet.Set_BsConst_PWM_boost_bypass_duty
          OA_rp_CS_MemAbsSet_Set_BsConst_BsConst_Illumination_ReservedByte: operation=rp_CS_MemAbsSet.Set_BsConst_BsConst_Illumination_ReservedByte
          OA_rp_CS_MemAbsSet_Set_BsConst_Compensation_Line_Slope_m_SafeCopy1: operation=rp_CS_MemAbsSet.Set_BsConst_Compensation_Line_Slope_m_SafeCopy1
          OA_rp_CS_MemAbsSet_Set_BsConst_Compensation_Line_Shift_b_SafeCopy1: operation=rp_CS_MemAbsSet.Set_BsConst_Compensation_Line_Shift_b_SafeCopy1
          OA_rp_CS_MemAbsSet_Set_BsConst_Lookup_Curve_HotSpot_Coef_X_SafeCopy1: operation=rp_CS_MemAbsSet.Set_BsConst_Lookup_Curve_HotSpot_Coef_X_SafeCopy1
          OA_rp_CS_MemAbsSet_Set_BsConst_Lookup_Curve_HotSpot_Coef_Y_SafeCopy1: operation=rp_CS_MemAbsSet.Set_BsConst_Lookup_Curve_HotSpot_Coef_Y_SafeCopy1
          OA_rp_CS_MemAbsSet_Set_BsConst_Temp_Threshold_Hysteresis_Derating_SafeCopy1: operation=rp_CS_MemAbsSet.Set_BsConst_Temp_Threshold_Hysteresis_Derating_SafeCopy1
          OA_rp_CS_MemAbsSet_Set_BsConst_Derating_Backlight_Disable_SafeCopy1: operation=rp_CS_MemAbsSet.Set_BsConst_Derating_Backlight_Disable_SafeCopy1
          OA_rp_CS_MemAbsSet_Set_BsConst_Temperature_Sensor_Conv_SafeCopy1: operation=rp_CS_MemAbsSet.Set_BsConst_Temperature_Sensor_Conv_SafeCopy1
          OA_rp_CS_MemAbsSet_Set_BsConst_PCB_Temperature_Sensor_Conv_SafeCopy1: operation=rp_CS_MemAbsSet.Set_BsConst_PCB_Temperature_Sensor_Conv_SafeCopy1
          OA_rp_CS_MemAbsSet_Set_BsConst_Display_Illum_Max_Level_SafeCopy1: operation=rp_CS_MemAbsSet.Set_BsConst_Display_Illum_Max_Level_SafeCopy1
          OA_rp_CS_MemAbsSet_Set_BsConst_PWM_boost_bypass_duty_SafeCopy1: operation=rp_CS_MemAbsSet.Set_BsConst_PWM_boost_bypass_duty_SafeCopy1
          OA_rp_CS_MemAbsSet_Set_BsConst_BsConst_Illumination_ReservedByte_SafeCopy1: operation=rp_CS_MemAbsSet.Set_BsConst_BsConst_Illumination_ReservedByte_SafeCopy1
          OA_rp_CS_MemAbsSet_Set_BsConst_Compensation_Line_Slope_m_SafeCopy2: operation=rp_CS_MemAbsSet.Set_BsConst_Compensation_Line_Slope_m_SafeCopy2
          OA_rp_CS_MemAbsSet_Set_BsConst_Compensation_Line_Shift_b_SafeCopy2: operation=rp_CS_MemAbsSet.Set_BsConst_Compensation_Line_Shift_b_SafeCopy2
          OA_rp_CS_MemAbsSet_Set_BsConst_Lookup_Curve_HotSpot_Coef_X_SafeCopy2: operation=rp_CS_MemAbsSet.Set_BsConst_Lookup_Curve_HotSpot_Coef_X_SafeCopy2
          OA_rp_CS_MemAbsSet_Set_BsConst_Lookup_Curve_HotSpot_Coef_Y_SafeCopy2: operation=rp_CS_MemAbsSet.Set_BsConst_Lookup_Curve_HotSpot_Coef_Y_SafeCopy2
          OA_rp_CS_MemAbsSet_Set_BsConst_Temp_Threshold_Hysteresis_Derating_SafeCopy2: operation=rp_CS_MemAbsSet.Set_BsConst_Temp_Threshold_Hysteresis_Derating_SafeCopy2
          OA_rp_CS_MemAbsSet_Set_BsConst_Derating_Backlight_Disable_SafeCopy2: operation=rp_CS_MemAbsSet.Set_BsConst_Derating_Backlight_Disable_SafeCopy2
          OA_rp_CS_MemAbsSet_Set_BsConst_Temperature_Sensor_Conv_SafeCopy2: operation=rp_CS_MemAbsSet.Set_BsConst_Temperature_Sensor_Conv_SafeCopy2
          OA_rp_CS_MemAbsSet_Set_BsConst_PCB_Temperature_Sensor_Conv_SafeCopy2: operation=rp_CS_MemAbsSet.Set_BsConst_PCB_Temperature_Sensor_Conv_SafeCopy2
          OA_rp_CS_MemAbsSet_Set_BsConst_Display_Illum_Max_Level_SafeCopy2: operation=rp_CS_MemAbsSet.Set_BsConst_Display_Illum_Max_Level_SafeCopy2
          OA_rp_CS_MemAbsSet_Set_BsConst_PWM_boost_bypass_duty_SafeCopy2: operation=rp_CS_MemAbsSet.Set_BsConst_PWM_boost_bypass_duty_SafeCopy2
          OA_rp_CS_MemAbsSet_Set_BsConst_BsConst_Illumination_ReservedByte_SafeCopy2: operation=rp_CS_MemAbsSet.Set_BsConst_BsConst_Illumination_ReservedByte_SafeCopy2
          OA_rp_CS_MemAbsSet_Set_BsConst_Audio_Element: operation=rp_CS_MemAbsSet.Set_BsConst_Audio_Element
          OA_rp_CS_MemAbsSet_Set_BsConst_Warning_Element: operation=rp_CS_MemAbsSet.Set_BsConst_Warning_Element
          OA_rp_CS_MemAbsSet_Set_BsConst_RealTimeClock_Element: operation=rp_CS_MemAbsSet.Set_BsConst_RealTimeClock_Element
          OA_rp_CS_MemAbsSet_Set_BsConst_Communication_Element: operation=rp_CS_MemAbsSet.Set_BsConst_Communication_Element
          OA_rp_CS_MemAbsSet_Set_BsConst_Power_Element: operation=rp_CS_MemAbsSet.Set_BsConst_Power_Element
          OA_rp_CS_MemAbsSet_Set_BsConst_ServiceReminder_Element: operation=rp_CS_MemAbsSet.Set_BsConst_ServiceReminder_Element
          OA_rp_CS_MemAbsSet_Set_BsConst_EngOffTimer_Element: operation=rp_CS_MemAbsSet.Set_BsConst_EngOffTimer_Element
          OA_rp_CS_MemAbsSet_Set_BsCys_Certicificate_Element: operation=rp_CS_MemAbsSet.Set_BsCys_Certicificate_Element
          OA_rp_CS_MemAbsSet_Set_RefCys_Certicificate_Element: operation=rp_CS_MemAbsSet.Set_RefCys_Certicificate_Element
          OA_rp_CS_MemAbsSet_Set_RefCys_Certicificate1_Element: operation=rp_CS_MemAbsSet.Set_RefCys_Certicificate1_Element
          OA_rp_CS_MemAbsSet_Set_BsRt_Odometer_Element: operation=rp_CS_MemAbsSet.Set_BsRt_Odometer_Element
          OA_rp_CS_MemAbsSet_Set_BsRt_SpeedoGauge_Element: operation=rp_CS_MemAbsSet.Set_BsRt_SpeedoGauge_Element
          OA_rp_CS_MemAbsSet_Set_BsRt_TachoGauge_Element: operation=rp_CS_MemAbsSet.Set_BsRt_TachoGauge_Element
          OA_rp_CS_MemAbsSet_Set_BsRt_FuelGauge_Element: operation=rp_CS_MemAbsSet.Set_BsRt_FuelGauge_Element
          OA_rp_CS_MemAbsSet_Set_BsRt_TempGauge_Element: operation=rp_CS_MemAbsSet.Set_BsRt_TempGauge_Element
          OA_rp_CS_MemAbsSet_Set_BsRt_PowerGauge_Element: operation=rp_CS_MemAbsSet.Set_BsRt_PowerGauge_Element
          OA_rp_CS_MemAbsSet_Set_BsRt_OilGauge_Element: operation=rp_CS_MemAbsSet.Set_BsRt_OilGauge_Element
          OA_rp_CS_MemAbsSet_Set_BsRt_TripComputer_Element: operation=rp_CS_MemAbsSet.Set_BsRt_TripComputer_Element
          OA_rp_CS_MemAbsSet_Set_BsRt_Warning_Element: operation=rp_CS_MemAbsSet.Set_BsRt_Warning_Element
          OA_rp_CS_MemAbsSet_Set_BsRt_RealTimeClock_Element: operation=rp_CS_MemAbsSet.Set_BsRt_RealTimeClock_Element
          OA_rp_CS_MemAbsSet_Set_BsRt_Personalization_Element: operation=rp_CS_MemAbsSet.Set_BsRt_Personalization_Element
          OA_rp_CS_MemAbsSet_Set_BsRt_Illumination_Element: operation=rp_CS_MemAbsSet.Set_BsRt_Illumination_Element
          OA_rp_CS_MemAbsSet_Set_BsRt_CusDlt_Element: operation=rp_CS_MemAbsSet.Set_BsRt_CusDlt_Element
          OA_rp_CS_MemAbsSet_Set_BsReten_Odometer_Element: operation=rp_CS_MemAbsSet.Set_BsReten_Odometer_Element
          OA_rp_CS_MemAbsSet_Set_BsReten_Gauges_Element: operation=rp_CS_MemAbsSet.Set_BsReten_Gauges_Element
          OA_rp_CS_MemAbsSet_Set_BsReten_Tripcomputer_Element: operation=rp_CS_MemAbsSet.Set_BsReten_Tripcomputer_Element
          OA_rp_CS_MemAbsSet_Set_BsReten_Illumination_Element: operation=rp_CS_MemAbsSet.Set_BsReten_Illumination_Element
          OA_rp_CS_MemAbsSet_Set_BsReten_Audio_Element: operation=rp_CS_MemAbsSet.Set_BsReten_Audio_Element
          OA_rp_CS_MemAbsSet_Set_BsReten_Warning_Element: operation=rp_CS_MemAbsSet.Set_BsReten_Warning_Element
          OA_rp_CS_MemAbsSet_Set_BsReten_RealTimeClock_Element: operation=rp_CS_MemAbsSet.Set_BsReten_RealTimeClock_Element
          OA_rp_CS_MemAbsSet_Set_BsReten_Communication_Element: operation=rp_CS_MemAbsSet.Set_BsReten_Communication_Element
          OA_rp_CS_MemAbsSet_Set_BsReten_Personalization_Element: operation=rp_CS_MemAbsSet.Set_BsReten_Personalization_Element
          OA_rp_CS_MemAbsSet_Set_BsReten_Power_Element: operation=rp_CS_MemAbsSet.Set_BsReten_Power_Element
          OA_rp_CS_MemAbsSet_Set_BsReten_Display_Element: operation=rp_CS_MemAbsSet.Set_BsReten_Display_Element
          OA_rp_CS_MemAbsSet_Set_BsDiag_ErrorRecord_Element: operation=rp_CS_MemAbsSet.Set_BsDiag_ErrorRecord_Element
          OA_rp_CS_MemAbsSet_Set_BsDiag_Dtc_Element: operation=rp_CS_MemAbsSet.Set_BsDiag_Dtc_Element
          OA_rp_CS_RxCanMdl_RxCan_GetSignalValueU8Arr: operation=rp_CS_RxCanMdl.RxCan_GetSignalValueU8Arr
          OA_rp_CS_RxCanMdl_RxCan_SetSignalInitValue: operation=rp_CS_RxCanMdl.RxCan_SetSignalInitValue
          OA_rp_CS_RxCanMdl_RxCan_SetSignalInitValueU8Arr: operation=rp_CS_RxCanMdl.RxCan_SetSignalInitValueU8Arr
          OA_rp_CS_RxCanMdl_RxCan_SignalInvalidProcessingControl: operation=rp_CS_RxCanMdl.RxCan_SignalInvalidProcessingControl
          OA_rp_CS_RxCanMdl_RxCan_SignalMissingProcessingControl: operation=rp_CS_RxCanMdl.RxCan_SignalMissingProcessingControl
          OA_rp_CS_RxCanMdl_RxCan_SignalNRProcessingControl: operation=rp_CS_RxCanMdl.RxCan_SignalNRProcessingControl
          OA_rp_CS_RxCanMdl_RxCan_SignalGetJustRcvdStatus: operation=rp_CS_RxCanMdl.RxCan_SignalGetJustRcvdStatus
          OA_rp_CS_RxCanMdl_RxCan_SignalClearJustRcvdStatus: operation=rp_CS_RxCanMdl.RxCan_SignalClearJustRcvdStatus
          OA_rp_CS_RxCanMdl_RxCan_GetSignalValue: operation=rp_CS_RxCanMdl.RxCan_GetSignalValue
          OA_rp_Current_duty_GetPwmCurrentDuty: operation=rp_Current_duty.GetPwmCurrentDuty
          OA_rp_GetNVM_IlluminationData_Get_BsShare_SwUpdReflash_Element: operation=rp_GetNVM_IlluminationData.Get_BsShare_SwUpdReflash_Element
          OA_rp_GetNVM_IlluminationData_Get_BsShare_SwUpdFotaMode_Element: operation=rp_GetNVM_IlluminationData.Get_BsShare_SwUpdFotaMode_Element
          OA_rp_GetNVM_IlluminationData_Get_BsShare_SwUpdFotaFinPrint_Element: operation=rp_GetNVM_IlluminationData.Get_BsShare_SwUpdFotaFinPrint_Element
          OA_rp_GetNVM_IlluminationData_Get_BsShare_SwUpdFotaStatus_Element: operation=rp_GetNVM_IlluminationData.Get_BsShare_SwUpdFotaStatus_Element
          OA_rp_GetNVM_IlluminationData_Get_BsShare_SwUpdFotadecrypt_Element: operation=rp_GetNVM_IlluminationData.Get_BsShare_SwUpdFotadecrypt_Element
          OA_rp_GetNVM_IlluminationData_Get_BsShare_EcuPartNumber_Element: operation=rp_GetNVM_IlluminationData.Get_BsShare_EcuPartNumber_Element
          OA_rp_GetNVM_IlluminationData_Get_BsShare_VisteonPartNumber: operation=rp_GetNVM_IlluminationData.Get_BsShare_VisteonPartNumber
          OA_rp_GetNVM_IlluminationData_Get_BsShare_VisteonPCBPartNumber: operation=rp_GetNVM_IlluminationData.Get_BsShare_VisteonPCBPartNumber
          OA_rp_GetNVM_IlluminationData_Get_BsShare_ProductSerialNumber: operation=rp_GetNVM_IlluminationData.Get_BsShare_ProductSerialNumber
          OA_rp_GetNVM_IlluminationData_Get_BsShare_PCBSerialNumber: operation=rp_GetNVM_IlluminationData.Get_BsShare_PCBSerialNumber
          OA_rp_GetNVM_IlluminationData_Get_BsShare_SMTManufacturingDate: operation=rp_GetNVM_IlluminationData.Get_BsShare_SMTManufacturingDate
          OA_rp_GetNVM_IlluminationData_Get_BsShare_AssemblyManufacturingDate: operation=rp_GetNVM_IlluminationData.Get_BsShare_AssemblyManufacturingDate
          OA_rp_GetNVM_IlluminationData_Get_BsShare_SMTPlantNumber: operation=rp_GetNVM_IlluminationData.Get_BsShare_SMTPlantNumber
          OA_rp_GetNVM_IlluminationData_Get_BsShare_AssemblyPlantNumber: operation=rp_GetNVM_IlluminationData.Get_BsShare_AssemblyPlantNumber
          OA_rp_GetNVM_IlluminationData_Get_BsShare_HWModification: operation=rp_GetNVM_IlluminationData.Get_BsShare_HWModification
          OA_rp_GetNVM_IlluminationData_Get_BsShare_VisMeet_Element: operation=rp_GetNVM_IlluminationData.Get_BsShare_VisMeet_Element
          OA_rp_GetNVM_IlluminationData_Get_BsShare_VisMeet_EOLEntry_Element: operation=rp_GetNVM_IlluminationData.Get_BsShare_VisMeet_EOLEntry_Element
          OA_rp_GetNVM_IlluminationData_Get_BsShare_VehicleConfig_Element: operation=rp_GetNVM_IlluminationData.Get_BsShare_VehicleConfig_Element
          OA_rp_GetNVM_IlluminationData_Get_BsConst_SpeedoGauge_Element: operation=rp_GetNVM_IlluminationData.Get_BsConst_SpeedoGauge_Element
          OA_rp_GetNVM_IlluminationData_Get_BsConst_TachoGauge_Element: operation=rp_GetNVM_IlluminationData.Get_BsConst_TachoGauge_Element
          OA_rp_GetNVM_IlluminationData_Get_BsConst_FuelGauge_Element: operation=rp_GetNVM_IlluminationData.Get_BsConst_FuelGauge_Element
          OA_rp_GetNVM_IlluminationData_Get_BsConst_TempGauge_Element: operation=rp_GetNVM_IlluminationData.Get_BsConst_TempGauge_Element
          OA_rp_GetNVM_IlluminationData_Get_BsConst_PowerGauge_Element: operation=rp_GetNVM_IlluminationData.Get_BsConst_PowerGauge_Element
          OA_rp_GetNVM_IlluminationData_Get_BsConst_OilGauge_Element: operation=rp_GetNVM_IlluminationData.Get_BsConst_OilGauge_Element
          OA_rp_GetNVM_IlluminationData_Get_BsConst_TripComputer_Element: operation=rp_GetNVM_IlluminationData.Get_BsConst_TripComputer_Element
          OA_rp_GetNVM_IlluminationData_Get_BsConst_Compensation_Line_Slope_m: operation=rp_GetNVM_IlluminationData.Get_BsConst_Compensation_Line_Slope_m
          OA_rp_GetNVM_IlluminationData_Get_BsConst_Compensation_Line_Shift_b: operation=rp_GetNVM_IlluminationData.Get_BsConst_Compensation_Line_Shift_b
          OA_rp_GetNVM_IlluminationData_Get_BsConst_Lookup_Curve_HotSpot_Coef_X: operation=rp_GetNVM_IlluminationData.Get_BsConst_Lookup_Curve_HotSpot_Coef_X
          OA_rp_GetNVM_IlluminationData_Get_BsConst_Lookup_Curve_HotSpot_Coef_Y: operation=rp_GetNVM_IlluminationData.Get_BsConst_Lookup_Curve_HotSpot_Coef_Y
          OA_rp_GetNVM_IlluminationData_Get_BsConst_Temp_Threshold_Hysteresis_Derating: operation=rp_GetNVM_IlluminationData.Get_BsConst_Temp_Threshold_Hysteresis_Derating
          OA_rp_GetNVM_IlluminationData_Get_BsConst_Derating_Backlight_Disable: operation=rp_GetNVM_IlluminationData.Get_BsConst_Derating_Backlight_Disable
          OA_rp_GetNVM_IlluminationData_Get_BsConst_Temperature_Sensor_Conv: operation=rp_GetNVM_IlluminationData.Get_BsConst_Temperature_Sensor_Conv
          OA_rp_GetNVM_IlluminationData_Get_BsConst_PCB_Temperature_Sensor_Conv: operation=rp_GetNVM_IlluminationData.Get_BsConst_PCB_Temperature_Sensor_Conv
          OA_rp_GetNVM_IlluminationData_Get_BsConst_Display_Illum_Max_Level: operation=rp_GetNVM_IlluminationData.Get_BsConst_Display_Illum_Max_Level
          OA_rp_GetNVM_IlluminationData_Get_BsConst_PWM_boost_bypass_duty: operation=rp_GetNVM_IlluminationData.Get_BsConst_PWM_boost_bypass_duty
          OA_rp_GetNVM_IlluminationData_Get_BsConst_BsConst_Illumination_ReservedByte: operation=rp_GetNVM_IlluminationData.Get_BsConst_BsConst_Illumination_ReservedByte
          OA_rp_GetNVM_IlluminationData_Get_BsConst_Compensation_Line_Slope_m_SafeCopy1: operation=rp_GetNVM_IlluminationData.Get_BsConst_Compensation_Line_Slope_m_SafeCopy1
          OA_rp_GetNVM_IlluminationData_Get_BsConst_Compensation_Line_Shift_b_SafeCopy1: operation=rp_GetNVM_IlluminationData.Get_BsConst_Compensation_Line_Shift_b_SafeCopy1
          OA_rp_GetNVM_IlluminationData_Get_BsConst_Lookup_Curve_HotSpot_Coef_X_SafeCopy1: operation=rp_GetNVM_IlluminationData.Get_BsConst_Lookup_Curve_HotSpot_Coef_X_SafeCopy1
          OA_rp_GetNVM_IlluminationData_Get_BsConst_Lookup_Curve_HotSpot_Coef_Y_SafeCopy1: operation=rp_GetNVM_IlluminationData.Get_BsConst_Lookup_Curve_HotSpot_Coef_Y_SafeCopy1
          OA_rp_GetNVM_IlluminationData_Get_BsConst_Temp_Threshold_Hysteresis_Derating_SafeCopy1: operation=rp_GetNVM_IlluminationData.Get_BsConst_Temp_Threshold_Hysteresis_Derating_SafeCopy1
          OA_rp_GetNVM_IlluminationData_Get_BsConst_Derating_Backlight_Disable_SafeCopy1: operation=rp_GetNVM_IlluminationData.Get_BsConst_Derating_Backlight_Disable_SafeCopy1
          OA_rp_GetNVM_IlluminationData_Get_BsConst_Temperature_Sensor_Conv_SafeCopy1: operation=rp_GetNVM_IlluminationData.Get_BsConst_Temperature_Sensor_Conv_SafeCopy1
          OA_rp_GetNVM_IlluminationData_Get_BsConst_PCB_Temperature_Sensor_Conv_SafeCopy1: operation=rp_GetNVM_IlluminationData.Get_BsConst_PCB_Temperature_Sensor_Conv_SafeCopy1
          OA_rp_GetNVM_IlluminationData_Get_BsConst_Display_Illum_Max_Level_SafeCopy1: operation=rp_GetNVM_IlluminationData.Get_BsConst_Display_Illum_Max_Level_SafeCopy1
          OA_rp_GetNVM_IlluminationData_Get_BsConst_PWM_boost_bypass_duty_SafeCopy1: operation=rp_GetNVM_IlluminationData.Get_BsConst_PWM_boost_bypass_duty_SafeCopy1
          OA_rp_GetNVM_IlluminationData_Get_BsConst_BsConst_Illumination_ReservedByte_SafeCopy1: operation=rp_GetNVM_IlluminationData.Get_BsConst_BsConst_Illumination_ReservedByte_SafeCopy1
          OA_rp_GetNVM_IlluminationData_Get_BsConst_Compensation_Line_Slope_m_SafeCopy2: operation=rp_GetNVM_IlluminationData.Get_BsConst_Compensation_Line_Slope_m_SafeCopy2
          OA_rp_GetNVM_IlluminationData_Get_BsConst_Compensation_Line_Shift_b_SafeCopy2: operation=rp_GetNVM_IlluminationData.Get_BsConst_Compensation_Line_Shift_b_SafeCopy2
          OA_rp_GetNVM_IlluminationData_Get_BsConst_Lookup_Curve_HotSpot_Coef_X_SafeCopy2: operation=rp_GetNVM_IlluminationData.Get_BsConst_Lookup_Curve_HotSpot_Coef_X_SafeCopy2
          OA_rp_GetNVM_IlluminationData_Get_BsConst_Lookup_Curve_HotSpot_Coef_Y_SafeCopy2: operation=rp_GetNVM_IlluminationData.Get_BsConst_Lookup_Curve_HotSpot_Coef_Y_SafeCopy2
          OA_rp_GetNVM_IlluminationData_Get_BsConst_Temp_Threshold_Hysteresis_Derating_SafeCopy2: operation=rp_GetNVM_IlluminationData.Get_BsConst_Temp_Threshold_Hysteresis_Derating_SafeCopy2
          OA_rp_GetNVM_IlluminationData_Get_BsConst_Derating_Backlight_Disable_SafeCopy2: operation=rp_GetNVM_IlluminationData.Get_BsConst_Derating_Backlight_Disable_SafeCopy2
          OA_rp_GetNVM_IlluminationData_Get_BsConst_Temperature_Sensor_Conv_SafeCopy2: operation=rp_GetNVM_IlluminationData.Get_BsConst_Temperature_Sensor_Conv_SafeCopy2
          OA_rp_GetNVM_IlluminationData_Get_BsConst_PCB_Temperature_Sensor_Conv_SafeCopy2: operation=rp_GetNVM_IlluminationData.Get_BsConst_PCB_Temperature_Sensor_Conv_SafeCopy2
          OA_rp_GetNVM_IlluminationData_Get_BsConst_Display_Illum_Max_Level_SafeCopy2: operation=rp_GetNVM_IlluminationData.Get_BsConst_Display_Illum_Max_Level_SafeCopy2
          OA_rp_GetNVM_IlluminationData_Get_BsConst_PWM_boost_bypass_duty_SafeCopy2: operation=rp_GetNVM_IlluminationData.Get_BsConst_PWM_boost_bypass_duty_SafeCopy2
          OA_rp_GetNVM_IlluminationData_Get_BsConst_BsConst_Illumination_ReservedByte_SafeCopy2: operation=rp_GetNVM_IlluminationData.Get_BsConst_BsConst_Illumination_ReservedByte_SafeCopy2
          OA_rp_GetNVM_IlluminationData_Get_BsConst_Audio_Element: operation=rp_GetNVM_IlluminationData.Get_BsConst_Audio_Element
          OA_rp_GetNVM_IlluminationData_Get_BsConst_Warning_Element: operation=rp_GetNVM_IlluminationData.Get_BsConst_Warning_Element
          OA_rp_GetNVM_IlluminationData_Get_BsConst_RealTimeClock_Element: operation=rp_GetNVM_IlluminationData.Get_BsConst_RealTimeClock_Element
          OA_rp_GetNVM_IlluminationData_Get_BsConst_Communication_Element: operation=rp_GetNVM_IlluminationData.Get_BsConst_Communication_Element
          OA_rp_GetNVM_IlluminationData_Get_BsConst_Power_Element: operation=rp_GetNVM_IlluminationData.Get_BsConst_Power_Element
          OA_rp_GetNVM_IlluminationData_Get_BsConst_ServiceReminder_Element: operation=rp_GetNVM_IlluminationData.Get_BsConst_ServiceReminder_Element
          OA_rp_GetNVM_IlluminationData_Get_BsConst_EngOffTimer_Element: operation=rp_GetNVM_IlluminationData.Get_BsConst_EngOffTimer_Element
          OA_rp_GetNVM_IlluminationData_Get_BsCys_Certicificate_Element: operation=rp_GetNVM_IlluminationData.Get_BsCys_Certicificate_Element
          OA_rp_GetNVM_IlluminationData_Get_RefCys_Certicificate_Element: operation=rp_GetNVM_IlluminationData.Get_RefCys_Certicificate_Element
          OA_rp_GetNVM_IlluminationData_Get_RefCys_Certicificate1_Element: operation=rp_GetNVM_IlluminationData.Get_RefCys_Certicificate1_Element
          OA_rp_GetNVM_IlluminationData_Get_BsRt_Odometer_Element: operation=rp_GetNVM_IlluminationData.Get_BsRt_Odometer_Element
          OA_rp_GetNVM_IlluminationData_Get_BsRt_SpeedoGauge_Element: operation=rp_GetNVM_IlluminationData.Get_BsRt_SpeedoGauge_Element
          OA_rp_GetNVM_IlluminationData_Get_BsRt_TachoGauge_Element: operation=rp_GetNVM_IlluminationData.Get_BsRt_TachoGauge_Element
          OA_rp_GetNVM_IlluminationData_Get_BsRt_FuelGauge_Element: operation=rp_GetNVM_IlluminationData.Get_BsRt_FuelGauge_Element
          OA_rp_GetNVM_IlluminationData_Get_BsRt_TempGauge_Element: operation=rp_GetNVM_IlluminationData.Get_BsRt_TempGauge_Element
          OA_rp_GetNVM_IlluminationData_Get_BsRt_PowerGauge_Element: operation=rp_GetNVM_IlluminationData.Get_BsRt_PowerGauge_Element
          OA_rp_GetNVM_IlluminationData_Get_BsRt_OilGauge_Element: operation=rp_GetNVM_IlluminationData.Get_BsRt_OilGauge_Element
          OA_rp_GetNVM_IlluminationData_Get_BsRt_TripComputer_Element: operation=rp_GetNVM_IlluminationData.Get_BsRt_TripComputer_Element
          OA_rp_GetNVM_IlluminationData_Get_BsRt_Warning_Element: operation=rp_GetNVM_IlluminationData.Get_BsRt_Warning_Element
          OA_rp_GetNVM_IlluminationData_Get_BsRt_RealTimeClock_Element: operation=rp_GetNVM_IlluminationData.Get_BsRt_RealTimeClock_Element
          OA_rp_GetNVM_IlluminationData_Get_BsRt_Personalization_Element: operation=rp_GetNVM_IlluminationData.Get_BsRt_Personalization_Element
          OA_rp_GetNVM_IlluminationData_Get_BsRt_Illumination_Element: operation=rp_GetNVM_IlluminationData.Get_BsRt_Illumination_Element
          OA_rp_GetNVM_IlluminationData_Get_BsRt_CusDlt_Element: operation=rp_GetNVM_IlluminationData.Get_BsRt_CusDlt_Element
          OA_rp_GetNVM_IlluminationData_Get_BsReten_Odometer_Element: operation=rp_GetNVM_IlluminationData.Get_BsReten_Odometer_Element
          OA_rp_GetNVM_IlluminationData_Get_BsReten_Gauges_Element: operation=rp_GetNVM_IlluminationData.Get_BsReten_Gauges_Element
          OA_rp_GetNVM_IlluminationData_Get_BsReten_Tripcomputer_Element: operation=rp_GetNVM_IlluminationData.Get_BsReten_Tripcomputer_Element
          OA_rp_GetNVM_IlluminationData_Get_BsReten_Illumination_Element: operation=rp_GetNVM_IlluminationData.Get_BsReten_Illumination_Element
          OA_rp_GetNVM_IlluminationData_Get_BsReten_Audio_Element: operation=rp_GetNVM_IlluminationData.Get_BsReten_Audio_Element
          OA_rp_GetNVM_IlluminationData_Get_BsReten_Warning_Element: operation=rp_GetNVM_IlluminationData.Get_BsReten_Warning_Element
          OA_rp_GetNVM_IlluminationData_Get_BsReten_RealTimeClock_Element: operation=rp_GetNVM_IlluminationData.Get_BsReten_RealTimeClock_Element
          OA_rp_GetNVM_IlluminationData_Get_BsReten_Communication_Element: operation=rp_GetNVM_IlluminationData.Get_BsReten_Communication_Element
          OA_rp_GetNVM_IlluminationData_Get_BsReten_Personalization_Element: operation=rp_GetNVM_IlluminationData.Get_BsReten_Personalization_Element
          OA_rp_GetNVM_IlluminationData_Get_BsReten_Power_Element: operation=rp_GetNVM_IlluminationData.Get_BsReten_Power_Element
          OA_rp_GetNVM_IlluminationData_Get_BsReten_Display_Element: operation=rp_GetNVM_IlluminationData.Get_BsReten_Display_Element
          OA_rp_GetNVM_IlluminationData_Get_BsDiag_ErrorRecord_Element: operation=rp_GetNVM_IlluminationData.Get_BsDiag_ErrorRecord_Element
          OA_rp_GetNVM_IlluminationData_Get_BsDiag_Dtc_Element: operation=rp_GetNVM_IlluminationData.Get_BsDiag_Dtc_Element
          OA_rp_Get_Variant_Cfg_Get_Variant_Config_State: operation=rp_Get_Variant_Cfg.Get_Variant_Config_State
          OA_rp_ILL_ReadyToSleep_SWCSleepStatus: operation=rp_ILL_ReadyToSleep.SWCSleepStatus
          OA_rp_IoHwAb_ADC_GetAsyncRawAdc: operation=rp_IoHwAb_ADC.GetAsyncRawAdc
          OA_rp_IoHwAb_ADC_GetSyncRawAdc: operation=rp_IoHwAb_ADC.GetSyncRawAdc
          OA_rp_IoHwAb_ADC_GetProcessedAdc: operation=rp_IoHwAb_ADC.GetProcessedAdc
          OA_rp_PwmWithTime_GetPwmWithTime: operation=rp_PwmWithTime.GetPwmWithTime
          OA_rp_PwmWithTimeExp_GetPwmWithTimeExp: operation=rp_PwmWithTimeExp.GetPwmWithTimeExp
          OA_rp_SetNVM_IlluminationData_Set_BsShare_SwUpdReflash_Element: operation=rp_SetNVM_IlluminationData.Set_BsShare_SwUpdReflash_Element
          OA_rp_SetNVM_IlluminationData_Set_BsShare_SwUpdFotaMode_Element: operation=rp_SetNVM_IlluminationData.Set_BsShare_SwUpdFotaMode_Element
          OA_rp_SetNVM_IlluminationData_Set_BsShare_SwUpdFotaFinPrint_Element: operation=rp_SetNVM_IlluminationData.Set_BsShare_SwUpdFotaFinPrint_Element
          OA_rp_SetNVM_IlluminationData_Set_BsShare_SwUpdFotaStatus_Element: operation=rp_SetNVM_IlluminationData.Set_BsShare_SwUpdFotaStatus_Element
          OA_rp_SetNVM_IlluminationData_Set_BsShare_SwUpdFotadecrypt_Element: operation=rp_SetNVM_IlluminationData.Set_BsShare_SwUpdFotadecrypt_Element
          OA_rp_SetNVM_IlluminationData_Set_BsShare_EcuPartNumber_Element: operation=rp_SetNVM_IlluminationData.Set_BsShare_EcuPartNumber_Element
          OA_rp_SetNVM_IlluminationData_Set_BsShare_VisteonPartNumber: operation=rp_SetNVM_IlluminationData.Set_BsShare_VisteonPartNumber
          OA_rp_SetNVM_IlluminationData_Set_BsShare_VisteonPCBPartNumber: operation=rp_SetNVM_IlluminationData.Set_BsShare_VisteonPCBPartNumber
          OA_rp_SetNVM_IlluminationData_Set_BsShare_ProductSerialNumber: operation=rp_SetNVM_IlluminationData.Set_BsShare_ProductSerialNumber
          OA_rp_SetNVM_IlluminationData_Set_BsShare_PCBSerialNumber: operation=rp_SetNVM_IlluminationData.Set_BsShare_PCBSerialNumber
          OA_rp_SetNVM_IlluminationData_Set_BsShare_SMTManufacturingDate: operation=rp_SetNVM_IlluminationData.Set_BsShare_SMTManufacturingDate
          OA_rp_SetNVM_IlluminationData_Set_BsShare_AssemblyManufacturingDate: operation=rp_SetNVM_IlluminationData.Set_BsShare_AssemblyManufacturingDate
          OA_rp_SetNVM_IlluminationData_Set_BsShare_SMTPlantNumber: operation=rp_SetNVM_IlluminationData.Set_BsShare_SMTPlantNumber
          OA_rp_SetNVM_IlluminationData_Set_BsShare_AssemblyPlantNumber: operation=rp_SetNVM_IlluminationData.Set_BsShare_AssemblyPlantNumber
          OA_rp_SetNVM_IlluminationData_Set_BsShare_HWModification: operation=rp_SetNVM_IlluminationData.Set_BsShare_HWModification
          OA_rp_SetNVM_IlluminationData_Set_BsShare_VisMeet_Element: operation=rp_SetNVM_IlluminationData.Set_BsShare_VisMeet_Element
          OA_rp_SetNVM_IlluminationData_Set_BsShare_VisMeet_EOLEntry_Element: operation=rp_SetNVM_IlluminationData.Set_BsShare_VisMeet_EOLEntry_Element
          OA_rp_SetNVM_IlluminationData_Set_BsShare_VehicleConfig_Element: operation=rp_SetNVM_IlluminationData.Set_BsShare_VehicleConfig_Element
          OA_rp_SetNVM_IlluminationData_Set_BsConst_SpeedoGauge_Element: operation=rp_SetNVM_IlluminationData.Set_BsConst_SpeedoGauge_Element
          OA_rp_SetNVM_IlluminationData_Set_BsConst_TachoGauge_Element: operation=rp_SetNVM_IlluminationData.Set_BsConst_TachoGauge_Element
          OA_rp_SetNVM_IlluminationData_Set_BsConst_FuelGauge_Element: operation=rp_SetNVM_IlluminationData.Set_BsConst_FuelGauge_Element
          OA_rp_SetNVM_IlluminationData_Set_BsConst_TempGauge_Element: operation=rp_SetNVM_IlluminationData.Set_BsConst_TempGauge_Element
          OA_rp_SetNVM_IlluminationData_Set_BsConst_PowerGauge_Element: operation=rp_SetNVM_IlluminationData.Set_BsConst_PowerGauge_Element
          OA_rp_SetNVM_IlluminationData_Set_BsConst_OilGauge_Element: operation=rp_SetNVM_IlluminationData.Set_BsConst_OilGauge_Element
          OA_rp_SetNVM_IlluminationData_Set_BsConst_TripComputer_Element: operation=rp_SetNVM_IlluminationData.Set_BsConst_TripComputer_Element
          OA_rp_SetNVM_IlluminationData_Set_BsConst_Compensation_Line_Slope_m: operation=rp_SetNVM_IlluminationData.Set_BsConst_Compensation_Line_Slope_m
          OA_rp_SetNVM_IlluminationData_Set_BsConst_Compensation_Line_Shift_b: operation=rp_SetNVM_IlluminationData.Set_BsConst_Compensation_Line_Shift_b
          OA_rp_SetNVM_IlluminationData_Set_BsConst_Lookup_Curve_HotSpot_Coef_X: operation=rp_SetNVM_IlluminationData.Set_BsConst_Lookup_Curve_HotSpot_Coef_X
          OA_rp_SetNVM_IlluminationData_Set_BsConst_Lookup_Curve_HotSpot_Coef_Y: operation=rp_SetNVM_IlluminationData.Set_BsConst_Lookup_Curve_HotSpot_Coef_Y
          OA_rp_SetNVM_IlluminationData_Set_BsConst_Temp_Threshold_Hysteresis_Derating: operation=rp_SetNVM_IlluminationData.Set_BsConst_Temp_Threshold_Hysteresis_Derating
          OA_rp_SetNVM_IlluminationData_Set_BsConst_Derating_Backlight_Disable: operation=rp_SetNVM_IlluminationData.Set_BsConst_Derating_Backlight_Disable
          OA_rp_SetNVM_IlluminationData_Set_BsConst_Temperature_Sensor_Conv: operation=rp_SetNVM_IlluminationData.Set_BsConst_Temperature_Sensor_Conv
          OA_rp_SetNVM_IlluminationData_Set_BsConst_PCB_Temperature_Sensor_Conv: operation=rp_SetNVM_IlluminationData.Set_BsConst_PCB_Temperature_Sensor_Conv
          OA_rp_SetNVM_IlluminationData_Set_BsConst_Display_Illum_Max_Level: operation=rp_SetNVM_IlluminationData.Set_BsConst_Display_Illum_Max_Level
          OA_rp_SetNVM_IlluminationData_Set_BsConst_PWM_boost_bypass_duty: operation=rp_SetNVM_IlluminationData.Set_BsConst_PWM_boost_bypass_duty
          OA_rp_SetNVM_IlluminationData_Set_BsConst_BsConst_Illumination_ReservedByte: operation=rp_SetNVM_IlluminationData.Set_BsConst_BsConst_Illumination_ReservedByte
          OA_rp_SetNVM_IlluminationData_Set_BsConst_Compensation_Line_Slope_m_SafeCopy1: operation=rp_SetNVM_IlluminationData.Set_BsConst_Compensation_Line_Slope_m_SafeCopy1
          OA_rp_SetNVM_IlluminationData_Set_BsConst_Compensation_Line_Shift_b_SafeCopy1: operation=rp_SetNVM_IlluminationData.Set_BsConst_Compensation_Line_Shift_b_SafeCopy1
          OA_rp_SetNVM_IlluminationData_Set_BsConst_Lookup_Curve_HotSpot_Coef_X_SafeCopy1: operation=rp_SetNVM_IlluminationData.Set_BsConst_Lookup_Curve_HotSpot_Coef_X_SafeCopy1
          OA_rp_SetNVM_IlluminationData_Set_BsConst_Lookup_Curve_HotSpot_Coef_Y_SafeCopy1: operation=rp_SetNVM_IlluminationData.Set_BsConst_Lookup_Curve_HotSpot_Coef_Y_SafeCopy1
          OA_rp_SetNVM_IlluminationData_Set_BsConst_Temp_Threshold_Hysteresis_Derating_SafeCopy1: operation=rp_SetNVM_IlluminationData.Set_BsConst_Temp_Threshold_Hysteresis_Derating_SafeCopy1
          OA_rp_SetNVM_IlluminationData_Set_BsConst_Derating_Backlight_Disable_SafeCopy1: operation=rp_SetNVM_IlluminationData.Set_BsConst_Derating_Backlight_Disable_SafeCopy1
          OA_rp_SetNVM_IlluminationData_Set_BsConst_Temperature_Sensor_Conv_SafeCopy1: operation=rp_SetNVM_IlluminationData.Set_BsConst_Temperature_Sensor_Conv_SafeCopy1
          OA_rp_SetNVM_IlluminationData_Set_BsConst_PCB_Temperature_Sensor_Conv_SafeCopy1: operation=rp_SetNVM_IlluminationData.Set_BsConst_PCB_Temperature_Sensor_Conv_SafeCopy1
          OA_rp_SetNVM_IlluminationData_Set_BsConst_Display_Illum_Max_Level_SafeCopy1: operation=rp_SetNVM_IlluminationData.Set_BsConst_Display_Illum_Max_Level_SafeCopy1
          OA_rp_SetNVM_IlluminationData_Set_BsConst_PWM_boost_bypass_duty_SafeCopy1: operation=rp_SetNVM_IlluminationData.Set_BsConst_PWM_boost_bypass_duty_SafeCopy1
          OA_rp_SetNVM_IlluminationData_Set_BsConst_BsConst_Illumination_ReservedByte_SafeCopy1: operation=rp_SetNVM_IlluminationData.Set_BsConst_BsConst_Illumination_ReservedByte_SafeCopy1
          OA_rp_SetNVM_IlluminationData_Set_BsConst_Compensation_Line_Slope_m_SafeCopy2: operation=rp_SetNVM_IlluminationData.Set_BsConst_Compensation_Line_Slope_m_SafeCopy2
          OA_rp_SetNVM_IlluminationData_Set_BsConst_Compensation_Line_Shift_b_SafeCopy2: operation=rp_SetNVM_IlluminationData.Set_BsConst_Compensation_Line_Shift_b_SafeCopy2
          OA_rp_SetNVM_IlluminationData_Set_BsConst_Lookup_Curve_HotSpot_Coef_X_SafeCopy2: operation=rp_SetNVM_IlluminationData.Set_BsConst_Lookup_Curve_HotSpot_Coef_X_SafeCopy2
          OA_rp_SetNVM_IlluminationData_Set_BsConst_Lookup_Curve_HotSpot_Coef_Y_SafeCopy2: operation=rp_SetNVM_IlluminationData.Set_BsConst_Lookup_Curve_HotSpot_Coef_Y_SafeCopy2
          OA_rp_SetNVM_IlluminationData_Set_BsConst_Temp_Threshold_Hysteresis_Derating_SafeCopy2: operation=rp_SetNVM_IlluminationData.Set_BsConst_Temp_Threshold_Hysteresis_Derating_SafeCopy2
          OA_rp_SetNVM_IlluminationData_Set_BsConst_Derating_Backlight_Disable_SafeCopy2: operation=rp_SetNVM_IlluminationData.Set_BsConst_Derating_Backlight_Disable_SafeCopy2
          OA_rp_SetNVM_IlluminationData_Set_BsConst_Temperature_Sensor_Conv_SafeCopy2: operation=rp_SetNVM_IlluminationData.Set_BsConst_Temperature_Sensor_Conv_SafeCopy2
          OA_rp_SetNVM_IlluminationData_Set_BsConst_PCB_Temperature_Sensor_Conv_SafeCopy2: operation=rp_SetNVM_IlluminationData.Set_BsConst_PCB_Temperature_Sensor_Conv_SafeCopy2
          OA_rp_SetNVM_IlluminationData_Set_BsConst_Display_Illum_Max_Level_SafeCopy2: operation=rp_SetNVM_IlluminationData.Set_BsConst_Display_Illum_Max_Level_SafeCopy2
          OA_rp_SetNVM_IlluminationData_Set_BsConst_PWM_boost_bypass_duty_SafeCopy2: operation=rp_SetNVM_IlluminationData.Set_BsConst_PWM_boost_bypass_duty_SafeCopy2
          OA_rp_SetNVM_IlluminationData_Set_BsConst_BsConst_Illumination_ReservedByte_SafeCopy2: operation=rp_SetNVM_IlluminationData.Set_BsConst_BsConst_Illumination_ReservedByte_SafeCopy2
          OA_rp_SetNVM_IlluminationData_Set_BsConst_Audio_Element: operation=rp_SetNVM_IlluminationData.Set_BsConst_Audio_Element
          OA_rp_SetNVM_IlluminationData_Set_BsConst_Warning_Element: operation=rp_SetNVM_IlluminationData.Set_BsConst_Warning_Element
          OA_rp_SetNVM_IlluminationData_Set_BsConst_RealTimeClock_Element: operation=rp_SetNVM_IlluminationData.Set_BsConst_RealTimeClock_Element
          OA_rp_SetNVM_IlluminationData_Set_BsConst_Communication_Element: operation=rp_SetNVM_IlluminationData.Set_BsConst_Communication_Element
          OA_rp_SetNVM_IlluminationData_Set_BsConst_Power_Element: operation=rp_SetNVM_IlluminationData.Set_BsConst_Power_Element
          OA_rp_SetNVM_IlluminationData_Set_BsConst_ServiceReminder_Element: operation=rp_SetNVM_IlluminationData.Set_BsConst_ServiceReminder_Element
          OA_rp_SetNVM_IlluminationData_Set_BsConst_EngOffTimer_Element: operation=rp_SetNVM_IlluminationData.Set_BsConst_EngOffTimer_Element
          OA_rp_SetNVM_IlluminationData_Set_BsCys_Certicificate_Element: operation=rp_SetNVM_IlluminationData.Set_BsCys_Certicificate_Element
          OA_rp_SetNVM_IlluminationData_Set_RefCys_Certicificate_Element: operation=rp_SetNVM_IlluminationData.Set_RefCys_Certicificate_Element
          OA_rp_SetNVM_IlluminationData_Set_RefCys_Certicificate1_Element: operation=rp_SetNVM_IlluminationData.Set_RefCys_Certicificate1_Element
          OA_rp_SetNVM_IlluminationData_Set_BsRt_Odometer_Element: operation=rp_SetNVM_IlluminationData.Set_BsRt_Odometer_Element
          OA_rp_SetNVM_IlluminationData_Set_BsRt_SpeedoGauge_Element: operation=rp_SetNVM_IlluminationData.Set_BsRt_SpeedoGauge_Element
          OA_rp_SetNVM_IlluminationData_Set_BsRt_TachoGauge_Element: operation=rp_SetNVM_IlluminationData.Set_BsRt_TachoGauge_Element
          OA_rp_SetNVM_IlluminationData_Set_BsRt_FuelGauge_Element: operation=rp_SetNVM_IlluminationData.Set_BsRt_FuelGauge_Element
          OA_rp_SetNVM_IlluminationData_Set_BsRt_TempGauge_Element: operation=rp_SetNVM_IlluminationData.Set_BsRt_TempGauge_Element
          OA_rp_SetNVM_IlluminationData_Set_BsRt_PowerGauge_Element: operation=rp_SetNVM_IlluminationData.Set_BsRt_PowerGauge_Element
          OA_rp_SetNVM_IlluminationData_Set_BsRt_OilGauge_Element: operation=rp_SetNVM_IlluminationData.Set_BsRt_OilGauge_Element
          OA_rp_SetNVM_IlluminationData_Set_BsRt_TripComputer_Element: operation=rp_SetNVM_IlluminationData.Set_BsRt_TripComputer_Element
          OA_rp_SetNVM_IlluminationData_Set_BsRt_Warning_Element: operation=rp_SetNVM_IlluminationData.Set_BsRt_Warning_Element
          OA_rp_SetNVM_IlluminationData_Set_BsRt_RealTimeClock_Element: operation=rp_SetNVM_IlluminationData.Set_BsRt_RealTimeClock_Element
          OA_rp_SetNVM_IlluminationData_Set_BsRt_Personalization_Element: operation=rp_SetNVM_IlluminationData.Set_BsRt_Personalization_Element
          OA_rp_SetNVM_IlluminationData_Set_BsRt_Illumination_Element: operation=rp_SetNVM_IlluminationData.Set_BsRt_Illumination_Element
          OA_rp_SetNVM_IlluminationData_Set_BsRt_CusDlt_Element: operation=rp_SetNVM_IlluminationData.Set_BsRt_CusDlt_Element
          OA_rp_SetNVM_IlluminationData_Set_BsReten_Odometer_Element: operation=rp_SetNVM_IlluminationData.Set_BsReten_Odometer_Element
          OA_rp_SetNVM_IlluminationData_Set_BsReten_Gauges_Element: operation=rp_SetNVM_IlluminationData.Set_BsReten_Gauges_Element
          OA_rp_SetNVM_IlluminationData_Set_BsReten_Tripcomputer_Element: operation=rp_SetNVM_IlluminationData.Set_BsReten_Tripcomputer_Element
          OA_rp_SetNVM_IlluminationData_Set_BsReten_Illumination_Element: operation=rp_SetNVM_IlluminationData.Set_BsReten_Illumination_Element
          OA_rp_SetNVM_IlluminationData_Set_BsReten_Audio_Element: operation=rp_SetNVM_IlluminationData.Set_BsReten_Audio_Element
          OA_rp_SetNVM_IlluminationData_Set_BsReten_Warning_Element: operation=rp_SetNVM_IlluminationData.Set_BsReten_Warning_Element
          OA_rp_SetNVM_IlluminationData_Set_BsReten_RealTimeClock_Element: operation=rp_SetNVM_IlluminationData.Set_BsReten_RealTimeClock_Element
          OA_rp_SetNVM_IlluminationData_Set_BsReten_Communication_Element: operation=rp_SetNVM_IlluminationData.Set_BsReten_Communication_Element
          OA_rp_SetNVM_IlluminationData_Set_BsReten_Personalization_Element: operation=rp_SetNVM_IlluminationData.Set_BsReten_Personalization_Element
          OA_rp_SetNVM_IlluminationData_Set_BsReten_Power_Element: operation=rp_SetNVM_IlluminationData.Set_BsReten_Power_Element
          OA_rp_SetNVM_IlluminationData_Set_BsReten_Display_Element: operation=rp_SetNVM_IlluminationData.Set_BsReten_Display_Element
          OA_rp_SetNVM_IlluminationData_Set_BsDiag_ErrorRecord_Element: operation=rp_SetNVM_IlluminationData.Set_BsDiag_ErrorRecord_Element
          OA_rp_SetNVM_IlluminationData_Set_BsDiag_Dtc_Element: operation=rp_SetNVM_IlluminationData.Set_BsDiag_Dtc_Element
          OA_rp_UpdatePwmDirect_GetPwmDirect: operation=rp_UpdatePwmDirect.GetPwmDirect
          OA_rp_Variant_Status_GetVariant_Status: operation=rp_Variant_Status.GetVariant_Status
